VERSION "HNNBNNNYNNNNNNNNNNNNNNNNNNNNNNNNNNNNNNNNNN/4/%%%/4/'%**4NNN///"

NS_ :

BS_:

BU_: BAP_Tester BedienDisp_vo BedienSG_hi CGS DDA Gateway Gateway_PAG GurtMikrofon OTA_FC ZR_High ZR_LIMU ZR_MIB_TOP_ab_Gen3 ZR_Standard

BO_ 2589283609 UGDO_02: 8 Gateway
 SG_ UGDO_LED_Code_01 : 0|5@1+ (1.0,0.0) [0.0|31] ""  Vector__XXX
 SG_ UGDO_Function_01 : 5|3@1+ (1.0,0.0) [0.0|7] ""  Vector__XXX
 SG_ UGDO_Failure_Antenne : 8|1@1+ (1.0,0.0) [0.0|1] ""  Vector__XXX
 SG_ UGDO_Failure_Codierung : 9|1@1+ (1.0,0.0) [0.0|1] ""  Vector__XXX
 SG_ UGDO_Failure_Hardware : 10|1@1+ (1.0,0.0) [0.0|1] ""  Vector__XXX
 SG_ UGDO_ResponseError : 16|1@1+ (1.0,0.0) [0.0|1] ""  Vector__XXX
 SG_ UGDO_Channel_1 : 24|1@1+ (1.0,0.0) [0.0|1] ""  DDA
 SG_ UGDO_Channel_2 : 25|1@1+ (1.0,0.0) [0.0|1] ""  DDA
 SG_ UGDO_Channel_3 : 26|1@1+ (1.0,0.0) [0.0|1] ""  DDA
 SG_ UGDO_Channel_4 : 27|1@1+ (1.0,0.0) [0.0|1] ""  DDA
 SG_ UGDO_Channel_5 : 28|1@1+ (1.0,0.0) [0.0|1] ""  DDA
 SG_ UGDO_Channel_6 : 29|1@1+ (1.0,0.0) [0.0|1] ""  DDA
 SG_ UGDO_Channel_7 : 30|1@1+ (1.0,0.0) [0.0|1] ""  DDA
 SG_ UGDO_Channel_8 : 31|1@1+ (1.0,0.0) [0.0|1] ""  DDA
 SG_ UGDO_Channel_9 : 32|1@1+ (1.0,0.0) [0.0|1] ""  DDA
 SG_ UGDO_Channel_10 : 33|1@1+ (1.0,0.0) [0.0|1] ""  DDA
 SG_ UGDO_Channel_11 : 34|1@1+ (1.0,0.0) [0.0|1] ""  DDA
 SG_ UGDO_Channel_12 : 35|1@1+ (1.0,0.0) [0.0|1] ""  DDA
 SG_ UGDO_Channel_13 : 36|1@1+ (1.0,0.0) [0.0|1] ""  DDA
 SG_ UGDO_Channel_14 : 37|1@1+ (1.0,0.0) [0.0|1] ""  DDA
 SG_ UGDO_Channel_15 : 38|1@1+ (1.0,0.0) [0.0|1] ""  DDA
 SG_ UGDO_DoorState : 40|4@1+ (1.0,0.0) [0.0|15] ""  DDA,ZR_High

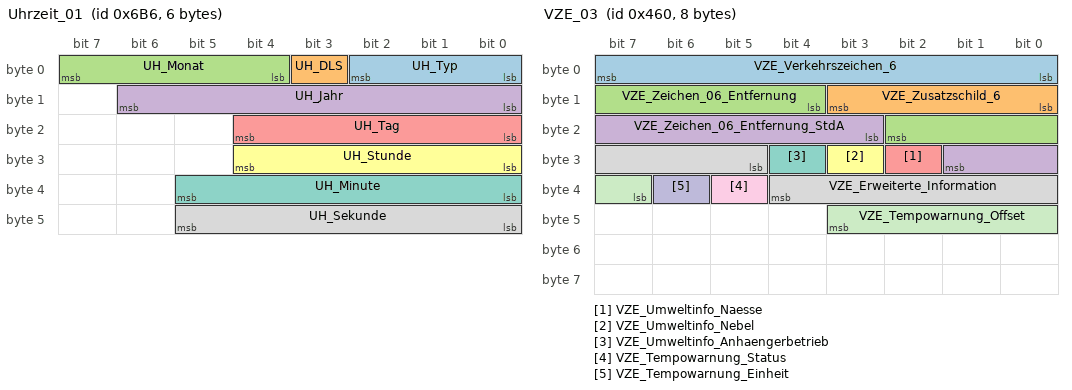
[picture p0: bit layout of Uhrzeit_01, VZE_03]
BO_ 1718 Uhrzeit_01: 6 Gateway
 SG_ UH_Typ : 0|3@1+ (1.0,0.0) [0.0|7] ""  BedienSG_hi,ZR_High
 SG_ UH_DLS : 3|1@1+ (1.0,0.0) [0.0|1] ""  BedienSG_hi,ZR_High
 SG_ UH_Monat : 4|4@1+ (1,0) [1|12] "Unit_Month"  Vector__XXX
 SG_ UH_Jahr : 8|7@1+ (1,2000) [2000|2127] "Unit_Year"  Vector__XXX
 SG_ UH_Tag : 16|5@1+ (1,0) [1|31] "Unit_Day"  Vector__XXX
 SG_ UH_Stunde : 24|5@1+ (1,0) [0|23] "Unit_Hours"  Vector__XXX
 SG_ UH_Minute : 32|6@1+ (1,0) [0|59] "Unit_Minut"  Vector__XXX
 SG_ UH_Sekunde : 40|6@1+ (1,0) [0|59] "Unit_Secon"  Vector__XXX

BO_ 995 Verdeck_01: 8 Gateway
 SG_ Verdeck_01_CRC : 0|8@1+ (1,0) [0|255] ""  Vector__XXX
 SG_ Verdeck_01_BZ : 8|4@1+ (1,0) [0|15] ""  Vector__XXX
 SG_ VS_VD_zu_ver : 16|1@1+ (1.0,0.0) [0.0|1] ""  ZR_High,ZR_LIMU,ZR_MIB_TOP_ab_Gen3,ZR_Standard
 SG_ VS_VD_entriegelt : 17|1@1+ (1.0,0.0) [0.0|1] ""  OTA_FC
 SG_ VS_VD_offen_ver : 18|1@1+ (1.0,0.0) [0.0|1] ""  OTA_FC,ZR_High,ZR_Standard
 SG_ VS_VD_Zwischenposition : 19|1@1+ (1.0,0.0) [0.0|1] ""  Vector__XXX
 SG_ VS_VD_Bew_auf : 20|1@1+ (1.0,0.0) [0.0|1] ""  Vector__XXX
 SG_ VS_VD_Bew_zu : 21|1@1+ (1.0,0.0) [0.0|1] ""  Vector__XXX
 SG_ VS_Verdeck_Anf : 22|1@1+ (1.0,0.0) [0.0|1] ""  Vector__XXX
 SG_ VS_Hardtop : 23|1@1+ (1.0,0.0) [0.0|1] ""  Vector__XXX
 SG_ VS_VD_Fehler : 24|1@1+ (1.0,0.0) [0.0|1] ""  Vector__XXX
 SG_ VS_Lampe_Blk : 25|1@1+ (1.0,0.0) [0.0|1] ""  Vector__XXX
 SG_ VS_Buzzer : 26|1@1+ (1.0,0.0) [0.0|1] ""  Vector__XXX
 SG_ VS_HD_sperren : 27|1@1+ (1.0,0.0) [0.0|1] ""  Vector__XXX
 SG_ VS_HHS_enable : 28|1@1+ (1.0,0.0) [0.0|1] ""  Vector__XXX
 SG_ VD_SpannungsAnf : 29|2@1+ (1.0,0.0) [0.0|3] ""  Vector__XXX
 SG_ VS_VDKD_auf : 31|1@1+ (1.0,0.0) [0.0|1] ""  Vector__XXX
 SG_ VS_FS_AutoHoch : 32|1@1+ (1.0,0.0) [0.0|1] ""  Vector__XXX
 SG_ VS_FS_AutoTief : 33|1@1+ (1.0,0.0) [0.0|1] ""  Vector__XXX
 SG_ VS_FS_ManHoch : 34|1@1+ (1.0,0.0) [0.0|1] ""  Vector__XXX
 SG_ VS_FS_ManTief : 35|1@1+ (1.0,0.0) [0.0|1] ""  Vector__XXX
 SG_ VS_BFS_AutoHoch : 36|1@1+ (1.0,0.0) [0.0|1] ""  Vector__XXX
 SG_ VS_BFS_AutoTief : 37|1@1+ (1.0,0.0) [0.0|1] ""  Vector__XXX
 SG_ VS_BFS_ManHoch : 38|1@1+ (1.0,0.0) [0.0|1] ""  Vector__XXX
 SG_ VS_BFS_ManTief : 39|1@1+ (1.0,0.0) [0.0|1] ""  Vector__XXX
 SG_ VS_HFS_AutoHoch : 40|1@1+ (1.0,0.0) [0.0|1] ""  Vector__XXX
 SG_ VS_HFS_AutoTief : 41|1@1+ (1.0,0.0) [0.0|1] ""  Vector__XXX
 SG_ VS_HFS_ManHoch : 42|1@1+ (1.0,0.0) [0.0|1] ""  Vector__XXX
 SG_ VS_HFS_ManTief : 43|1@1+ (1.0,0.0) [0.0|1] ""  Vector__XXX
 SG_ VS_HBFS_AutoHoch : 44|1@1+ (1.0,0.0) [0.0|1] ""  Vector__XXX
 SG_ VS_HBFS_AutoTief : 45|1@1+ (1.0,0.0) [0.0|1] ""  Vector__XXX
 SG_ VS_HBFS_ManHoch : 46|1@1+ (1.0,0.0) [0.0|1] ""  Vector__XXX
 SG_ VS_HBFS_ManTief : 47|1@1+ (1.0,0.0) [0.0|1] ""  Vector__XXX
 SG_ VS_FH_FT_Langhub : 49|1@1+ (1.0,0.0) [0.0|1] ""  Vector__XXX
 SG_ VS_Windschott_nicht_abgelegt : 50|1@1+ (1.0,0.0) [0.0|1] ""  Vector__XXX
 SG_ VS_FH_BT_Langhub : 51|1@1+ (1.0,0.0) [0.0|1] ""  Vector__XXX
 SG_ VS_FH_HFS_Langhub : 53|1@1+ (1.0,0.0) [0.0|1] ""  Vector__XXX
 SG_ VS_Heckschloss_auf : 54|1@1+ (1.0,0.0) [0.0|1] ""  Vector__XXX
 SG_ VS_FH_HBFS_Langhub : 55|1@1+ (1.0,0.0) [0.0|1] ""  Vector__XXX
 SG_ VSG_Meldungen : 56|6@1+ (1,0) [1|63] "Unit_None"  OTA_FC
 SG_ VS_StartStopp_Info : 62|2@1+ (1.0,0.0) [0.0|3] ""  Vector__XXX

BO_ 1716 VIN_01: 8 Gateway
 SG_ VIN_01_MUX M  : 0|2@1+ (1,0) [0|3] ""  BedienSG_hi,DDA,OTA_FC,ZR_High,ZR_LIMU,ZR_MIB_TOP_ab_Gen3,ZR_Standard
 SG_ KS_Geheimnis_1 m0  : 8|8@1+ (1,0) [0|255] ""  OTA_FC,ZR_High,ZR_LIMU,ZR_MIB_TOP_ab_Gen3,ZR_Standard
 SG_ VIN_4 m1  : 8|8@1+ (1,0) [0|255] ""  BedienSG_hi,DDA,OTA_FC,ZR_High,ZR_LIMU,ZR_MIB_TOP_ab_Gen3,ZR_Standard
 SG_ VIN_11 m2  : 8|8@1+ (1,0) [0|255] ""  BedienSG_hi,DDA,OTA_FC,ZR_High,ZR_LIMU,ZR_MIB_TOP_ab_Gen3,ZR_Standard
 SG_ KS_Geheimnis_2 m0  : 16|8@1+ (1,0) [0|255] ""  OTA_FC,ZR_High,ZR_LIMU,ZR_MIB_TOP_ab_Gen3,ZR_Standard
 SG_ VIN_5 m1  : 16|8@1+ (1,0) [0|255] ""  BedienSG_hi,DDA,OTA_FC,ZR_High,ZR_LIMU,ZR_MIB_TOP_ab_Gen3,ZR_Standard
 SG_ VIN_12 m2  : 16|8@1+ (1,0) [0|255] ""  BedienSG_hi,DDA,OTA_FC,ZR_High,ZR_LIMU,ZR_MIB_TOP_ab_Gen3,ZR_Standard
 SG_ KS_Geheimnis_3 m0  : 24|8@1+ (1,0) [0|255] ""  OTA_FC,ZR_High,ZR_LIMU,ZR_MIB_TOP_ab_Gen3,ZR_Standard
 SG_ VIN_6 m1  : 24|8@1+ (1,0) [0|255] ""  BedienSG_hi,DDA,OTA_FC,ZR_High,ZR_LIMU,ZR_MIB_TOP_ab_Gen3,ZR_Standard
 SG_ VIN_13 m2  : 24|8@1+ (1,0) [0|255] ""  BedienSG_hi,DDA,OTA_FC,ZR_High,ZR_LIMU,ZR_MIB_TOP_ab_Gen3,ZR_Standard
 SG_ KS_Geheimnis_4 m0  : 32|8@1+ (1,0) [0|255] ""  OTA_FC,ZR_High,ZR_LIMU,ZR_MIB_TOP_ab_Gen3,ZR_Standard
 SG_ VIN_7 m1  : 32|8@1+ (1,0) [0|255] ""  BedienSG_hi,DDA,OTA_FC,ZR_High,ZR_LIMU,ZR_MIB_TOP_ab_Gen3,ZR_Standard
 SG_ VIN_14 m2  : 32|8@1+ (1,0) [0|255] ""  BedienSG_hi,DDA,OTA_FC,ZR_High,ZR_LIMU,ZR_MIB_TOP_ab_Gen3,ZR_Standard
 SG_ VIN_1 m0  : 40|8@1+ (1,0) [0|255] ""  BedienSG_hi,DDA,OTA_FC,ZR_High,ZR_LIMU,ZR_MIB_TOP_ab_Gen3,ZR_Standard
 SG_ VIN_8 m1  : 40|8@1+ (1,0) [0|255] ""  BedienSG_hi,DDA,OTA_FC,ZR_High,ZR_LIMU,ZR_MIB_TOP_ab_Gen3,ZR_Standard
 SG_ VIN_15 m2  : 40|8@1+ (1,0) [0|255] ""  BedienSG_hi,DDA,OTA_FC,ZR_High,ZR_LIMU,ZR_MIB_TOP_ab_Gen3,ZR_Standard
 SG_ VIN_2 m0  : 48|8@1+ (1,0) [0|255] ""  BedienSG_hi,DDA,OTA_FC,ZR_High,ZR_LIMU,ZR_MIB_TOP_ab_Gen3,ZR_Standard
 SG_ VIN_9 m1  : 48|8@1+ (1,0) [0|255] ""  BedienSG_hi,DDA,OTA_FC,ZR_High,ZR_LIMU,ZR_MIB_TOP_ab_Gen3,ZR_Standard
 SG_ VIN_16 m2  : 48|8@1+ (1,0) [0|255] ""  BedienSG_hi,DDA,OTA_FC,ZR_High,ZR_LIMU,ZR_MIB_TOP_ab_Gen3,ZR_Standard
 SG_ VIN_3 m0  : 56|8@1+ (1,0) [0|255] ""  BedienSG_hi,DDA,OTA_FC,ZR_High,ZR_LIMU,ZR_MIB_TOP_ab_Gen3,ZR_Standard
 SG_ VIN_10 m1  : 56|8@1+ (1,0) [0|255] ""  BedienSG_hi,DDA,OTA_FC,ZR_High,ZR_LIMU,ZR_MIB_TOP_ab_Gen3,ZR_Standard
 SG_ VIN_17 m2  : 56|8@1+ (1,0) [0|255] ""  BedienSG_hi,DDA,OTA_FC,ZR_High,ZR_LIMU,ZR_MIB_TOP_ab_Gen3,ZR_Standard

BO_ 385 VZE_01: 8 Gateway
 SG_ VZE_Anzeigemodus : 0|2@1+ (1.0,0.0) [0.0|3] ""  ZR_High,ZR_LIMU,ZR_MIB_TOP_ab_Gen3
 SG_ VZE_Hinweistext : 2|3@1+ (1,0) [1|7] ""  ZR_High,ZR_LIMU,ZR_MIB_TOP_ab_Gen3
 SG_ VZE_Verkehrszeichen_Einheit : 8|1@1+ (1.0,0.0) [0.0|1] ""  ZR_High,ZR_LIMU,ZR_MIB_TOP_ab_Gen3
 SG_ VZE_Anzeigeunterdrueck_Zeichen_3 : 9|1@1+ (1.0,0.0) [0.0|1] ""  Vector__XXX
 SG_ VZE_Anzeigeunterdrueck_Zeichen_2 : 10|1@1+ (1.0,0.0) [0.0|1] ""  Vector__XXX
 SG_ VZE_Verkehrszeichen_1 : 11|8@1+ (1,0) [1|255] ""  OTA_FC,ZR_High,ZR_LIMU,ZR_MIB_TOP_ab_Gen3
 SG_ VZE_Verkehrszeichen_2 : 19|8@1+ (1,0) [1|255] ""  OTA_FC,ZR_High,ZR_LIMU,ZR_MIB_TOP_ab_Gen3
 SG_ VZE_Verkehrszeichen_3 : 27|8@1+ (1,0) [1|255] ""  OTA_FC,ZR_High,ZR_LIMU,ZR_MIB_TOP_ab_Gen3
 SG_ VZE_Warnung_Verkehrszeichen_1 : 35|1@1+ (1.0,0.0) [0.0|1] ""  ZR_High,ZR_LIMU,ZR_MIB_TOP_ab_Gen3
 SG_ VZE_Warnung_Verkehrszeichen_2 : 36|1@1+ (1.0,0.0) [0.0|1] ""  ZR_High,ZR_LIMU,ZR_MIB_TOP_ab_Gen3
 SG_ VZE_Warnung_Verkehrszeichen_3 : 37|1@1+ (1.0,0.0) [0.0|1] ""  ZR_High,ZR_LIMU,ZR_MIB_TOP_ab_Gen3
 SG_ VZE_Zusatzschild_1 : 38|4@1+ (1,0) [1|15] ""  ZR_High,ZR_LIMU,ZR_MIB_TOP_ab_Gen3
 SG_ VZE_Zusatzschild_2 : 42|4@1+ (1,0) [1|15] ""  ZR_High,ZR_LIMU,ZR_MIB_TOP_ab_Gen3
 SG_ VZE_Zusatzschild_3 : 46|4@1+ (1,0) [1|15] ""  ZR_High,ZR_LIMU,ZR_MIB_TOP_ab_Gen3
 SG_ VZE_Anzeigeunterdrueck_Zeichen_1 : 50|1@1+ (1.0,0.0) [0.0|1] ""  Vector__XXX
 SG_ VZE_Zeichen_01_KameraWied : 51|1@1+ (1.0,0.0) [0.0|1] ""  ZR_High,ZR_LIMU,ZR_MIB_TOP_ab_Gen3
 SG_ VZE_Zeichen_02_KameraWied : 52|1@1+ (1.0,0.0) [0.0|1] ""  ZR_High,ZR_LIMU,ZR_MIB_TOP_ab_Gen3
 SG_ VZE_Zeichen_03_KameraWied : 53|1@1+ (1.0,0.0) [0.0|1] ""  ZR_High,ZR_LIMU,ZR_MIB_TOP_ab_Gen3
 SG_ VZE_Zeichen_01_Kamera : 54|1@1+ (1.0,0.0) [0.0|1] ""  ZR_High,ZR_LIMU,ZR_MIB_TOP_ab_Gen3
 SG_ VZE_Zeichen_01_Karte : 55|1@1+ (1.0,0.0) [0.0|1] ""  ZR_High,ZR_LIMU,ZR_MIB_TOP_ab_Gen3
 SG_ VZE_Zeichen_01_Gesetz : 56|1@1+ (1.0,0.0) [0.0|1] ""  ZR_High,ZR_LIMU,ZR_MIB_TOP_ab_Gen3
 SG_ VZE_Zeichen_02_Kamera : 57|1@1+ (1.0,0.0) [0.0|1] ""  ZR_High,ZR_LIMU,ZR_MIB_TOP_ab_Gen3
 SG_ VZE_Zeichen_02_Karte : 58|1@1+ (1.0,0.0) [0.0|1] ""  ZR_High,ZR_LIMU,ZR_MIB_TOP_ab_Gen3
 SG_ VZE_Zeichen_02_Gesetz : 59|1@1+ (1.0,0.0) [0.0|1] ""  ZR_High,ZR_LIMU,ZR_MIB_TOP_ab_Gen3
 SG_ VZE_Zeichen_03_Kamera : 60|1@1+ (1.0,0.0) [0.0|1] ""  ZR_High,ZR_LIMU,ZR_MIB_TOP_ab_Gen3
 SG_ VZE_Zeichen_03_Karte : 61|1@1+ (1.0,0.0) [0.0|1] ""  ZR_High,ZR_LIMU,ZR_MIB_TOP_ab_Gen3
 SG_ VZE_Zeichen_03_Gesetz : 62|1@1+ (1.0,0.0) [0.0|1] ""  ZR_High,ZR_LIMU,ZR_MIB_TOP_ab_Gen3
 SG_ VZE_Gong : 63|1@1+ (1.0,0.0) [0.0|1] ""  ZR_High,ZR_LIMU,ZR_MIB_TOP_ab_Gen3

BO_ 668 VZE_02: 8 Gateway
 SG_ VZE_Anzeigeunterdrueck_Zeichen_5 : 8|1@1+ (1.0,0.0) [0.0|1] ""  Vector__XXX
 SG_ VZE_Zeichen_05_KameraWied : 9|1@1+ (1.0,0.0) [0.0|1] ""  ZR_High
 SG_ VZE_Zeichen_05_Kamera : 10|1@1+ (1.0,0.0) [0.0|1] ""  ZR_High
 SG_ VZE_Verkehrszeichen_4 : 11|8@1+ (1,0) [1|255] ""  OTA_FC,ZR_High,ZR_LIMU,ZR_MIB_TOP_ab_Gen3,ZR_Standard
 SG_ VZE_Verkehrszeichen_5 : 19|8@1+ (1,0) [1|255] ""  OTA_FC,ZR_High,ZR_LIMU,ZR_MIB_TOP_ab_Gen3,ZR_Standard
 SG_ VZE_Anhaenger_Vmax : 27|4@1+ (10,10) [10|140] "Unit_KiloMeterPerHour"  ZR_High
 SG_ VZE_Zeichen_04_Gesetz : 31|1@1+ (1.0,0.0) [0.0|1] ""  ZR_High
 SG_ VZE_Zeichen_04_Kamera : 32|1@1+ (1.0,0.0) [0.0|1] ""  ZR_High
 SG_ VZE_Zeichen_04_KameraWied : 33|1@1+ (1.0,0.0) [0.0|1] ""  ZR_High
 SG_ VZE_Zeichen_04_Karte : 34|1@1+ (1.0,0.0) [0.0|1] ""  ZR_High
 SG_ VZE_Warnung_Verkehrszeichen_4 : 35|1@1+ (1.0,0.0) [0.0|1] ""  ZR_High
 SG_ VZE_Warnung_Verkehrszeichen_5 : 36|1@1+ (1.0,0.0) [0.0|1] ""  ZR_High
 SG_ VZE_Zeichen_05_Gesetz : 37|1@1+ (1.0,0.0) [0.0|1] ""  ZR_High
 SG_ VZE_Zusatzschild_4 : 38|4@1+ (1,0) [1|15] ""  ZR_High
 SG_ VZE_Zusatzschild_5 : 42|4@1+ (1,0) [1|15] ""  ZR_High
 SG_ VZE_Baustelle : 46|2@1+ (1.0,0.0) [0.0|3] ""  ZR_High
 SG_ VZE_Zeichen_05_Karte : 48|1@1+ (1.0,0.0) [0.0|1] ""  ZR_High
 SG_ VZE_Zeichen_05_Entfernung : 49|7@1+ (1,0) [1|127] "Unit_Meter"  ZR_High
 SG_ VZE_Zeichen_05_Entfernung_StdA : 56|7@1+ (1,0) [1|127] "Unit_Meter"  ZR_High
 SG_ VZE_Anzeigeunterdrueck_Zeichen_4 : 63|1@1+ (1.0,0.0) [0.0|1] ""  Vector__XXX

BO_ 1120 VZE_03: 8 Gateway
 SG_ VZE_Verkehrszeichen_6 : 0|8@1+ (1,0) [1|255] "Unit_None"  ZR_High,ZR_LIMU,ZR_MIB_TOP_ab_Gen3
 SG_ VZE_Zusatzschild_6 : 8|4@1+ (1,0) [1|15] ""  ZR_High,ZR_LIMU,ZR_MIB_TOP_ab_Gen3
 SG_ VZE_Zeichen_06_Entfernung : 12|7@1+ (1,0) [1|127] "Unit_Meter"  ZR_High
 SG_ VZE_Zeichen_06_Entfernung_StdA : 19|7@1+ (1,0) [1|127] "Unit_Meter"  ZR_High
 SG_ VZE_Umweltinfo_Naesse : 26|1@1+ (1.0,0.0) [0.0|1] ""  ZR_High,ZR_LIMU,ZR_MIB_TOP_ab_Gen3
 SG_ VZE_Umweltinfo_Nebel : 27|1@1+ (1.0,0.0) [0.0|1] ""  ZR_High,ZR_LIMU,ZR_MIB_TOP_ab_Gen3
 SG_ VZE_Umweltinfo_Anhaengerbetrieb : 28|1@1+ (1.0,0.0) [0.0|1] ""  ZR_High,ZR_LIMU,ZR_MIB_TOP_ab_Gen3
 SG_ VZE_Erweiterte_Information : 29|8@1+ (1,0) [1|255] "Unit_None"  ZR_High
 SG_ VZE_Tempowarnung_Status : 37|1@1+ (1.0,0.0) [0.0|1] ""  OTA_FC
 SG_ VZE_Tempowarnung_Einheit : 38|1@1+ (1.0,0.0) [0.0|1] ""  Vector__XXX
 SG_ VZE_Tempowarnung_Offset : 39|5@1+ (1,0) [1|31] ""  Vector__XXX

BO_ 916 WBA_03: 8 Gateway
 SG_ WBA_03_CRC : 0|8@1+ (1,0) [0|255] ""  Vector__XXX
 SG_ WBA_03_BZ : 8|4@1+ (1,0) [0|15] ""  Vector__XXX
 SG_ WBA_Fahrstufe_02 : 12|4@1+ (1.0,0.0) [0.0|15] ""  ZR_High,ZR_LIMU,ZR_MIB_TOP_ab_Gen3,ZR_Standard
 SG_ WBA_ZielFahrstufe : 16|4@1+ (1.0,0.0) [0.0|15] ""  Vector__XXX
 SG_ WBA_GE_Warnung_02 : 20|4@1+ (1.0,0.0) [0.0|15] ""  Vector__XXX
 SG_ WBA_eing_Gang_02 : 24|4@1+ (1.0,0.0) [0.0|15] ""  ZR_High,ZR_LIMU,ZR_MIB_TOP_ab_Gen3,ZR_Standard
 SG_ WBA_GE_Texte : 28|3@1+ (1.0,0.0) [0.0|7] ""  Vector__XXX
 SG_ WBA_Segeln_aktiv : 31|1@1+ (1.0,0.0) [0.0|1] ""  OTA_FC,ZR_High,ZR_LIMU,ZR_MIB_TOP_ab_Gen3,ZR_Standard
 SG_ WBA_Schaltschema : 32|5@1+ (1.0,0.0) [0.0|31] ""  Vector__XXX
 SG_ WBA_GE_Zusatzwarnungen : 37|3@1+ (1.0,0.0) [0.0|7] ""  ZR_High,ZR_LIMU,ZR_MIB_TOP_ab_Gen3
 SG_ GE_Sollgang : 40|4@1+ (1.0,0.0) [0.0|15] ""  ZR_High,ZR_LIMU,ZR_MIB_TOP_ab_Gen3,ZR_Standard
 SG_ GE_Tipschaltempf_verfuegbar : 44|1@1+ (1.0,0.0) [0.0|1] ""  ZR_High,ZR_Standard
 SG_ WBA_GE_Texte_02 : 45|3@1+ (1.0,0.0) [0.0|7] ""  OTA_FC
 SG_ WBA_GE_Texte_03 : 48|4@1+ (1.0,0.0) [0.0|15] ""  Vector__XXX
 SG_ WBA_Blinken : 54|1@1+ (1.0,0.0) [0.0|1] ""  Vector__XXX
 SG_ GE_Wiederstart_Anz_Std : 55|1@1+ (1.0,0.0) [0.0|1] ""  Vector__XXX
 SG_ GE_Stoppverbot_Anz_01 : 56|1@1+ (1.0,0.0) [0.0|1] ""  Vector__XXX
 SG_ GE_Stoppverbot_Anz_02 : 57|1@1+ (1.0,0.0) [0.0|1] ""  Vector__XXX
 SG_ GE_Stoppverbot_Anz_03 : 58|1@1+ (1.0,0.0) [0.0|1] ""  Vector__XXX
 SG_ GE_Stoppverbot_Anz_04 : 59|1@1+ (1.0,0.0) [0.0|1] ""  Vector__XXX
 SG_ GE_Stoppverbot_Anz_05 : 60|1@1+ (1.0,0.0) [0.0|1] ""  Vector__XXX
 SG_ GE_Stoppverbot_Anz_06 : 61|1@1+ (1.0,0.0) [0.0|1] ""  Vector__XXX
 SG_ GE_Stoppverbot_Anz_07 : 62|1@1+ (1.0,0.0) [0.0|1] ""  Vector__XXX
 SG_ GE_Stoppverbot_Anz_Std : 63|1@1+ (1.0,0.0) [0.0|1] ""  Vector__XXX

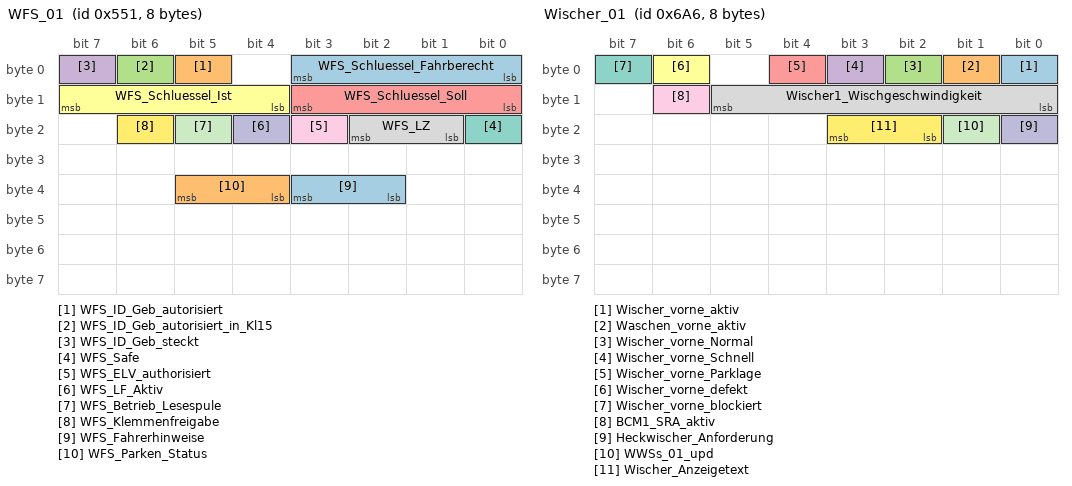
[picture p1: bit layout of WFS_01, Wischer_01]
BO_ 1361 WFS_01: 8 Gateway
 SG_ WFS_Schluessel_Fahrberecht : 0|4@1+ (1.0,0.0) [0.0|15] ""  ZR_High,ZR_LIMU,ZR_MIB_TOP_ab_Gen3,ZR_Standard
 SG_ WFS_ID_Geb_autorisiert : 5|1@1+ (1.0,0.0) [0.0|1] ""  ZR_High
 SG_ WFS_ID_Geb_autorisiert_in_Kl15 : 6|1@1+ (1.0,0.0) [0.0|1] ""  Vector__XXX
 SG_ WFS_ID_Geb_steckt : 7|1@1+ (1.0,0.0) [0.0|1] ""  ZR_High
 SG_ WFS_Schluessel_Soll : 8|4@1+ (1.0,0.0) [0.0|15] ""  ZR_High,ZR_LIMU,ZR_MIB_TOP_ab_Gen3,ZR_Standard
 SG_ WFS_Schluessel_Ist : 12|4@1+ (1.0,0.0) [0.0|15] ""  ZR_High,ZR_LIMU,ZR_MIB_TOP_ab_Gen3,ZR_Standard
 SG_ WFS_Safe : 16|1@1+ (1.0,0.0) [0.0|1] ""  Vector__XXX
 SG_ WFS_LZ : 17|2@1+ (1.0,0.0) [0.0|3] ""  Vector__XXX
 SG_ WFS_ELV_authorisiert : 19|1@1+ (1.0,0.0) [0.0|1] ""  Vector__XXX
 SG_ WFS_LF_Aktiv : 20|1@1+ (1.0,0.0) [0.0|1] ""  Vector__XXX
 SG_ WFS_Betrieb_Lesespule : 21|1@1+ (1.0,0.0) [0.0|1] ""  Vector__XXX
 SG_ WFS_Klemmenfreigabe : 22|1@1+ (1.0,0.0) [0.0|1] ""  Vector__XXX
 SG_ WFS_Fahrerhinweise : 34|2@1+ (1.0,0.0) [0.0|3] ""  Vector__XXX
 SG_ WFS_Parken_Status : 36|2@1+ (1.0,0.0) [0.0|3] ""  Vector__XXX

BO_ 1702 Wischer_01: 8 Gateway
 SG_ Wischer_vorne_aktiv : 0|1@1+ (1.0,0.0) [0.0|1] ""  OTA_FC,ZR_High
 SG_ Waschen_vorne_aktiv : 1|1@1+ (1.0,0.0) [0.0|1] ""  ZR_High
 SG_ Wischer_vorne_Normal : 2|1@1+ (1.0,0.0) [0.0|1] ""  ZR_High
 SG_ Wischer_vorne_Schnell : 3|1@1+ (1.0,0.0) [0.0|1] ""  ZR_High
 SG_ Wischer_vorne_Parklage : 4|1@1+ (1.0,0.0) [0.0|1] ""  Vector__XXX
 SG_ Wischer_vorne_defekt : 6|1@1+ (1.0,0.0) [0.0|1] ""  ZR_High
 SG_ Wischer_vorne_blockiert : 7|1@1+ (1.0,0.0) [0.0|1] ""  Vector__XXX
 SG_ Wischer1_Wischgeschwindigkeit : 8|6@1+ (1,9) [10|70] "Unit_MinutInver"  ZR_High
 SG_ BCM1_SRA_aktiv : 14|1@1+ (1.0,0.0) [0.0|1] ""  OTA_FC,ZR_High
 SG_ Heckwischer_Anforderung : 16|1@1+ (1.0,0.0) [0.0|1] ""  ZR_High
 SG_ WWSs_01_upd : 17|1@1+ (1.0,0.0) [0.0|1] ""  Vector__XXX
 SG_ Wischer_Anzeigetext : 18|2@1+ (1.0,0.0) [0.0|3] ""  Vector__XXX

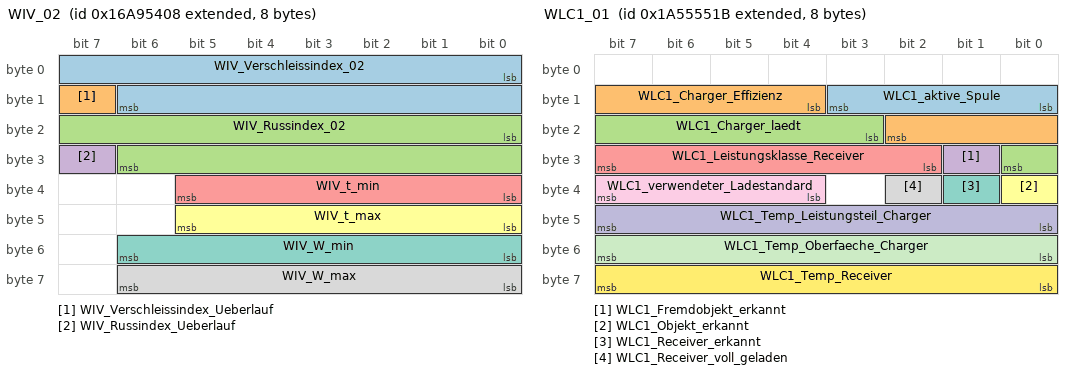
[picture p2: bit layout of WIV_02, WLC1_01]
BO_ 2527679496 WIV_02: 8 Gateway
 SG_ WIV_Verschleissindex_02 : 0|15@1+ (0.001,0) [0.000|32.766] ""  ZR_High
 SG_ WIV_Verschleissindex_Ueberlauf : 15|1@1+ (1.0,0.0) [0.0|1] ""  ZR_High
 SG_ WIV_Russindex_02 : 16|15@1+ (0.001,0) [0.000|32.766] ""  ZR_High
 SG_ WIV_Russindex_Ueberlauf : 31|1@1+ (1.0,0.0) [0.0|1] ""  ZR_High
 SG_ WIV_t_min : 32|6@1+ (1,0) [0|63] "Unit_Month"  ZR_High
 SG_ WIV_t_max : 40|6@1+ (1,0) [0|63] "Unit_Month"  ZR_High
 SG_ WIV_W_min : 48|7@1+ (1000,0) [0|127000] "Unit_KiloMeter"  ZR_High
 SG_ WIV_W_max : 56|7@1+ (1000,0) [0|127000] "Unit_KiloMeter"  ZR_High

BO_ 2589283611 WLC1_01: 8 ZR_High
 SG_ WLC1_aktive_Spule : 8|4@1+ (1,0) [0|10] ""  Gateway,Gateway_PAG
 SG_ WLC1_Charger_Effizienz : 12|7@1+ (1,0) [0|100] "Unit_PerCent"  Gateway,Gateway_PAG
 SG_ WLC1_Charger_laedt : 19|6@1+ (0.1,0) [0.0|5.0] "Unit_Watt"  Gateway,Gateway_PAG
 SG_ WLC1_Fremdobjekt_erkannt : 25|1@1+ (1.0,0.0) [0.0|1] ""  Gateway,Gateway_PAG
 SG_ WLC1_Leistungsklasse_Receiver : 26|6@1+ (0.1,0) [0.0|5.0] "Unit_Watt"  Gateway,Gateway_PAG
 SG_ WLC1_Objekt_erkannt : 32|1@1+ (1.0,0.0) [0.0|1] ""  Gateway,Gateway_PAG
 SG_ WLC1_Receiver_erkannt : 33|1@1+ (1.0,0.0) [0.0|1] ""  Gateway,Gateway_PAG
 SG_ WLC1_Receiver_voll_geladen : 34|1@1+ (1.0,0.0) [0.0|1] ""  Gateway,Gateway_PAG
 SG_ WLC1_verwendeter_Ladestandard : 36|4@1+ (1,0) [0|15] ""  Gateway,Gateway_PAG
 SG_ WLC1_Temp_Leistungsteil_Charger : 40|8@1+ (1,-58) [-58|120] "Unit_DegreCelsi"  Gateway,Gateway_PAG
 SG_ WLC1_Temp_Oberfaeche_Charger : 48|8@1+ (1,-58) [-58|120] "Unit_DegreCelsi"  Gateway,Gateway_PAG
 SG_ WLC1_Temp_Receiver : 56|8@1+ (1,-58) [-58|120] "Unit_DegreCelsi"  Gateway,Gateway_PAG

BO_ 2617014016 XCP_BedienDisp_vo_CRO_01: 8 Vector__XXX
 SG_ XCP_BedienDisp_vo_CRO_01_Data : 0|64@1+ (1,0) [0|1] ""  BedienDisp_vo

BO_ 2617014017 XCP_BedienDisp_vo_DTO_01: 8 BedienDisp_vo
 SG_ XCP_BedienDisp_vo_DTO_01_Data : 0|64@1+ (1,0) [0|1] ""  Vector__XXX

BO_ 2617024256 XCP_BedienSG_hi_CRO_01: 8 Vector__XXX
 SG_ XCP_BedienSG_hi_CRO_01_Data : 0|64@1+ (1,0) [0|1] ""  BedienSG_hi

BO_ 2617024257 XCP_BedienSG_hi_DTO_01: 8 BedienSG_hi
 SG_ XCP_BedienSG_hi_DTO_01_Data : 0|64@1+ (1,0) [0|1] ""  Vector__XXX

BO_ 2617104128 XCP_DDA_CRO_01: 8 Vector__XXX
 SG_ XCP_DDA_CRO_01_Data : 0|64@1+ (1,0) [0|1] ""  DDA

BO_ 2617104129 XCP_DDA_DTO_01: 8 DDA
 SG_ XCP_DDA_DTO_01_Data : 0|64@1+ (1,0) [0|1] ""  Vector__XXX

BO_ 2617220608 XCP_Info_El_CRO_01: 8 Vector__XXX
 SG_ XCP_Info_El_CRO_01_Data : 0|64@1+ (1,0) [0|1] ""  ZR_High,ZR_MIB_TOP_ab_Gen3,ZR_Standard

BO_ 2617220609 XCP_Info_El_DTO_01: 8 ZR_High
 SG_ XCP_Info_El_DTO_01_Data : 0|64@1+ (1,0) [0|1] ""  Vector__XXX

BO_ 1140 Zentralrechner_01: 8 ZR_High
 SG_ ZR_State_DU_1 : 0|3@1+ (1.0,0.0) [0.0|7] ""  Gateway,Gateway_PAG
 SG_ ZR_State_DU_2 : 3|3@1+ (1.0,0.0) [0.0|7] ""  Gateway,Gateway_PAG
 SG_ ZR_State_DU_3 : 6|3@1+ (1.0,0.0) [0.0|7] ""  Gateway,Gateway_PAG
 SG_ ZR_WecktGesp : 9|1@1+ (1.0,0.0) [0.0|1] ""  Gateway,Gateway_PAG
 SG_ MMI_State : 10|6@1+ (1.0,0.0) [0.0|63] ""  Gateway,Gateway_PAG
 SG_ ZR_DimOffs_DU_1 : 16|4@1+ (1,-5) [-5|5] "Unit_None"  Gateway,Gateway_PAG
 SG_ ZR_DimOffs_DU_2 : 20|4@1+ (1,-5) [-5|5] "Unit_None"  Gateway,Gateway_PAG
 SG_ ZR_DimOffs_DU_3 : 24|4@1+ (1,-5) [-5|5] "Unit_None"  Gateway,Gateway_PAG
 SG_ SI_ICAN : 28|1@1+ (1.0,0.0) [0.0|1] ""  Gateway,Gateway_PAG
 SG_ ZR_Lenkerposition : 29|1@1+ (1.0,0.0) [0.0|1] ""  Gateway,Gateway_PAG
 SG_ WLC1_Systemzustand : 30|1@1+ (1.0,0.0) [0.0|1] ""  Gateway,Gateway_PAG
 SG_ WLC2_Systemzustand : 31|1@1+ (1.0,0.0) [0.0|1] ""  Gateway,Gateway_PAG
 SG_ ZR_SpannungSaeule : 35|1@1+ (1.0,0.0) [0.0|1] ""  Gateway,Gateway_PAG,OTA_FC
 SG_ ZR_LeistungSaeule : 36|2@1+ (1.0,0.0) [0.0|3] ""  Gateway,Gateway_PAG,OTA_FC
 SG_ ZR_SOCSaeule : 41|7@1+ (1,0) [0|100] "Unit_PerCent"  Gateway,Gateway_PAG
 SG_ ZR_State_DU_4 : 48|3@1+ (1.0,0.0) [0.0|7] ""  Gateway,Gateway_PAG
 SG_ ZR_DimOffs_DU_4 : 51|4@1+ (1,-5) [-5|5] "Unit_None"  Gateway,Gateway_PAG
 SG_ ZR_t_naechsteLadung : 56|8@1+ (1,0) [0|255] "Unit_Minut"  Gateway,Gateway_PAG,OTA_FC

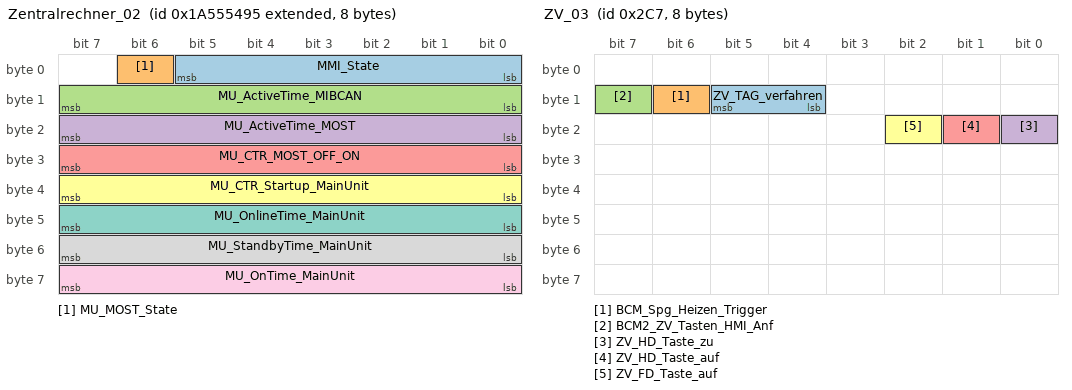
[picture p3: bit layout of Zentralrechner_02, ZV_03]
BO_ 2589283477 Zentralrechner_02: 8 ZR_High
 SG_ MMI_State : 0|6@1+ (1.0,0.0) [0.0|63] ""  Gateway,Gateway_PAG
 SG_ MU_MOST_State : 6|1@1+ (1.0,0.0) [0.0|1] ""  Gateway,Gateway_PAG
 SG_ MU_ActiveTime_MIBCAN : 8|8@1+ (0.1,0) [0.0|25.5] "Unit_Hours"  Gateway,Gateway_PAG
 SG_ MU_ActiveTime_MOST : 16|8@1+ (0.1,0) [0.0|25.5] "Unit_Hours"  Gateway,Gateway_PAG
 SG_ MU_CTR_MOST_OFF_ON : 24|8@1+ (1,0) [0|255] ""  Gateway,Gateway_PAG
 SG_ MU_CTR_Startup_MainUnit : 32|8@1+ (1,0) [0|255] ""  Gateway,Gateway_PAG
 SG_ MU_OnlineTime_MainUnit : 40|8@1+ (0.1,0) [0.0|25.5] "Unit_Hours"  Gateway,Gateway_PAG
 SG_ MU_StandbyTime_MainUnit : 48|8@1+ (0.1,0) [0.0|25.5] "Unit_Hours"  Gateway,Gateway_PAG
 SG_ MU_OnTime_MainUnit : 56|8@1+ (0.1,0) [0.0|25.5] "Unit_Hours"  Gateway,Gateway_PAG

BO_ 2527679655 Zentralrechner_03: 8 ZR_High
 SG_ ZR_SOC_Weiterfahrt : 51|7@1+ (1,0) [0|100] "Unit_PerCent"  Gateway,Gateway_PAG
 SG_ MMI_StartupAnimation : 61|3@1+ (1.0,0.0) [0.0|7] ""  Gateway,Gateway_PAG

BO_ 389 ZFH_01: 8 Gateway
 SG_ ZFH_FS_ManHoch : 0|1@1+ (1.0,0.0) [0.0|1] ""  ZR_High
 SG_ ZFH_FS_AutoHoch : 1|1@1+ (1.0,0.0) [0.0|1] ""  ZR_High
 SG_ ZFH_FS_ManTief : 2|1@1+ (1.0,0.0) [0.0|1] ""  ZR_High
 SG_ ZFH_FS_AutoTief : 3|1@1+ (1.0,0.0) [0.0|1] ""  ZR_High
 SG_ ZFH_BFS_ManHoch : 4|1@1+ (1.0,0.0) [0.0|1] ""  ZR_High
 SG_ ZFH_BFS_AutoHoch : 5|1@1+ (1.0,0.0) [0.0|1] ""  ZR_High
 SG_ ZFH_BFS_ManTief : 6|1@1+ (1.0,0.0) [0.0|1] ""  ZR_High
 SG_ ZFH_BFS_AutoTief : 7|1@1+ (1.0,0.0) [0.0|1] ""  ZR_High
 SG_ ZFH_HFS_ManHoch : 8|1@1+ (1.0,0.0) [0.0|1] ""  ZR_High
 SG_ ZFH_HFS_AutoHoch : 9|1@1+ (1.0,0.0) [0.0|1] ""  ZR_High
 SG_ ZFH_HFS_ManTief : 10|1@1+ (1.0,0.0) [0.0|1] ""  ZR_High
 SG_ ZFH_HFS_AutoTief : 11|1@1+ (1.0,0.0) [0.0|1] ""  ZR_High
 SG_ ZFH_HBFS_ManHoch : 12|1@1+ (1.0,0.0) [0.0|1] ""  ZR_High
 SG_ ZFH_HBFS_AutoHoch : 13|1@1+ (1.0,0.0) [0.0|1] ""  ZR_High
 SG_ ZFH_HBFS_ManTief : 14|1@1+ (1.0,0.0) [0.0|1] ""  ZR_High
 SG_ ZFH_HBFS_AutoTief : 15|1@1+ (1.0,0.0) [0.0|1] ""  ZR_High
 SG_ ZFH_zentral_zu : 28|1@1+ (1.0,0.0) [0.0|1] ""  ZR_High
 SG_ ZFH_zentral_auf : 29|1@1+ (1.0,0.0) [0.0|1] ""  ZR_High
 SG_ Krypt_Signatur : 48|11@1+ (1,0) [0|2047] ""  Vector__XXX
 SG_ Krypt_Schluesselschalter_auf : 59|1@1+ (1.0,0.0) [0.0|1] ""  ZR_High
 SG_ Krypt_Schluesselschalter_zu : 60|1@1+ (1.0,0.0) [0.0|1] ""  ZR_High

BO_ 392 ZFH_BFS_01: 8 Gateway
 SG_ BT_FH_BT_ManHoch : 0|1@1+ (1.0,0.0) [0.0|1] ""  ZR_High
 SG_ BT_FH_BT_AutoHoch : 1|1@1+ (1.0,0.0) [0.0|1] ""  ZR_High
 SG_ BT_FH_BT_ManTief : 2|1@1+ (1.0,0.0) [0.0|1] ""  ZR_High
 SG_ BT_FH_BT_AutoTief : 3|1@1+ (1.0,0.0) [0.0|1] ""  ZR_High
 SG_ BT_FH_FT_ManHoch : 4|1@1+ (1.0,0.0) [0.0|1] ""  ZR_High
 SG_ BT_FH_FT_AutoHoch : 5|1@1+ (1.0,0.0) [0.0|1] ""  ZR_High
 SG_ BT_FH_FT_ManTief : 6|1@1+ (1.0,0.0) [0.0|1] ""  ZR_High
 SG_ BT_FH_FT_AutoTief : 7|1@1+ (1.0,0.0) [0.0|1] ""  ZR_High
 SG_ BT_FH_HFS_ManHoch : 8|1@1+ (1.0,0.0) [0.0|1] ""  ZR_High
 SG_ BT_FH_HFS_AutoHoch : 9|1@1+ (1.0,0.0) [0.0|1] ""  ZR_High
 SG_ BT_FH_HFS_ManTief : 10|1@1+ (1.0,0.0) [0.0|1] ""  ZR_High
 SG_ BT_FH_HFS_AutoTief : 11|1@1+ (1.0,0.0) [0.0|1] ""  ZR_High
 SG_ BT_FH_HBFS_ManHoch : 12|1@1+ (1.0,0.0) [0.0|1] ""  ZR_High
 SG_ BT_FH_HBFS_AutoHoch : 13|1@1+ (1.0,0.0) [0.0|1] ""  ZR_High
 SG_ BT_FH_HBFS_ManTief : 14|1@1+ (1.0,0.0) [0.0|1] ""  ZR_High
 SG_ BT_FH_HBFS_AutoTief : 15|1@1+ (1.0,0.0) [0.0|1] ""  ZR_High
 SG_ BT_SP_hoch : 16|1@1+ (1.0,0.0) [0.0|1] ""  ZR_High
 SG_ BT_SP_tief : 17|1@1+ (1.0,0.0) [0.0|1] ""  ZR_High
 SG_ BT_SP_links : 18|1@1+ (1.0,0.0) [0.0|1] ""  ZR_High
 SG_ BT_SP_rechts : 19|1@1+ (1.0,0.0) [0.0|1] ""  ZR_High
 SG_ BT_SP_Garagenstellung : 20|1@1+ (1.0,0.0) [0.0|1] ""  ZR_High
 SG_ BT_SP_Fahrstellung : 21|1@1+ (1.0,0.0) [0.0|1] ""  ZR_High
 SG_ BT_FH_zentral_zu : 28|1@1+ (1.0,0.0) [0.0|1] ""  ZR_High
 SG_ BT_FH_zentral_auf : 29|1@1+ (1.0,0.0) [0.0|1] ""  ZR_High

BO_ 388 ZV_01: 8 Gateway
 SG_ ZV_01_CRC : 0|8@1+ (1,0) [0|255] ""  Vector__XXX
 SG_ ZV_01_BZ : 8|4@1+ (1,0) [0|15] ""  Vector__XXX
 SG_ ZV_FT_verriegeln : 12|1@1+ (1.0,0.0) [0.0|1] ""  ZR_High
 SG_ ZV_FT_entriegeln : 13|1@1+ (1.0,0.0) [0.0|1] ""  ZR_High
 SG_ ZV_BT_verriegeln : 14|1@1+ (1.0,0.0) [0.0|1] ""  ZR_High
 SG_ ZV_BT_entriegeln : 15|1@1+ (1.0,0.0) [0.0|1] ""  ZR_High
 SG_ ZV_HFS_verriegeln : 16|1@1+ (1.0,0.0) [0.0|1] ""  ZR_High
 SG_ ZV_HFS_entriegeln : 17|1@1+ (1.0,0.0) [0.0|1] ""  ZR_High
 SG_ ZV_HBFS_verriegeln : 18|1@1+ (1.0,0.0) [0.0|1] ""  ZR_High
 SG_ ZV_HBFS_entriegeln : 19|1@1+ (1.0,0.0) [0.0|1] ""  ZR_High
 SG_ ZV_zentral_safen : 20|1@1+ (1.0,0.0) [0.0|1] ""  ZR_High
 SG_ ZV_zentral_entsafen : 21|1@1+ (1.0,0.0) [0.0|1] ""  ZR_High
 SG_ ZV_Spg_Anklappen : 22|1@1+ (1.0,0.0) [0.0|1] ""  ZR_High
 SG_ ZV_Softtouch_betaetigt : 23|1@1+ (1.0,0.0) [0.0|1] ""  ZR_High
 SG_ ZV_LED_Steuerung : 24|1@1+ (1.0,0.0) [0.0|1] ""  ZR_High
 SG_ ZV_LED_Uebernahme : 25|1@1+ (1.0,0.0) [0.0|1] ""  ZR_High
 SG_ ZV_auf_FT : 26|1@1+ (1.0,0.0) [0.0|1] ""  ZR_High
 SG_ ZV_zu_FT : 27|1@1+ (1.0,0.0) [0.0|1] ""  ZR_High
 SG_ ZV_auf_BT : 28|1@1+ (1.0,0.0) [0.0|1] ""  ZR_High
 SG_ ZV_zu_BT : 29|1@1+ (1.0,0.0) [0.0|1] ""  ZR_High
 SG_ ZV_auf_Kessy : 30|1@1+ (1.0,0.0) [0.0|1] ""  ZR_High
 SG_ ZV_zu_Kessy : 31|1@1+ (1.0,0.0) [0.0|1] ""  ZR_High
 SG_ ZV_auf_Funk : 32|1@1+ (1.0,0.0) [0.0|1] ""  ZR_High
 SG_ ZV_zu_Funk : 33|1@1+ (1.0,0.0) [0.0|1] ""  ZR_High
 SG_ VIP_Sensor_betaetigt : 34|1@1+ (1.0,0.0) [0.0|1] ""  ZR_High
 SG_ VIP_Freigabe : 35|1@1+ (1.0,0.0) [0.0|1] ""  Vector__XXX
 SG_ ZV_zu_Zeitl_Nachverr : 36|1@1+ (1.0,0.0) [0.0|1] ""  ZR_High
 SG_ ZV_HSK_entriegeln : 37|1@1+ (1.0,0.0) [0.0|1] ""  ZR_High
 SG_ ZV_HSK_verriegeln : 38|1@1+ (1.0,0.0) [0.0|1] ""  ZR_High
 SG_ ZV_Verdeck_zu : 39|1@1+ (1.0,0.0) [0.0|1] ""  ZR_High
 SG_ ZV_Verdeck_auf : 40|1@1+ (1.0,0.0) [0.0|1] ""  ZR_High
 SG_ FH_FT_hoch : 41|1@1+ (1.0,0.0) [0.0|1] ""  ZR_High
 SG_ FH_FT_tief : 42|1@1+ (1.0,0.0) [0.0|1] ""  ZR_High
 SG_ FH_BT_hoch : 43|1@1+ (1.0,0.0) [0.0|1] ""  ZR_High
 SG_ FH_BT_tief : 44|1@1+ (1.0,0.0) [0.0|1] ""  ZR_High
 SG_ FH_HFS_hoch : 45|1@1+ (1.0,0.0) [0.0|1] ""  ZR_High
 SG_ FH_HFS_tief : 46|1@1+ (1.0,0.0) [0.0|1] ""  ZR_High
 SG_ FH_HBFS_hoch : 47|1@1+ (1.0,0.0) [0.0|1] ""  ZR_High
 SG_ FH_HBFS_tief : 48|1@1+ (1.0,0.0) [0.0|1] ""  ZR_High
 SG_ BCM_Spg_Synchron : 49|1@1+ (1.0,0.0) [0.0|1] ""  Vector__XXX
 SG_ BCM_BF_Spg_Absenkung : 50|1@1+ (1.0,0.0) [0.0|1] ""  Vector__XXX
 SG_ ZV_Signatur : 51|11@1+ (1,0) [0|2047] ""  Vector__XXX
 SG_ ZV_entriegeln_Anf : 62|1@1+ (1.0,0.0) [0.0|1] ""  Vector__XXX
 SG_ ZV_auto_Ansteuerung : 63|1@1+ (1.0,0.0) [0.0|1] ""  ZR_High

BO_ 1411 ZV_02: 8 Gateway
 SG_ BCM_FH_Freigabe : 12|1@1+ (1.0,0.0) [0.0|1] ""  BedienDisp_vo
 SG_ BCM_Komfortfkt_Freigabe : 13|1@1+ (1.0,0.0) [0.0|1] ""  Vector__XXX
 SG_ BCM_HSK_Freigabe : 14|1@1+ (1.0,0.0) [0.0|1] ""  Vector__XXX
 SG_ BCM_Verdeck_Freigabe : 15|1@1+ (1.0,0.0) [0.0|1] ""  ZR_High
 SG_ ZV_verriegelt_intern_ist : 16|1@1+ (1.0,0.0) [0.0|1] ""  DDA,OTA_FC,ZR_High
 SG_ ZV_verriegelt_extern_ist : 17|1@1+ (1.0,0.0) [0.0|1] ""  DDA,OTA_FC,ZR_High
 SG_ ZV_verriegelt_intern_soll : 18|1@1+ (1.0,0.0) [0.0|1] ""  ZR_High
 SG_ ZV_verriegelt_extern_soll : 19|1@1+ (1.0,0.0) [0.0|1] ""  OTA_FC,ZR_High,ZR_LIMU,ZR_MIB_TOP_ab_Gen3,ZR_Standard
 SG_ ZV_gesafet_extern_ist : 20|1@1+ (1.0,0.0) [0.0|1] ""  ZR_High
 SG_ ZV_gesafet_extern_soll : 21|1@1+ (1.0,0.0) [0.0|1] ""  ZR_High,ZR_LIMU,ZR_MIB_TOP_ab_Gen3
 SG_ ZV_Einzeltuerentriegelung : 22|1@1+ (1.0,0.0) [0.0|1] ""  Vector__XXX
 SG_ ZV_Heckeinzelentriegelung : 23|1@1+ (1.0,0.0) [0.0|1] ""  Vector__XXX
 SG_ ZV_FT_offen : 24|1@1+ (1.0,0.0) [0.0|1] ""  DDA,OTA_FC,ZR_High,ZR_LIMU,ZR_MIB_TOP_ab_Gen3,ZR_Standard
 SG_ ZV_BT_offen : 25|1@1+ (1.0,0.0) [0.0|1] ""  DDA,OTA_FC,ZR_High,ZR_LIMU,ZR_MIB_TOP_ab_Gen3,ZR_Standard
 SG_ ZV_HFS_offen : 26|1@1+ (1.0,0.0) [0.0|1] ""  DDA,OTA_FC,ZR_High,ZR_LIMU,ZR_MIB_TOP_ab_Gen3,ZR_Standard
 SG_ ZV_HBFS_offen : 27|1@1+ (1.0,0.0) [0.0|1] ""  DDA,OTA_FC,ZR_High,ZR_LIMU,ZR_MIB_TOP_ab_Gen3,ZR_Standard
 SG_ ZV_HD_offen : 28|1@1+ (1.0,0.0) [0.0|1] ""  DDA,OTA_FC,ZR_High,ZR_LIMU,ZR_MIB_TOP_ab_Gen3,ZR_Standard
 SG_ ZV_HS_offen : 29|1@1+ (1.0,0.0) [0.0|1] ""  OTA_FC,ZR_High
 SG_ IRUE_aktiv : 30|1@1+ (1.0,0.0) [0.0|1] ""  ZR_High
 SG_ DWA_aktiv : 31|1@1+ (1.0,0.0) [0.0|1] ""  ZR_High
 SG_ HD_Hauptraste : 32|1@1+ (1.0,0.0) [0.0|1] ""  OTA_FC,ZR_High
 SG_ HD_Vorraste : 33|1@1+ (1.0,0.0) [0.0|1] ""  OTA_FC,ZR_High
 SG_ FFB_CarFinder : 38|1@1+ (1.0,0.0) [0.0|1] ""  Vector__XXX
 SG_ FFB_Komfortoeffnen : 39|1@1+ (1.0,0.0) [0.0|1] ""  Vector__XXX
 SG_ FFB_Komfortschliessen : 40|1@1+ (1.0,0.0) [0.0|1] ""  Vector__XXX
 SG_ ZV_Schluessel_Zugang : 42|4@1+ (1.0,0.0) [0.0|15] ""  ZR_High
 SG_ ZV_SafeFunktion_aktiv : 46|1@1+ (1.0,0.0) [0.0|1] ""  ZR_High
 SG_ FBS_Warn_Schluessel_Batt : 47|1@1+ (1.0,0.0) [0.0|1] ""  ZR_High
 SG_ ZV_Oeffnungsmodus : 48|2@1+ (1.0,0.0) [0.0|3] ""  Vector__XXX
 SG_ HFS_verriegelt : 50|1@1+ (1.0,0.0) [0.0|1] ""  OTA_FC
 SG_ HFS_gesafet : 51|1@1+ (1.0,0.0) [0.0|1] ""  Vector__XXX
 SG_ HBFS_verriegelt : 52|1@1+ (1.0,0.0) [0.0|1] ""  OTA_FC
 SG_ HBFS_gesafet : 53|1@1+ (1.0,0.0) [0.0|1] ""  Vector__XXX
 SG_ ZV_ist_Zustand_verfuegbar : 54|1@1+ (1.0,0.0) [0.0|1] ""  OTA_FC,ZR_High
 SG_ IRUE_Taster_Fkts_LED : 55|1@1+ (1.0,0.0) [0.0|1] ""  ZR_High
 SG_ ZV_Tankklappe_offen : 56|1@1+ (1.0,0.0) [0.0|1] ""  ZR_High
 SG_ ZV_Rollo_auf : 57|1@1+ (1.0,0.0) [0.0|1] ""  ZR_High
 SG_ ZV_Rollo_zu : 58|1@1+ (1.0,0.0) [0.0|1] ""  ZR_High
 SG_ ZV_SAD_auf : 59|1@1+ (1.0,0.0) [0.0|1] ""  ZR_High
 SG_ ZV_SAD_zu : 60|1@1+ (1.0,0.0) [0.0|1] ""  ZR_High
 SG_ BCM_Tankklappensteller_Fehler : 61|1@1+ (1.0,0.0) [0.0|1] ""  ZR_High
 SG_ ZV_verriegelt_soll : 62|2@1+ (1.0,0.0) [0.0|3] ""  Vector__XXX

BO_ 711 ZV_03: 8 Gateway
 SG_ ZV_TAG_verfahren : 12|2@1+ (1.0,0.0) [0.0|3] ""  Vector__XXX
 SG_ BCM_Spg_Heizen_Trigger : 14|1@1+ (1.0,0.0) [0.0|1] ""  Vector__XXX
 SG_ BCM2_ZV_Tasten_HMI_Anf : 15|1@1+ (1.0,0.0) [0.0|1] ""  BedienSG_hi,ZR_LIMU,ZR_MIB_TOP_ab_Gen3
 SG_ ZV_HD_Taste_zu : 16|1@1+ (1.0,0.0) [0.0|1] ""  Vector__XXX
 SG_ ZV_HD_Taste_auf : 17|1@1+ (1.0,0.0) [0.0|1] ""  Vector__XXX
 SG_ ZV_FD_Taste_auf : 18|1@1+ (1.0,0.0) [0.0|1] ""  Vector__XXX

BO_TX_BU_ 2589283609 :Gateway,Gateway_PAG;
BO_TX_BU_ 1718 :Gateway,Gateway_PAG;
BO_TX_BU_ 995 :Gateway,Gateway_PAG;
BO_TX_BU_ 1716 :Gateway,Gateway_PAG;
BO_TX_BU_ 385 :Gateway,Gateway_PAG;
BO_TX_BU_ 668 :Gateway,Gateway_PAG;
BO_TX_BU_ 1120 :Gateway,Gateway_PAG;
BO_TX_BU_ 916 :Gateway,Gateway_PAG;
BO_TX_BU_ 1361 :Gateway,Gateway_PAG;
BO_TX_BU_ 1702 :Gateway,Gateway_PAG;
BO_TX_BU_ 2527679496 :Gateway,Gateway_PAG;
BO_TX_BU_ 2589283611 :ZR_High,ZR_MIB_TOP_ab_Gen3;
BO_TX_BU_ 2617220609 :ZR_High,ZR_MIB_TOP_ab_Gen3,ZR_Standard;
BO_TX_BU_ 1140 :ZR_High,ZR_LIMU,ZR_MIB_TOP_ab_Gen3,ZR_Standard;
BO_TX_BU_ 2589283477 :ZR_High,ZR_LIMU,ZR_MIB_TOP_ab_Gen3,ZR_Standard;
BO_TX_BU_ 2527679655 :ZR_High,ZR_LIMU,ZR_MIB_TOP_ab_Gen3;
BO_TX_BU_ 389 :Gateway,Gateway_PAG;
BO_TX_BU_ 392 :Gateway,Gateway_PAG;
BO_TX_BU_ 388 :Gateway,Gateway_PAG;
BO_TX_BU_ 1411 :Gateway,Gateway_PAG;
BO_TX_BU_ 711 :Gateway,Gateway_PAG;
CM_ BO_ 995 "ab MQB IS5";
CM_ BO_ 1716 "200ms bei D4 und folgende";
CM_ BO_ 916 "ersetzt WBA_02";
CM_ BO_ 1702 "MLBevo";
CM_ BO_ 389 "Zentraler Fensterhebertaster

ab MQB gueltig";
CM_ BO_ 392 "Zentraler Fensterhebertaster

ab MQB gueltig";

CM_ SG_ 2589283609 UGDO_Channel_1 "Anlernstatus Kanal X für pilotiertes Parken.";
CM_ SG_ 2589283609 UGDO_Channel_10 "Anlernstatus Kanal X für pilotiertes Parken.";
CM_ SG_ 2589283609 UGDO_Channel_11 "Anlernstatus Kanal X für pilotiertes Parken.";
CM_ SG_ 2589283609 UGDO_Channel_12 "Anlernstatus Kanal X für pilotiertes Parken.";
CM_ SG_ 2589283609 UGDO_Channel_13 "Anlernstatus Kanal X für pilotiertes Parken.";
CM_ SG_ 2589283609 UGDO_Channel_14 "Anlernstatus Kanal X für pilotiertes Parken.";
CM_ SG_ 2589283609 UGDO_Channel_15 "Anlernstatus Kanal X für pilotiertes Parken.";
CM_ SG_ 2589283609 UGDO_Channel_2 "Anlernstatus Kanal X für pilotiertes Parken.";
CM_ SG_ 2589283609 UGDO_Channel_3 "Anlernstatus Kanal X für pilotiertes Parken.";
CM_ SG_ 2589283609 UGDO_Channel_4 "Anlernstatus Kanal X für pilotiertes Parken.";
CM_ SG_ 2589283609 UGDO_Channel_5 "Anlernstatus Kanal X für pilotiertes Parken.";
CM_ SG_ 2589283609 UGDO_Channel_6 "Anlernstatus Kanal X für pilotiertes Parken.";
CM_ SG_ 2589283609 UGDO_Channel_7 "Anlernstatus Kanal X für pilotiertes Parken.";
CM_ SG_ 2589283609 UGDO_Channel_8 "Anlernstatus Kanal X für pilotiertes Parken.";
CM_ SG_ 2589283609 UGDO_Channel_9 "Anlernstatus Kanal X für pilotiertes Parken.";
CM_ SG_ 2589283609 UGDO_DoorState "Ausgabe des Garagentorstatus für pilotiertes Parken.";
CM_ SG_ 2589283609 UGDO_Failure_Antenne "UGDO = LIN-Slave am BCM1.
UGDO-Sender meldet Fehlerstatus ans BCM1.";
CM_ SG_ 2589283609 UGDO_Failure_Codierung "UGDO = LIN-Slave am BCM1.
UGDO-Sender meldet Fehlerstatus ans BCM1.";
CM_ SG_ 2589283609 UGDO_Failure_Hardware "UGDO = LIN-Slave am BCM1.
UGDO-Sender meldet Fehlerstatus ans BCM1.";
CM_ SG_ 2589283609 UGDO_Function_01 "UGDO_Sender = LIN-Slave BCM1
bei Kl.15 AUS wird für 4s noch der letzte Wert gesendet, danach wird der Wert 7 (= Fehler gesendet)";
CM_ SG_ 2589283609 UGDO_LED_Code_01 "UGDO_Sender = LIN-Slave BCM1
Signal wird bei Kl.15 AUS mit dem letzten empfangenen Wert gesendet";
CM_ SG_ 2589283609 UGDO_ResponseError "siehe LIN2.0-Specification
(Darf nicht über ein Fehlergueltigkeitsbit abgesichtert werden!)";

CM_ SG_ 1718 UH_Minute "0x3C- 0x3f = Werte ungültig";
CM_ SG_ 1718 UH_Monat "0x0D, 0xF =  Werte ungültig
0x0E = Relatives Datum (nur VW)";
CM_ SG_ 1718 UH_Sekunde "0x3C- 0x3f = Werte ungültig";
CM_ SG_ 1718 UH_Stunde "0x18 - 0x1F = Werte ungültig";
CM_ SG_ 1718 UH_Tag "0x0: reserviert bei VW";
CM_ SG_ 1718 UH_Typ "0x4 - 0x7 = tbd. ";

CM_ SG_ 995 VD_SpannungsAnf "Anforderung Forderung des Verdecks zur Spannungsanhebung des Bordnetzes.";
CM_ SG_ 995 Verdeck_01_BZ "4bit Botschaftszähler, wird mit jeder Sendebotschaft inkrementiert";
CM_ SG_ 995 Verdeck_01_CRC "Für MLB:
Berechnung siehe Lastenheft 'Kommunikationsabsicherung für FlexRay und CAN'
Ab MQB und MLBevo:
Berechnung siehe Lastenheft 'End-to-End Kommunikationsabsicherung'

Endwerte siehe Begleitdokument 'S-PDU Kennungsfolgen'";
CM_ SG_ 995 VS_BFS_AutoHoch "automatischer Hochlauf des BFS Fenster ausgelöst durch die Verdecksteuerung";
CM_ SG_ 995 VS_BFS_AutoTief "automatischer Tieflauf des BFS Fenster ausgelöst durch die Verdecksteuerung";
CM_ SG_ 995 VS_BFS_ManHoch "manueller Hochlauf des BFS Fenster ausgelöst durch die Verdecksteuerung";
CM_ SG_ 995 VS_BFS_ManTief "manueller Tieflauf des BFS Fenster ausgelöst durch die Verdecksteuerung";
CM_ SG_ 995 VS_Buzzer "Buzzeransteuerung: 'Buzzeransteuerung' für Gong 200ms (Kombi)";
CM_ SG_ 995 VS_FH_BT_Langhub "Ansteuerung Fensterheber vom Verdecksteuergeraet";
CM_ SG_ 995 VS_FH_FT_Langhub "Ansteuerung Fensterheber vom Verdecksteuergeraet";
CM_ SG_ 995 VS_FH_HBFS_Langhub "Ansteuerung Fensterheber vom Verdecksteuergeraet";
CM_ SG_ 995 VS_FH_HFS_Langhub "Ansteuerung Fensterheber vom Verdecksteuergeraet";
CM_ SG_ 995 VS_FS_AutoHoch "automatischer Hochlauf des FS Fenster ausgelöst durch die Verdecksteuerung";
CM_ SG_ 995 VS_FS_AutoTief "automatischer Tieflauf des FS Fenster ausgelöst durch die Verdecksteuerung";
CM_ SG_ 995 VS_FS_ManHoch "manueller Hochlauf des FS Fenster ausgelöst durch die Verdecksteuerung";
CM_ SG_ 995 VS_FS_ManTief "manueller Tieflauf des FS Fenster ausgelöst durch die Verdecksteuerung";
CM_ SG_ 995 VS_Hardtop "



";
CM_ SG_ 995 VS_HBFS_AutoHoch "automatischer Hochlauf des HBFS Fenster ausgelöst durch die Verdecksteuerung";
CM_ SG_ 995 VS_HBFS_AutoTief "automatischer Tieflauf des HBFS Fenster ausgelöst durch die Verdecksteuerung";
CM_ SG_ 995 VS_HBFS_ManHoch "manueller Hochlauf des HBFS Fenster ausgelöst durch die Verdecksteuerung";
CM_ SG_ 995 VS_HBFS_ManTief "manueller Tieflauf des HBFS Fenster ausgelöst durch die Verdecksteuerung";
CM_ SG_ 995 VS_HD_sperren "Bei gesetztem Signal wird der Kofferraum/Heckdeckel durch den BCM2 nicht entriegelt werden.";
CM_ SG_ 995 VS_Heckschloss_auf "Signal wird gesetzt, wenn fuer einen Verdeckbetrieb das Öffnen des Heckschlosses erforderlich ist.";
CM_ SG_ 995 VS_HFS_AutoHoch "automatischer Hochlauf des HFS Fenster ausgelöst durch die Verdecksteuerung";
CM_ SG_ 995 VS_HFS_AutoTief "automatischer Tieflauf des HFS Fenster ausgelöst durch die Verdecksteuerung";
CM_ SG_ 995 VS_HFS_ManHoch "manueller Hochlauf des HFS Fenster ausgelöst durch die Verdecksteuerung";
CM_ SG_ 995 VS_HFS_ManTief "manueller Tieflauf des HFS Fenster ausgelöst durch die Verdecksteuerung";
CM_ SG_ 995 VS_HHS_enable "Fehlende Beschreibung (Import)";
CM_ SG_ 995 VS_Lampe_Blk "Ansteuerung Lampe im Kombi

Wird aktiviert bei Aufprüfen, Verdecklauf und Fehlerfall (blinkend).


";
CM_ SG_ 995 VS_StartStopp_Info "Stopp-Freigabe und Start-Anforderung an den Start-Stopp-Koordinator";
CM_ SG_ 995 VS_VD_Bew_auf "



";
CM_ SG_ 995 VS_VD_Bew_zu "


";
CM_ SG_ 995 VS_VD_entriegelt "

";
CM_ SG_ 995 VS_VD_Fehler "

";
CM_ SG_ 995 VS_VD_offen_ver "Zustand des Verdecks verriegelt und offen";
CM_ SG_ 995 VS_VD_zu_ver "
";
CM_ SG_ 995 VS_VD_Zwischenposition "

";
CM_ SG_ 995 VS_VDKD_auf "Signal wird gesetzt, wenn der Verdeckkastendeckel vollstaendig geoeffnet ist



";
CM_ SG_ 995 VS_Verdeck_Anf "



";
CM_ SG_ 995 VS_Windschott_nicht_abgelegt "Windschott ist aufgestellt, in Zwischenposition oder die Position ist unbekannt";
CM_ SG_ 995 VSG_Meldungen "Meldungen fuers Kombi lt. konzernübergreifender Abstimmung

0 -> keine Meldung
1 -> 'Verdeckbetrieb RDW aktiv'
2 -> 'Verdeckbetrieb NAR aktiv'
3 -> 'stehendes Verdeck in Zwischenposition (ZP)'
4 -> 'autom. Verdeck in ZP und KL15 aus'
5 -> 'manuelle";

CM_ SG_ 1716 VIN_01_MUX "Achtung:
Die Botschaft ist nicht linear gemultiplext!!!
Sondern 0,1,0,2,0, usw.";
CM_ SG_ 1716 VIN_1 "Initwert:
0x2D bei Fahrzeugen mit Wegfahrsperrengeneration >= 5 
0x58 bei Fahrzeugen mit Wegfahrsperrengeneration < 5 (z.B. WFS-4)";
CM_ SG_ 1716 VIN_10 "Initwert:
0x2D bei Fahrzeugen mit Wegfahrsperrengeneration >= 5 
0x58 bei Fahrzeugen mit Wegfahrsperrengeneration < 5 (z.B. WFS-4)";
CM_ SG_ 1716 VIN_11 "Initwert:
0x2D bei Fahrzeugen mit Wegfahrsperrengeneration >= 5 
0x58 bei Fahrzeugen mit Wegfahrsperrengeneration < 5 (z.B. WFS-4)";
CM_ SG_ 1716 VIN_12 "Initwert:
0x2D bei Fahrzeugen mit Wegfahrsperrengeneration >= 5 
0x58 bei Fahrzeugen mit Wegfahrsperrengeneration < 5 (z.B. WFS-4)";
CM_ SG_ 1716 VIN_13 "Initwert:
0x2D bei Fahrzeugen mit Wegfahrsperrengeneration >= 5 
0x58 bei Fahrzeugen mit Wegfahrsperrengeneration < 5 (z.B. WFS-4)";
CM_ SG_ 1716 VIN_14 "Initwert:
0x2D bei Fahrzeugen mit Wegfahrsperrengeneration >= 5 
0x58 bei Fahrzeugen mit Wegfahrsperrengeneration < 5 (z.B. WFS-4)";
CM_ SG_ 1716 VIN_15 "Initwert:
0x2D bei Fahrzeugen mit Wegfahrsperrengeneration >= 5 
0x58 bei Fahrzeugen mit Wegfahrsperrengeneration < 5 (z.B. WFS-4)";
CM_ SG_ 1716 VIN_16 "Initwert:
0x2D bei Fahrzeugen mit Wegfahrsperrengeneration >= 5 
0x58 bei Fahrzeugen mit Wegfahrsperrengeneration < 5 (z.B. WFS-4)";
CM_ SG_ 1716 VIN_17 "Initwert:
0x2D bei Fahrzeugen mit Wegfahrsperrengeneration >= 5 
0x58 bei Fahrzeugen mit Wegfahrsperrengeneration < 5 (z.B. WFS-4)";
CM_ SG_ 1716 VIN_2 "Initwert:
0x2D bei Fahrzeugen mit Wegfahrsperrengeneration >= 5 
0x58 bei Fahrzeugen mit Wegfahrsperrengeneration < 5 (z.B. WFS-4)";
CM_ SG_ 1716 VIN_3 "Initwert:
0x2D bei Fahrzeugen mit Wegfahrsperrengeneration >= 5 
0x58 bei Fahrzeugen mit Wegfahrsperrengeneration < 5 (z.B. WFS-4)";
CM_ SG_ 1716 VIN_4 "Initwert:
0x2D bei Fahrzeugen mit Wegfahrsperrengeneration >= 5 
0x58 bei Fahrzeugen mit Wegfahrsperrengeneration < 5 (z.B. WFS-4)";
CM_ SG_ 1716 VIN_5 "Initwert:
0x2D bei Fahrzeugen mit Wegfahrsperrengeneration >= 5 
0x58 bei Fahrzeugen mit Wegfahrsperrengeneration < 5 (z.B. WFS-4)";
CM_ SG_ 1716 VIN_6 "Initwert:
0x2D bei Fahrzeugen mit Wegfahrsperrengeneration >= 5 
0x58 bei Fahrzeugen mit Wegfahrsperrengeneration < 5 (z.B. WFS-4)";
CM_ SG_ 1716 VIN_7 "Initwert:
0x2D bei Fahrzeugen mit Wegfahrsperrengeneration >= 5 
0x58 bei Fahrzeugen mit Wegfahrsperrengeneration < 5 (z.B. WFS-4)";
CM_ SG_ 1716 VIN_8 "Initwert:
0x2D bei Fahrzeugen mit Wegfahrsperrengeneration >= 5 
0x58 bei Fahrzeugen mit Wegfahrsperrengeneration < 5 (z.B. WFS-4)";
CM_ SG_ 1716 VIN_9 "Initwert:
0x2D bei Fahrzeugen mit Wegfahrsperrengeneration >= 5 
0x58 bei Fahrzeugen mit Wegfahrsperrengeneration < 5 (z.B. WFS-4)";

CM_ SG_ 385 VZE_Anzeigemodus "Steuert die verschiedenen Möglichkeiten der Anzeige.";
CM_ SG_ 385 VZE_Anzeigeunterdrueck_Zeichen_1 "Steuerungssignal zur Steuerung der Sichtbarkeit von Verkehrszeichen ";
CM_ SG_ 385 VZE_Anzeigeunterdrueck_Zeichen_2 "Anzeigerelevanz des Zeichens in VZE_Verkehrszeichen_2";
CM_ SG_ 385 VZE_Anzeigeunterdrueck_Zeichen_3 "Anzeigerelevanz des Zeichens in VZE_Verkehrszeichen_3";
CM_ SG_ 385 VZE_Gong "Das Signal signalisiert dem Kombiinstrument ob bei der VZE-Tempowarnung ein Gong getriggert werden soll.";
CM_ SG_ 385 VZE_Hinweistext "Über Index wird ein Hinweistext beschrieben, der durch das Kombi dargestellte werden soll.

Wertebereich lt. Hashtabelle";
CM_ SG_ 385 VZE_Verkehrszeichen_1 "Das Signal spiegelt eines der Verkehrszeichen: Geschwindigkeitsgebot, Überholverbot, Aufhebungszeichen wider.

Wertebereich lt. Hashtabelle";
CM_ SG_ 385 VZE_Verkehrszeichen_2 "Das Signal spiegelt eines der Verkehrszeichen: Geschwindigkeitsgebot, Überholverbot, Aufhebungszeichen wider.

Wertebereich lt. Hashtabelle";
CM_ SG_ 385 VZE_Verkehrszeichen_3 "Das Signal spiegelt eines der Verkehrszeichen: Geschwindigkeitsgebot, Überholverbot, Aufhebungszeichen wider.

Wertebereich lt. Hashtabelle";
CM_ SG_ 385 VZE_Verkehrszeichen_Einheit "Signal gibt an ob das übertragene Verkehrszeichen in mph oder km/h übermittelt wird";
CM_ SG_ 385 VZE_Warnung_Verkehrszeichen_1 "Ist das Signal gesetzt, so ist für das Verkehrszeichen 1 eine Warnung auszugeben.";
CM_ SG_ 385 VZE_Warnung_Verkehrszeichen_2 "Ist das Signal gesetzt, so ist für das Verkehrszeichen 2 eine Warnung auszugeben.";
CM_ SG_ 385 VZE_Warnung_Verkehrszeichen_3 "Ist das Signal gesetzt, so ist für das Verkehrszeichen 3 eine Warnung auszugeben.";
CM_ SG_ 385 VZE_Zeichen_01_Gesetz "Das VZE-Tempolimit in Verkehrszeichen1  ist das gesetzlich geltende Tempolimit (je Land/Straßenklasse).";
CM_ SG_ 385 VZE_Zeichen_01_Kamera "Das VZE-Tempolimit in Verkehrszeichen1 wurde von der Kamera erkannt.";
CM_ SG_ 385 VZE_Zeichen_01_KameraWied "Das VZE-Tempolimit  in Verkehrszeichen1 wurde als Wiederholungsschild von der Kamera erkannt.";
CM_ SG_ 385 VZE_Zeichen_01_Karte "Das VZE-Tempolimit in Verkehrszeichen1 stammt aus den Navigationskartendaten.";
CM_ SG_ 385 VZE_Zeichen_02_Gesetz "Das VZE-Tempolimit in Verkehrszeichen2  ist das gesetzlich geltende Tempolimit (je Land/Straßenklasse).";
CM_ SG_ 385 VZE_Zeichen_02_Kamera "Das VZE-Tempolimit in Verkehrszeichen2 wurde von der Kamera erkannt.";
CM_ SG_ 385 VZE_Zeichen_02_KameraWied "Das VZE-Tempolimit  in Verkehrszeichen2 wurde als Wiederholungsschild von der Kamera erkannt.";
CM_ SG_ 385 VZE_Zeichen_02_Karte "Das VZE-Tempolimit in Verkehrszeichen2 stammt aus den Navigationskartendaten.";
CM_ SG_ 385 VZE_Zeichen_03_Gesetz "Das VZE-Tempolimit in Verkehrszeichen3  ist das gesetzlich geltende Tempolimit (je Land/Straßenklasse).";
CM_ SG_ 385 VZE_Zeichen_03_Kamera "Das VZE-Tempolimit in Verkehrszeichen3 wurde von der Kamera erkannt.";
CM_ SG_ 385 VZE_Zeichen_03_KameraWied "Das VZE-Tempolimit  in Verkehrszeichen3 wurde als Wiederholungsschild von der Kamera erkannt.";
CM_ SG_ 385 VZE_Zeichen_03_Karte "Das VZE-Tempolimit in Verkehrszeichen3 stammt aus den Navigationskartendaten.";
CM_ SG_ 385 VZE_Zusatzschild_1 "Zusatzsschild, das zu Verkehrszeichen 1 angezeigt werden soll.

Wertebereich lt. Hashtabelle";
CM_ SG_ 385 VZE_Zusatzschild_2 "Zusatzsschild, das zu Verkehrszeichen 2 angezeigt werden soll.

Wertebereich lt. Hashtabelle";
CM_ SG_ 385 VZE_Zusatzschild_3 "Zusatzsschild, das zu Verkehrszeichen 3 angezeigt werden soll.

Wertebereich lt. Hashtabelle";

CM_ SG_ 668 VZE_Anhaenger_Vmax "Übertragung der aus Kundeneinstellung und länderspezifischen Regelungen (StVO, Rechtsprechung...) berechneten legalen Höchstgeschwindigkeit für das Gespann.

10+ 0*10 = 10 km/h
10+ 1*10 = 20 km/h
...
10+ 5*10 = 60 km/h
10+ 6*10 = 70 km/h
...
10+ 1";
CM_ SG_ 668 VZE_Anzeigeunterdrueck_Zeichen_4 "Anzeigerelevanz des Zeichens in VZE_Anzeigerelevanz_Zeichen_4";
CM_ SG_ 668 VZE_Anzeigeunterdrueck_Zeichen_5 "Anzeigerelevanz des Zeichens in VZE_Anzeigerelevanz_Zeichen_5";
CM_ SG_ 668 VZE_Baustelle "Das Signal gibt an, ob aktuell ein Baustellenschild von der VZE erkannt wurde.";
CM_ SG_ 668 VZE_Verkehrszeichen_4 "Das Signal spiegelt eines der Verkehrszeichen: Geschwindigkeitsgebot, Überholverbot, Aufhebungszeichen wider.

Wertebereich lt. Hashtabelle";
CM_ SG_ 668 VZE_Verkehrszeichen_5 "Das Signal spiegelt eines der Verkehrszeichen: Geschwindigkeitsgebot, Überholverbot, Aufhebungszeichen wider.

Wertebereich lt. Hashtabelle";
CM_ SG_ 668 VZE_Warnung_Verkehrszeichen_4 "Ist das Signal gesetzt, so ist für das Verkehrszeichen 4 eine Warnung auszugeben.";
CM_ SG_ 668 VZE_Warnung_Verkehrszeichen_5 "Ist das Signal gesetzt, so ist für das Verkehrszeichen 5 eine Warnung auszugeben.";
CM_ SG_ 668 VZE_Zeichen_04_Gesetz "Das VZE-Tempolimit ist das gesetzlich geltende Tempolimit (je Land/Straßenklasse).";
CM_ SG_ 668 VZE_Zeichen_04_Kamera "Das VZE-Tempolimit wurde von der Kamera erkannt.";
CM_ SG_ 668 VZE_Zeichen_04_KameraWied "Das VZE-Tempolimit wurde als Wiederholungsschild von der Kamera erkannt.";
CM_ SG_ 668 VZE_Zeichen_04_Karte "Das VZE-Tempolimit stammt aus den Navigationskartendaten.";
CM_ SG_ 668 VZE_Zeichen_05_Entfernung "In dem Signal wird die Entfernung zum Verkehrszeichen5 übertragen";
CM_ SG_ 668 VZE_Zeichen_05_Entfernung_StdA "In dem Signal wird die Standardabweichung bzgl. der Entfernung zum Verkehrszeichen5 übertragen ";
CM_ SG_ 668 VZE_Zeichen_05_Gesetz "Das VZE-Tempolimit ist das gesetzlich geltende Tempolimit (je Land/Straßenklasse).";
CM_ SG_ 668 VZE_Zeichen_05_Kamera "Das VZE-Tempolimit wurde von der Kamera erkannt.";
CM_ SG_ 668 VZE_Zeichen_05_KameraWied "Das VZE-Tempolimit wurde als Wiederholungsschild von der Kamera erkannt.";
CM_ SG_ 668 VZE_Zeichen_05_Karte "Das VZE-Tempolimit stammt aus den Navigationskartendaten.";
CM_ SG_ 668 VZE_Zusatzschild_4 "Zusatzsschild, das zu Verkehrszeichen 4 angezeigt werden soll.

Wertebereich lt. Hashtabelle";
CM_ SG_ 668 VZE_Zusatzschild_5 "Zusatzsschild, das zu Verkehrszeichen 5 angezeigt werden soll.

Wertebereich lt. Hashtabelle";

CM_ SG_ 1120 VZE_Erweiterte_Information "In dem Signal spiegelt erweiterte Verkehrszeicheninformationen wieder (Ortsschild, Autobahnbeginn, Autobahnende)

Wertebereich lt. Hashtabelle";
CM_ SG_ 1120 VZE_Tempowarnung_Einheit "0 - Einheit Warnoffset km/h
1 -  Einheit Warnoffset mph";
CM_ SG_ 1120 VZE_Tempowarnung_Offset "das Signal überträgt den im CAR:Menü gewählten Offset für die VZE-Tempowarnung an das pACC Steuergerät. Die zugrhörige Einheit wird im Signal VZE_Tempowarnung_Einheit übertragen";
CM_ SG_ 1120 VZE_Tempowarnung_Status "0 - Tempowarnung aktiv
1 -  Tempowarnung desktiv";
CM_ SG_ 1120 VZE_Umweltinfo_Anhaengerbetrieb "In dem Signal werden für die Verkehrszeichenerkennung relevante Umweltinformationen übertragen.

Info: Anhängerbetrieb";
CM_ SG_ 1120 VZE_Umweltinfo_Naesse "In dem Signal werden für die Verkehrszeichenerkennung relevante Umweltinformationen übertragen.

Info: Nässe";
CM_ SG_ 1120 VZE_Umweltinfo_Nebel "In dem Signal werden für die Verkehrszeichenerkennung relevante Umweltinformationen übertragen.

Info: Nebel";
CM_ SG_ 1120 VZE_Verkehrszeichen_6 "Das Signal spiegelt eines der Verkehrszeichen: Geschwindigkeitsgebot, Überholverbot, Aufhebungszeichen wider.

Wertebereich lt. Hashtabelle";
CM_ SG_ 1120 VZE_Zeichen_06_Entfernung "In dem Signal wird die Entfernung zum Verkehrszeichen6 übertragen";
CM_ SG_ 1120 VZE_Zeichen_06_Entfernung_StdA "In dem Signal wird die Standardabweichung bzgl. der Entfernung zum Verkehrszeichen6 übertragen ";
CM_ SG_ 1120 VZE_Zusatzschild_6 "Zusatzsschild, das zu Verkehrszeichen 6 angezeigt werden soll.

Wertebereich lt. Hashtabelle";

CM_ SG_ 916 GE_Sollgang "Signalisiert den Sollgang, in den getippt werden soll. Abhängig vom Signal 'WBA_eing_Gang_02' und dem Sollgang kann dann das Kombi die Hochschaltempfehlung in Tip darstellen.";
CM_ SG_ 916 GE_Stoppverbot_Anz_01 "Dieses Signal gibt die detaillierte Begründung für ein Stoppverbot vom Getriebesteuergerät an.";
CM_ SG_ 916 GE_Stoppverbot_Anz_02 "Dieses Signal gibt die detaillierte Begründung für ein Stoppverbot vom Getriebesteuergerät an.";
CM_ SG_ 916 GE_Stoppverbot_Anz_03 "Dieses Signal gibt die detaillierte Begründung für ein Stoppverbot vom Getriebesteuergerät an.";
CM_ SG_ 916 GE_Stoppverbot_Anz_04 "Dieses Signal gibt die detaillierte Begründung für ein Stoppverbot vom Getriebesteuergerät an.";
CM_ SG_ 916 GE_Stoppverbot_Anz_05 "Dieses Signal gibt die detaillierte Begründung für ein Stoppverbot vom Getriebesteuergerät an.";
CM_ SG_ 916 GE_Stoppverbot_Anz_06 "Dieses Signal gibt die detaillierte Begründung für ein Stoppverbot vom Getriebesteuergerät an.";
CM_ SG_ 916 GE_Stoppverbot_Anz_07 "Dieses Signal gibt die detaillierte Begründung für ein Stoppverbot vom Getriebesteuergerät an.";
CM_ SG_ 916 GE_Stoppverbot_Anz_Std "Dieses Signal gibt die detaillierte Begründung für ein Stoppverbot vom Getriebesteuergerät an.";
CM_ SG_ 916 GE_Tipschaltempf_verfuegbar "Signalisierung, ob eine Hochschaltempfehlung im Tipmodus verfügbar ist oder nicht.";
CM_ SG_ 916 GE_Wiederstart_Anz_Std "Dieses Signal gibt die detaillierte Begründung für einen Wiederstart vom Getriebesteuergerät an. ";
CM_ SG_ 916 WBA_03_CRC "Für MLB:
'Berechnung siehe Lastenheft 'Kommunikationsabsicherung für FlexRay und CAN''

Ab MQB und MLBevo:
'Berechnung siehe Lastenheft 'End-to-End Kommunikationsabsicherung''

Endwerte siehe Begleitdokument 'S-PDU Kennungsfolgen'";
CM_ SG_ 916 WBA_Blinken "Dieses Bit steuert die Fehlerlampe an oder wird zum Blinken der WBA-Anzeige genutzt - nur falls WBA_Senderkennung = 00 (GSG)
";
CM_ SG_ 916 WBA_eing_Gang_02 "Das Automatikgetriebe gibt den aktuell eingelegten Gang aus.
Besonderheiten:
0x0 = marktabhängig wird auf Ganganzeige zur Fahrstufe komplett verzichtet
0xA = kurzzeitige Unterdrückung der Ganganzeige (z. B. Segeln, Zwischenstellung, etc.)";
CM_ SG_ 916 WBA_Fahrstufe_02 "Bei Automatgetrieben wird in diesem Signal die aktuelle anzuzeigende Fahrstufe ausgegeben.

Die Signalkodierungen 0x9, 0xA und 0xB werden im MSS-R8NF und MQB-A1/B/A2 verwendet.

Die Signalkodierungen 0xC und 0xD werden nur im MQB-A1/B/A2 verwendet.
";
CM_ SG_ 916 WBA_GE_Texte "Fahrerhinweise für das Kombi";
CM_ SG_ 916 WBA_GE_Texte_02 "Fahrerhinweise für das Kombi";
CM_ SG_ 916 WBA_GE_Texte_03 "Launch control functionality stauts (performance strategy and smoke stratgey)";
CM_ SG_ 916 WBA_GE_Warnung_02 "Prioritätswarnungen Getriebe";
CM_ SG_ 916 WBA_GE_Zusatzwarnungen "Prioritaetswarnungen Getriebe an Kombi
Audi MLB Wertebereich 0 bis 3
VW MQB Projekte verwenden nur den Wertebereich 0 bis 2
VW MQB Getriebefehler werden über das Signal  GE_Warnungen_02 gesendet.";
CM_ SG_ 916 WBA_Schaltschema "Bei Automatikgetrieben wird in diesem Signal die aktuelle, eingelegte Fahrstufe (=Wählhebelposition) ausgegeben.";
CM_ SG_ 916 WBA_Segeln_aktiv "Getriebe geht in den Segelbetrieb";
CM_ SG_ 916 WBA_ZielFahrstufe "Zielfahrprogramm (Darstellung), für getipptes S/E/M mit neuem Wählhebel im MQB";

CM_ SG_ 1361 WFS_Betrieb_Lesespule "Schlüsselkommunikation über die Lesespule";
CM_ SG_ 1361 WFS_ELV_authorisiert "Authorisierung der elektrischen Lenkungsverriegelung an der WFS";
CM_ SG_ 1361 WFS_Fahrerhinweise "Meldungen, Fahrer- und Warnhinweise der Wegfahrsperre";
CM_ SG_ 1361 WFS_ID_Geb_autorisiert "Authorisierung Schluessel (ID-Geber)
";
CM_ SG_ 1361 WFS_ID_Geb_autorisiert_in_Kl15 "Authorisierung des Schlüssels im aktiven Klemme-15-Zyklus";
CM_ SG_ 1361 WFS_ID_Geb_steckt "Schluessel (ID-Geber) im Zuendschloss
";
CM_ SG_ 1361 WFS_Klemmenfreigabe "Freigabe von der WFS zum Einschalten der Klemme 15 und Klemme S";
CM_ SG_ 1361 WFS_LF_Aktiv "LF Schluesselkommunikation
";
CM_ SG_ 1361 WFS_LZ "Anforderung aus Lastenheft WFS V
";
CM_ SG_ 1361 WFS_Parken_Status "Schnittstelle zwischen WFS und ZFAS für das Pilotierte Parken um in Richtung ZFAS den Status der WFS im BCM2 zu kommunizieren";
CM_ SG_ 1361 WFS_Safe "Status WFS";
CM_ SG_ 1361 WFS_Schluessel_Fahrberecht "Schlüsselnummer Fahrberechtigung
0 = ungueltig, xxxx = Schluessel-Nr.";
CM_ SG_ 1361 WFS_Schluessel_Ist "Istwert der gelernten Schluessel";
CM_ SG_ 1361 WFS_Schluessel_Soll "Sollwert der zu lernenden Schluessel";

CM_ SG_ 1702 BCM1_SRA_aktiv "Status Scheinwerferreinigungsanlage";
CM_ SG_ 1702 Heckwischer_Anforderung "Das Signal beschreibt die Anforderung an den Signalausgang im BCM2 zur Ansteuerung des Heckwischers.";
CM_ SG_ 1702 Waschen_vorne_aktiv "Status: Waschen vorne aktiv 
";
CM_ SG_ 1702 Wischer1_Wischgeschwindigkeit "aktuelle, durch Sensorik gemessene Wischgeschwindigkeit";
CM_ SG_ 1702 Wischer_Anzeigetext "Das Signal fordert einen Kombi-Pop-Up mit entsprechenden Texten an";
CM_ SG_ 1702 Wischer_vorne_aktiv "Status: Wischer vorne";
CM_ SG_ 1702 Wischer_vorne_blockiert "Blockade Wischer vorne (z.B. durch Schnee)";
CM_ SG_ 1702 Wischer_vorne_defekt "Fehlerstatus Wischer vorne (Anzeige im Kombi)";
CM_ SG_ 1702 Wischer_vorne_Normal "Wischer Front normal aktiv";
CM_ SG_ 1702 Wischer_vorne_Parklage "Wischer Front in Parklage";
CM_ SG_ 1702 Wischer_vorne_Schnell "Wischer vorne schnell aktiv";
CM_ SG_ 1702 WWSs_01_upd "Update-Bit für die LIN-Botschaft WWSs_01.

Betroffene Signale:

Wischer_vorne_aktiv
Wischer1_Wischgeschwindigkeit";

CM_ SG_ 2527679496 WIV_Russindex_02 "Nur für Diesel, Rußwert, bei Otto Wert = 0";
CM_ SG_ 2527679496 WIV_Russindex_Ueberlauf "Der motorsteuergeräteinterne Zähler für den Russindex ist mindestens einmal übergelaufen. Dieses Bit wird genutzt, um erkennen zu können, daß das Motorsteuergerät aus dem Reset-Zustand hochläuft.";
CM_ SG_ 2527679496 WIV_t_max "Maximales Wartungsintervall für WIV in Monaten";
CM_ SG_ 2527679496 WIV_t_min "Minimales Wartungsintervall für WIV in Monaten";
CM_ SG_ 2527679496 WIV_Verschleissindex_02 "Bei Otto Verbrauch, bei Diesel Verschleiss";
CM_ SG_ 2527679496 WIV_Verschleissindex_Ueberlauf "Der motorsteuergeräteinterne Zähler für den Verschleissindex (Diesel) bzw. Verbrauchsindex (Otto) ist mindestens einmal übergelaufen. Dieses Bit wird genutzt, um erkennen zu können, daß das Motorsteuergerät aus dem Reset-Zustand hochläuft.";
CM_ SG_ 2527679496 WIV_W_max "Maximales Wartungsintervall für WIV in km";
CM_ SG_ 2527679496 WIV_W_min "Minimales Wartungsintervall für WIV in km";

CM_ SG_ 2589283611 WLC1_aktive_Spule "Active_Coil";
CM_ SG_ 2589283611 WLC1_Charger_Effizienz "Charger charging (Efficiency in % )
0 = no charging 
1 = charging with 1%
10 = charging with 10 %";
CM_ SG_ 2589283611 WLC1_Charger_laedt "Charger charging (übertragene Leistung) (0,1W)

0 = no charging 
1 = charging with 0,1 Watt
10 = charging with 1 Watt";
CM_ SG_ 2589283611 WLC1_Fremdobjekt_erkannt "Messwert/Anzeige Fremdobjekt erkannt";
CM_ SG_ 2589283611 WLC1_Leistungsklasse_Receiver "Performance_Class_Receiver
0 = no Device
1 = class with 0,1 Watt
10 = class with 1 Watt";
CM_ SG_ 2589283611 WLC1_Objekt_erkannt "non wireless Charging Device in the storage box ";
CM_ SG_ 2589283611 WLC1_Receiver_erkannt "wireless Charging Device (Phone) is in the storage box ";
CM_ SG_ 2589283611 WLC1_Receiver_voll_geladen "0 = WLC not fully charged or no Device available
1 = WLC Device fully charged ";
CM_ SG_ 2589283611 WLC1_Temp_Leistungsteil_Charger "Temperature_Power_Electronics
0 = -58 °C
1 = -57 °C
..";
CM_ SG_ 2589283611 WLC1_Temp_Oberfaeche_Charger "Surface_Temperature_WLC
0 = -58 °C
1 = -57 °C
..";
CM_ SG_ 2589283611 WLC1_Temp_Receiver "Temperature_Receiver
0 = -58 °C
1 = -57 °C
..";
CM_ SG_ 2589283611 WLC1_verwendeter_Ladestandard "WLC_technology";

CM_ SG_ 1140 MMI_State "Powerstate des Zentralrechners. MMI_Off wird im Zustand dead mode gesendet.";
CM_ SG_ 1140 SI_ICAN "MQB: Busruhe ICAN.
E3: Busruhe ABCAN.";
CM_ SG_ 1140 WLC1_Systemzustand "0 = Wireless Charger off
1 = Wireless Charger on";
CM_ SG_ 1140 WLC2_Systemzustand "0 = Wireless Charger off
1 = Wireless Charger on";
CM_ SG_ 1140 ZR_DimOffs_DU_1 "Dimmungs-Offset der Display Unit.";
CM_ SG_ 1140 ZR_DimOffs_DU_2 "Dimmungs-Offset der Display Unit.";
CM_ SG_ 1140 ZR_DimOffs_DU_3 "Dimmungs-Offset der Display Unit.";
CM_ SG_ 1140 ZR_DimOffs_DU_4 "Dimmungs-Offset der Display Unit.";
CM_ SG_ 1140 ZR_LeistungSaeule "Ladeleistung der geplanten Ladesäule";
CM_ SG_ 1140 ZR_Lenkerposition "Ueber Diagnose (Codierung) im Zentralrechner eingespeicherte Lenkerposition
  ";
CM_ SG_ 1140 ZR_SOCSaeule "SOC an der Ladesäule am nächsten geplanten Ladestopp";
CM_ SG_ 1140 ZR_SpannungSaeule "Ladespannung an der Ladesäule am nächsten geplanten Ladestopp";
CM_ SG_ 1140 ZR_State_DU_1 "Kontrollbit für Display, Hintergrundbeleuchtung aus, Hintergrundbeleuchtung an, Energiesparmodus.
";
CM_ SG_ 1140 ZR_State_DU_2 "Kontrollbit für Display, Hintergrundbeleuchtung aus, Hintergrundbeleuchtung an, Energiesparmodus.
";
CM_ SG_ 1140 ZR_State_DU_3 "Kontrollbit für Display, Hintergrundbeleuchtung aus, Hintergrundbeleuchtung an, Energiesparmodus.
";
CM_ SG_ 1140 ZR_State_DU_4 "Kontrollbit für Display, Hintergrundbeleuchtung aus, Hintergrundbeleuchtung an, Energiesparmodus.";
CM_ SG_ 1140 ZR_t_naechsteLadung "Dauer bis zur nächsten Schnellladung in Minuten";
CM_ SG_ 1140 ZR_WecktGesp "Befehl zum Sperren der Wecktasten am Bedienteil.";

CM_ SG_ 2589283477 MMI_State "Powerstate des Zentralrechners. MMI_Off wird im Zustand dead mode gesendet.";
CM_ SG_ 2589283477 MU_ActiveTime_MIBCAN "Busaktivität MIB-CAN
MIB-CAN aktiv";
CM_ SG_ 2589283477 MU_ActiveTime_MOST "Aktivzeit des MOST (Licht an)";
CM_ SG_ 2589283477 MU_CTR_MOST_OFF_ON "Anzahl MOST Übergänge OFF-> ON (MOST Licht aus => an zählen)";
CM_ SG_ 2589283477 MU_CTR_Startup_MainUnit "Anzahl der Aufstarts MainUnit aus MMI_OFF, MMI_ONLINE, MMI_PHONE, MMI_RTC";
CM_ SG_ 2589283477 MU_MOST_State "aktueller Zustand MOST";
CM_ SG_ 2589283477 MU_OnlineTime_MainUnit "Aktivzeit der MainUnit für online Funktionen
MMI-States: MMI_ONLINE, MMI_ONLINE_IOC";
CM_ SG_ 2589283477 MU_OnTime_MainUnit "Aktivzeit der MainUnit im ON-Zustand nach Kl. 15=OFF
MMI-States:
- MMI_ON
- MMI_ON_TEL";
CM_ SG_ 2589283477 MU_StandbyTime_MainUnit "Aktivzeit der MainUnit im Standby
MMI-States: MMI_STANDBY, MMI_STANDBY_PWR_SAVE1/2, MMI_STANDBY_CUSTOMER_SWDL";

CM_ SG_ 2527679655 MMI_StartupAnimation "Synchronisierung der Startupanimation zwischen MMI und Kombi";
CM_ SG_ 2527679655 ZR_SOC_Weiterfahrt "SOC auf den an der Ladesäule am nächsten geplanten Ladestopp geladen werden soll.";

CM_ SG_ 389 Krypt_Schluesselschalter_auf "Schluesselschalter 'Auf' betaetigt";
CM_ SG_ 389 Krypt_Schluesselschalter_zu "Schluesselschalter 'ZU' betaetigt";
CM_ SG_ 389 Krypt_Signatur "Kryptologiesignatur";
CM_ SG_ 389 ZFH_BFS_AutoHoch "automatischer Hochlauf des BFS Fenster ausgelöst durch zentralen Fensterhebertaster";
CM_ SG_ 389 ZFH_BFS_AutoTief "automatischer Tieflauf des BFS Fenster ausgelöst durch zentralen Fensterhebertaster";
CM_ SG_ 389 ZFH_BFS_ManHoch "manueller Hochlauf des BFS Fenster ausgelöst durch zentralen Fensterhebertaster";
CM_ SG_ 389 ZFH_BFS_ManTief "manueller Tieflauf des BFS Fenster ausgelöst durch zentralen Fensterhebertaster";
CM_ SG_ 389 ZFH_FS_AutoHoch "automatischer Hochlauf des FS Fenster ausgelöst durch zentralen Fensterhebertaster";
CM_ SG_ 389 ZFH_FS_AutoTief "automatischer Tieflauf des FS Fenster ausgelöst durch zentralen Fensterhebertaster";
CM_ SG_ 389 ZFH_FS_ManHoch "manueller Hochlauf des FS Fenster ausgelöst durch zentralen Fensterhebertaster";
CM_ SG_ 389 ZFH_FS_ManTief "manueller Tieflauf des FS Fenster ausgelöst durch zentralen Fensterhebertaster";
CM_ SG_ 389 ZFH_HBFS_AutoHoch "automatischer Hochlauf des HBFS Fenster ausgelöst durch zentralen Fensterhebertaster";
CM_ SG_ 389 ZFH_HBFS_AutoTief "automatischer Tieflauf des HBFS Fenster ausgelöst durch zentralen Fensterhebertaster";
CM_ SG_ 389 ZFH_HBFS_ManHoch "manueller Hochlauf des HBFS Fenster ausgelöst durch zentralen Fensterhebertaster";
CM_ SG_ 389 ZFH_HBFS_ManTief "manueller Tieflauf des HBFS Fenster ausgelöst durch zentralen Fensterhebertaster";
CM_ SG_ 389 ZFH_HFS_AutoHoch "automatischer Hochlauf des HFS Fenster ausgelöst durch zentralen Fensterhebertaster";
CM_ SG_ 389 ZFH_HFS_AutoTief "automatischer Tieflauf des HFS Fenster ausgelöst durch zentralen Fensterhebertaster";
CM_ SG_ 389 ZFH_HFS_ManHoch "manueller Hochlauf des HFS Fenster ausgelöst durch zentralen Fensterhebertaster";
CM_ SG_ 389 ZFH_HFS_ManTief "manueller Tieflauf des HFS Fenster ausgelöst durch zentralen Fensterhebertaster";
CM_ SG_ 389 ZFH_zentral_auf "Zentraler Tieflauf aller Seitenscheiben";
CM_ SG_ 389 ZFH_zentral_zu "Zentraler Hochlauf aller Seitenscheiben";

CM_ SG_ 392 BT_FH_BT_AutoHoch "automatischer Hochlauf der Beifahrertür Seitenscheiben ausgelöst durch zentralen Fensterhbertaster";
CM_ SG_ 392 BT_FH_BT_AutoTief "automatischer Tieflauf der Beifahrertür Seitenscheiben ausgelöst durch zentralen Fensterhbertasterv";
CM_ SG_ 392 BT_FH_BT_ManHoch "manueller Hochlauf der Beifahrertür Seitenscheiben ausgelöst durch zentralen Fensterhbertaster";
CM_ SG_ 392 BT_FH_BT_ManTief "manueller Tieflauf der Beifahrertür Seitenscheiben ausgelöst durch zentralen Fensterhbertaster";
CM_ SG_ 392 BT_FH_FT_AutoHoch "automatischer Hochlauf der Fahrertür Seitenscheiben ausgelöst durch zentralen Fensterhbertaster";
CM_ SG_ 392 BT_FH_FT_AutoTief "automatischer Tieflauf der Fahrertür Seitenscheiben ausgelöst durch zentralen Fensterhbertaster";
CM_ SG_ 392 BT_FH_FT_ManHoch "manueller Hochlauf der Fahrertür Seitenscheiben ausgelöst durch zentralen Fensterhbertaster";
CM_ SG_ 392 BT_FH_FT_ManTief "manueller Tieflauf der Fahrertür Seitenscheiben ausgelöst durch zentralen Fensterhbertaster";
CM_ SG_ 392 BT_FH_HBFS_AutoHoch "automatischer Hochlauf der hinteren Türseitenscheibe Beifahrerseite - ausgelöst durch zentralen Fensterhbertaster";
CM_ SG_ 392 BT_FH_HBFS_AutoTief "automatischer Tieflauf der hinteren Türseitenscheibe Beifahrerseite - ausgelöst durch zentralen Fensterhbertaster";
CM_ SG_ 392 BT_FH_HBFS_ManHoch "manueller Hochlauf der hinteren Türseitenscheibe Beifahrerseite - ausgelöst durch zentralen Fensterhbertaster";
CM_ SG_ 392 BT_FH_HBFS_ManTief "manueller Tieflauf der hinteren Türseitenscheibe Beifahrerseite - ausgelöst durch zentralen Fensterhbertaster";
CM_ SG_ 392 BT_FH_HFS_AutoHoch "automatischer Hochlauf der hinteren Türseitenscheiben Fahrerseite - ausgelöst durch zentralen Fensterhbertaster";
CM_ SG_ 392 BT_FH_HFS_AutoTief "automatischer Tieflauf der hinteren Türseitenscheiben Fahrerseite - ausgelöst durch zentralen Fensterhbertaster";
CM_ SG_ 392 BT_FH_HFS_ManHoch "manueller Hochlauf der hinteren Türseitenscheiben Fahrerseite - durch zentralen Fensterhbertaster";
CM_ SG_ 392 BT_FH_HFS_ManTief "manueller Tieflauf der hinteren Türseitenscheiben Fahrerseite - durch zentralen Fensterhbertaster";
CM_ SG_ 392 BT_FH_zentral_auf "Fehlende Beschreibung (Import)";
CM_ SG_ 392 BT_FH_zentral_zu "Fehlende Beschreibung (Import)";
CM_ SG_ 392 BT_SP_Fahrstellung "Spiegel ausgeklappt

nicht in B8 und C6";
CM_ SG_ 392 BT_SP_Garagenstellung "Spiegel wird angeklappt

nicht in B8 und C6";
CM_ SG_ 392 BT_SP_hoch "nicht in B8 und C6";
CM_ SG_ 392 BT_SP_links "nicht in B8 und C6";
CM_ SG_ 392 BT_SP_rechts "nicht in B8 und C6";
CM_ SG_ 392 BT_SP_tief "nicht in B8 und C6";

CM_ SG_ 388 BCM_BF_Spg_Absenkung "Spiegelabsenkung Beifahrerseite";
CM_ SG_ 388 BCM_Spg_Synchron "Anforderung zur Aktivierung der synchronen Spiegelverstellung";
CM_ SG_ 388 FH_BT_hoch "Freigabeinformation fuer die FH-Komfortfunktion";
CM_ SG_ 388 FH_BT_tief "Freigabeinformation fuer die FH-Komfortfunktion";
CM_ SG_ 388 FH_FT_hoch "Freigabeinformation fuer die FH-Komfortfunktion";
CM_ SG_ 388 FH_FT_tief "Freigabeinformation fuer die FH-Komfortfunktion";
CM_ SG_ 388 FH_HBFS_hoch "Freigabeinformation fuer die FH-Komfortfunktion";
CM_ SG_ 388 FH_HBFS_tief "Freigabeinformation fuer die FH-Komfortfunktion";
CM_ SG_ 388 FH_HFS_hoch "Freigabeinformation fuer die FH-Komfortfunktion";
CM_ SG_ 388 FH_HFS_tief "Freigabeinformation fuer die FH-Komfortfunktion";
CM_ SG_ 388 VIP_Freigabe "Vituelles Pedal ist über HMI freigeschaltet.";
CM_ SG_ 388 VIP_Sensor_betaetigt "Heckentriegelung durch die Bedienstelle Virtuelles Pedal(VIP) erkannt. Der VIP Sensor hat eine Fusskickbewegung erkannt und es wurde ein Kessy - Schlüssel im Heckaussenbereich erkannt.";
CM_ SG_ 388 ZV_01_CRC "Für MLB:
'Berechnung siehe Lastenheft 'Kommunikationsabsicherung für FlexRay und CAN''

Ab MQB und MLBevo:
'Berechnung siehe Lastenheft 'End-to-End Kommunikationsabsicherung''

Endwerte siehe Begleitdokument 'S-PDU Kennungsfolgen'";
CM_ SG_ 388 ZV_auf_BT "ZV Schliessstelle";
CM_ SG_ 388 ZV_auf_FT "ZV Schliessstelle";
CM_ SG_ 388 ZV_auf_Funk "ZV Schliessstelle";
CM_ SG_ 388 ZV_auf_Kessy "ZV Schliessstelle";
CM_ SG_ 388 ZV_auto_Ansteuerung "Kennung für die automatische Ansteuerung der Zentralverriegelung (Autolock/Autounlock)";
CM_ SG_ 388 ZV_BT_entriegeln "Beifahrertür entriegeln (Anforderung ZV)";
CM_ SG_ 388 ZV_BT_verriegeln "Verriegelungsanforderung ZV für BT";
CM_ SG_ 388 ZV_entriegeln_Anf "Bei ZV Anforderung erfolgt die Entriegelung des Ladesteckers";
CM_ SG_ 388 ZV_FT_entriegeln "Entriegelungsanforderung ZV für FT";
CM_ SG_ 388 ZV_FT_verriegeln "Verriegelungsanforderung ZV für FT";
CM_ SG_ 388 ZV_HBFS_entriegeln "Entriegelungsanforderung ZV für HBFS
";
CM_ SG_ 388 ZV_HBFS_verriegeln "Verriegelungsanforderung ZV für HBFS
";
CM_ SG_ 388 ZV_HFS_entriegeln "Entriegelungsanforderung ZV für HFS
";
CM_ SG_ 388 ZV_HFS_verriegeln "Verriegelungsanforderung ZV für HFS
";
CM_ SG_ 388 ZV_HSK_entriegeln "Anforderungssignal zur Ansteuerung des Handschuhkastenmotors in Richtung Entriegeln. ";
CM_ SG_ 388 ZV_HSK_verriegeln "Anforderungssignal zur Ansteuerung des Handschuhkastenmotors in Richtung Verriegeln. ";
CM_ SG_ 388 ZV_LED_Steuerung "Ansteuerung der LED's in den Tueren; BAF gilt nicht für dieses Bit";
CM_ SG_ 388 ZV_LED_Uebernahme "Uebernahme der LED Steuerung durch das TSG FT";
CM_ SG_ 388 ZV_Signatur "Signatur der ZV";
CM_ SG_ 388 ZV_Softtouch_betaetigt "Betätigung Softtouch";
CM_ SG_ 388 ZV_Spg_Anklappen "Anforderung über ZV: Spiegel sind anzuklappen";
CM_ SG_ 388 ZV_Verdeck_auf "Anforderungssignal für ein Komfortöffnen des Verdecks. 
Signal wird angefordert wenn  SKontakt = 0 und eine Doppelbetätigung Schließzylinder_auf oder Funkfernbedienung_Taste_auf  innerhalb zwei Sekunden empfangen wird. Signal wird auch angefordert wenn S";
CM_ SG_ 388 ZV_Verdeck_zu "Anforderungssignal für ein Komfortschließen des Verdecks. 
Signal wird angefordert wenn  SKontakt = 0 und eine Doppelbetätigung Schließzylinder_Zu oder Funkfernbedienung_Taste_zu  innerhalb zwei Sekunden empfangen wird. Signal wird auch angefordert wenn ";
CM_ SG_ 388 ZV_zentral_entsafen "Zentral entsafen";
CM_ SG_ 388 ZV_zentral_safen "Zentral safen";
CM_ SG_ 388 ZV_zu_BT "ZV Schliessstelle";
CM_ SG_ 388 ZV_zu_FT "ZV Schliessstelle";
CM_ SG_ 388 ZV_zu_Funk "ZV Schliessstelle";
CM_ SG_ 388 ZV_zu_Kessy "ZV Schliessstelle";
CM_ SG_ 388 ZV_zu_Zeitl_Nachverr "ZV Schliessstelle";

CM_ SG_ 1411 BCM_FH_Freigabe "Funktionsfreigabe Fensterheber";
CM_ SG_ 1411 BCM_HSK_Freigabe "Handschuhkastenfreigabe";
CM_ SG_ 1411 BCM_Komfortfkt_Freigabe "globale Freigabe der Komfortfunktion";
CM_ SG_ 1411 BCM_Tankklappensteller_Fehler "Fehler: nicht Funktionalität des Tankklappenstellers";
CM_ SG_ 1411 BCM_Verdeck_Freigabe "Freigabe Verdeckbetrieb
";
CM_ SG_ 1411 DWA_aktiv "Status DWA  aktiv";
CM_ SG_ 1411 FBS_Warn_Schluessel_Batt "Kombi Prio Warnung Schluessel Batterie
'Bitte Schlüsselbatterie wechseln!'";
CM_ SG_ 1411 FFB_CarFinder "Car Finder Funktion (Blinken ohne zu entriegeln)";
CM_ SG_ 1411 FFB_Komfortoeffnen "Komfortoeffnen Funk
";
CM_ SG_ 1411 FFB_Komfortschliessen "Komfortschliessen Funk
";
CM_ SG_ 1411 HBFS_gesafet "HBFS Tuer gesafet.
Im Zustand Safe wird auch das Signal HBFS_verriegelt = 1 gesendet.";
CM_ SG_ 1411 HBFS_verriegelt "Verriegelungsstatus Tür";
CM_ SG_ 1411 HD_Hauptraste "SBL-Schloss (MQB/MLBevo): Drehfalle Heckdeckel
sonst (MQB): Hauptraste Heckdeckel";
CM_ SG_ 1411 HD_Vorraste "SBL_Schloss (MQB/MLBevo): Sperrklinke Heckdeckel
sonst (MQB): Vorraste Heckdeckel";
CM_ SG_ 1411 HFS_gesafet "HFS Tuer gesafet.
Im Zustand Safe wird auch das Signal HFS_verriegelt = 1 gesendet.";
CM_ SG_ 1411 HFS_verriegelt "HFS Tuer verriegelt";
CM_ SG_ 1411 IRUE_aktiv "Status Innenraumüberwachung
";
CM_ SG_ 1411 IRUE_Taster_Fkts_LED "Anforderung Funktions-LED IRUE-Taster (LED wird vom TSG angesteuert)
MQB: Bei Verbau eines einzelnen Taster zur Deaktivierung von IRUE und NGS wird dieses Signal zur Ansteuerung der Funktions-LED gesendet.";
CM_ SG_ 1411 ZV_BT_offen "gespiegeltes Bit BT_Tuer_geoeffnet TSG_BT_1 Botschaft";
CM_ SG_ 1411 ZV_Einzeltuerentriegelung "Einzeltürentriegelung ZV
";
CM_ SG_ 1411 ZV_FT_offen "gespiegeltes Bit FT_Tuer_geoeffnet TSG_FT_1 Botschaft";
CM_ SG_ 1411 ZV_gesafet_extern_ist "Istzustand: Fahrzeug aussen gesafet
";
CM_ SG_ 1411 ZV_gesafet_extern_soll "Sollzustand: Fahrzeug gesafet extern
";
CM_ SG_ 1411 ZV_HBFS_offen "gespiegeltes Bit HBFS_Tuer_geoeffnet TSG_HBFS_1 Botschaft";
CM_ SG_ 1411 ZV_HD_offen "Status Heckdeckel
";
CM_ SG_ 1411 ZV_Heckeinzelentriegelung "Heckdeckeleinzelentriegelung";
CM_ SG_ 1411 ZV_HFS_offen "gespiegeltes Bit HFS_Tuer_geoeffnet TSG_HFS_1 Botschaft";
CM_ SG_ 1411 ZV_HS_offen "Status Heckscheibe
";
CM_ SG_ 1411 ZV_ist_Zustand_verfuegbar "Verfügbarkeit IST-Zustand ZV

";
CM_ SG_ 1411 ZV_Oeffnungsmodus "Konfigurierter Oeffnungsmodus fuer ZV:
0 = globale Oeffnung (alle Tueren)
1 = ZV mit Einzeltuerentriegelung (FFB - nur Fahrertuer, Kessy - nur bediente Tuer)
2 = ZV individuell selektive Oeffnung (FFB - Fahrerseite, Kessy - bediente Tuer + Fahrertuer)";
CM_ SG_ 1411 ZV_Rollo_auf "Komfortöffnen des Dachrollos";
CM_ SG_ 1411 ZV_Rollo_zu "Komfortschließen des Dachrollos";
CM_ SG_ 1411 ZV_SAD_auf "Komfortöffnen des Schiebeausstelldaches";
CM_ SG_ 1411 ZV_SAD_zu "Komfortschließen des Schiebeausstelldaches";
CM_ SG_ 1411 ZV_SafeFunktion_aktiv "Statusübermittlung ob die Safe Funktion im Fzg. aktiv ist. Das Kombi benötigt das Signal, um den Text Safelock aktiv anzuzeigen. ";
CM_ SG_ 1411 ZV_Schluessel_Zugang "aktuelle Funkschlüsselnummer";
CM_ SG_ 1411 ZV_Tankklappe_offen "Öffnungsstatus der Tankklappe";
CM_ SG_ 1411 ZV_verriegelt_extern_ist "Istzustand: Verriegelung Fahrzeug aussen
";
CM_ SG_ 1411 ZV_verriegelt_extern_soll "Sollzustand: Verriegelung Fahrzeug aussen
";
CM_ SG_ 1411 ZV_verriegelt_intern_ist "Istzustand: Verriegelung Fahrzeug innen
";
CM_ SG_ 1411 ZV_verriegelt_intern_soll "Sollzustand: Verriegelung Fahrzeug innen
";
CM_ SG_ 1411 ZV_verriegelt_soll "Fahrzeug Gesamtverriegelungsstatus Sollzustand für Ladestecker- und Ladeklappenverriegelung. ";

CM_ SG_ 711 BCM2_ZV_Tasten_HMI_Anf "Trigger zum Einschalten des Touchbediendisplays und Anzeigen der ZV Tasten";
CM_ SG_ 711 BCM_Spg_Heizen_Trigger "Anforderung Spiegelheizung";
CM_ SG_ 711 ZV_FD_Taste_auf "Taster zum Öffnen der Frontklappe über BAP";
CM_ SG_ 711 ZV_HD_Taste_auf "Taster zum Öffnen der Heckklappe über BAP";
CM_ SG_ 711 ZV_HD_Taste_zu "Taster zum Schliessen der Heckklappe über BAP";
CM_ SG_ 711 ZV_TAG_verfahren "TAG Aus- oder Einfahren";
BA_DEF_REL_ BU_SG_REL_  "GenSigTimeoutTime" INT 0 65535;
BA_DEF_ BO_  "DiagRequest" ENUM "No", "Yes";
BA_DEF_ BO_  "DiagResponse" ENUM "No", "Yes";
BA_DEF_ BO_  "DiagState" ENUM "No", "Yes";
BA_DEF_ BO_  "GenMsgChkConstant" HEX 0 4095;
BA_DEF_ BO_  "GenMsgCycleTime" INT 0 65535;
BA_DEF_ BO_  "GenMsgCycleTimeFast" INT 0 65535;
BA_DEF_ BO_  "GenMsgDelayTime" INT 0 100000;
BA_DEF_ BO_  "GenMsgILSupport" ENUM "No", "Yes";
BA_DEF_ BO_  "GenMsgNrOfRepetition" INT 0 100;
BA_DEF_ BO_  "GenMsgPDUConstants" STRING;
BA_DEF_ BO_  "GenMsgSendType" ENUM "Cyclic", "not_used", "not_used", "not_used", "not_used", "not_used", "not_used", "IfActive", "NoMsgSendType";
BA_DEF_ BO_  "GenMsgStartDelayTime" INT 0 100000;
BA_DEF_ BO_  "NmMessage" ENUM "No", "Yes";
BA_DEF_ BO_  "NmhMessage" ENUM "No", "Yes";
BA_DEF_ BO_  "MsgType" ENUM "Application", "NM ", "NMH", "TP2.0", "ISO-TP ", "BAP", "EID", "KS", "XCP_PRE_CONFIGURED", "XCP_RUNTIME_CONFIGURED";
BA_DEF_ BO_  "VAGTP20_API" HEX 0 255;
BA_DEF_ BO_  "VAGTP20_DynConnection" ENUM "No", "Yes";
BA_DEF_ BO_  "VAGTP20_DynSetup" ENUM "No", "Yes";
BA_DEF_ BO_  "VAGTP20_StatConnection" ENUM "No", "Yes";
BA_DEF_ SG_  "GenSigActiveRepetitions" INT -2147483648 2147483647;
BA_DEF_ SG_  "GenSigInactiveValue" INT -2147483648 2147483647;
BA_DEF_ SG_  "GenSigSendType" ENUM "Cyclic", "OnWrite", "OnWriteWithRepetition", "OnChange", "OnChangeWithRepetition", "IfActive", "IfActiveWithRepetition", "NoSigSendType", "OnChangeAndIfActive", "OnChangeAndIfActiveWithRepetition";
BA_DEF_ SG_  "GenSigStartValue" INT -2147483648 2147483647;
BA_DEF_ SG_  "NWM-WakeupAllowed" ENUM "No", "Yes";
BA_DEF_ SG_  "GenSigFuncType" ENUM "NoFunction", "MsgCounter", "CRC-8", "XOR", "XOR-2", "DatedBit", "SW-Kl15", "CHK", "Constant", "Protocol", "CRC-8-SAE_J1850", "CRC-32", "DataLength", "DataID", "MsgCounter16", "SOK-Signatur", "Cluster";
BA_DEF_ SG_  "GenSigSwitchedByIgnition" ENUM "No", "Yes";
BA_DEF_ SG_  "Fehlerwert" HEX 0 2147483647;
BA_DEF_ SG_  "GenSigMissingSourceValue" HEX 0 2147483647;
BA_DEF_DEF_REL_  "GenSigTimeoutTime" 0;
BA_DEF_DEF_  "DiagRequest" "No";
BA_DEF_DEF_  "DiagResponse" "No";
BA_DEF_DEF_  "DiagState" "No";
BA_DEF_DEF_  "GenMsgChkConstant" 0;
BA_DEF_DEF_  "GenMsgCycleTime" 0;
BA_DEF_DEF_  "GenMsgCycleTimeFast" 0;
BA_DEF_DEF_  "GenMsgDelayTime" 0;
BA_DEF_DEF_  "GenMsgILSupport" "No";
BA_DEF_DEF_  "GenMsgNrOfRepetition" 0;
BA_DEF_DEF_  "GenMsgPDUConstants" "";
BA_DEF_DEF_  "GenMsgSendType" "NoMsgSendType";
BA_DEF_DEF_  "GenMsgStartDelayTime" 0;
BA_DEF_DEF_  "NmMessage" "No";
BA_DEF_DEF_  "NmhMessage" "No";
BA_DEF_DEF_  "MsgType" "Application";
BA_DEF_DEF_  "VAGTP20_API" 0;
BA_DEF_DEF_  "VAGTP20_DynConnection" "No";
BA_DEF_DEF_  "VAGTP20_DynSetup" "No";
BA_DEF_DEF_  "VAGTP20_StatConnection" "No";
BA_DEF_DEF_  "GenSigActiveRepetitions" 0;
BA_DEF_DEF_  "GenSigInactiveValue" 0;
BA_DEF_DEF_  "GenSigSendType" "NoSigSendType";
BA_DEF_DEF_  "GenSigStartValue" 0;
BA_DEF_DEF_  "NWM-WakeupAllowed" "No";
BA_DEF_DEF_  "GenSigFuncType" "NoFunction";
BA_DEF_DEF_  "GenSigSwitchedByIgnition" "Yes";
BA_DEF_DEF_  "Fehlerwert" 0;
BA_DEF_DEF_  "GenSigMissingSourceValue" 0;
BA_ "GenMsgCycleTime" BO_ 2589283609 500;
BA_ "GenMsgDelayTime" BO_ 2589283609 80;
BA_ "GenMsgILSupport" BO_ 2589283609 1;
BA_ "GenMsgSendType" BO_ 2589283609 0;
BA_ "GenMsgCycleTime" BO_ 1718 1000;
BA_ "GenMsgILSupport" BO_ 1718 1;
BA_ "GenMsgSendType" BO_ 1718 0;
BA_ "GenMsgCycleTime" BO_ 995 100;
BA_ "GenMsgCycleTimeFast" BO_ 995 50;
BA_ "GenMsgDelayTime" BO_ 995 50;
BA_ "GenMsgILSupport" BO_ 995 1;
BA_ "GenMsgNrOfRepetition" BO_ 995 5;
BA_ "GenMsgPDUConstants" BO_ 995 "0xad,0x1d,0xac,0x8e,0x6e,0x58,0x71,0x3b,0xce,0xc6,0x27,0x4f,0x06,0xca,0x65,0x84";
BA_ "GenMsgSendType" BO_ 995 0;
BA_ "GenMsgCycleTime" BO_ 1716 200;
BA_ "GenMsgILSupport" BO_ 1716 1;
BA_ "GenMsgSendType" BO_ 1716 0;
BA_ "GenMsgCycleTime" BO_ 385 200;
BA_ "GenMsgDelayTime" BO_ 385 40;
BA_ "GenMsgILSupport" BO_ 385 1;
BA_ "GenMsgSendType" BO_ 385 0;
BA_ "GenMsgCycleTime" BO_ 668 200;
BA_ "GenMsgDelayTime" BO_ 668 40;
BA_ "GenMsgILSupport" BO_ 668 1;
BA_ "GenMsgSendType" BO_ 668 0;
BA_ "GenMsgCycleTime" BO_ 1120 200;
BA_ "GenMsgDelayTime" BO_ 1120 40;
BA_ "GenMsgILSupport" BO_ 1120 1;
BA_ "GenMsgSendType" BO_ 1120 0;
BA_ "GenMsgCycleTime" BO_ 916 160;
BA_ "GenMsgDelayTime" BO_ 916 10;
BA_ "GenMsgILSupport" BO_ 916 1;
BA_ "GenMsgPDUConstants" BO_ 916 "0x47,0x94,0x92,0x6a,0x67,0xb5,0x0d,0x38,0xe3,0x8a,0x5d,0xb4,0x54,0xab,0xae,0x27";
BA_ "GenMsgSendType" BO_ 916 0;
BA_ "GenMsgCycleTime" BO_ 1361 200;
BA_ "GenMsgDelayTime" BO_ 1361 50;
BA_ "GenMsgILSupport" BO_ 1361 1;
BA_ "GenMsgSendType" BO_ 1361 0;
BA_ "GenMsgCycleTime" BO_ 1702 500;
BA_ "GenMsgCycleTimeFast" BO_ 1702 100;
BA_ "GenMsgDelayTime" BO_ 1702 50;
BA_ "GenMsgILSupport" BO_ 1702 1;
BA_ "GenMsgNrOfRepetition" BO_ 1702 3;
BA_ "GenMsgSendType" BO_ 1702 0;
BA_ "GenMsgCycleTime" BO_ 2527679496 320;
BA_ "GenMsgILSupport" BO_ 2527679496 1;
BA_ "GenMsgSendType" BO_ 2527679496 0;
BA_ "GenMsgCycleTime" BO_ 2589283611 1000;
BA_ "GenMsgDelayTime" BO_ 2589283611 40;
BA_ "GenMsgILSupport" BO_ 2589283611 1;
BA_ "GenMsgSendType" BO_ 2589283611 0;
BA_ "MsgType" BO_ 2617014016 6;
BA_ "MsgType" BO_ 2617014017 6;
BA_ "MsgType" BO_ 2617024256 6;
BA_ "MsgType" BO_ 2617024257 6;
BA_ "MsgType" BO_ 2617104128 6;
BA_ "MsgType" BO_ 2617104129 6;
BA_ "MsgType" BO_ 2617220608 6;
BA_ "MsgType" BO_ 2617220609 6;
BA_ "GenMsgCycleTime" BO_ 1140 1000;
BA_ "GenMsgDelayTime" BO_ 1140 40;
BA_ "GenMsgILSupport" BO_ 1140 1;
BA_ "GenMsgSendType" BO_ 1140 0;
BA_ "GenMsgCycleTime" BO_ 2589283477 2000;
BA_ "GenMsgDelayTime" BO_ 2589283477 40;
BA_ "GenMsgILSupport" BO_ 2589283477 1;
BA_ "GenMsgSendType" BO_ 2589283477 0;
BA_ "GenMsgStartDelayTime" BO_ 2589283477 70;
BA_ "GenMsgCycleTime" BO_ 2527679655 1000;
BA_ "GenMsgDelayTime" BO_ 2527679655 50;
BA_ "GenMsgILSupport" BO_ 2527679655 1;
BA_ "GenMsgSendType" BO_ 2527679655 0;
BA_ "GenMsgCycleTimeFast" BO_ 389 40;
BA_ "GenMsgDelayTime" BO_ 389 10;
BA_ "GenMsgILSupport" BO_ 389 1;
BA_ "GenMsgNrOfRepetition" BO_ 389 5;
BA_ "GenMsgSendType" BO_ 389 7;
BA_ "GenMsgCycleTimeFast" BO_ 392 40;
BA_ "GenMsgDelayTime" BO_ 392 10;
BA_ "GenMsgILSupport" BO_ 392 1;
BA_ "GenMsgNrOfRepetition" BO_ 392 5;
BA_ "GenMsgSendType" BO_ 392 7;
BA_ "GenMsgCycleTime" BO_ 388 1000;
BA_ "GenMsgCycleTimeFast" BO_ 388 20;
BA_ "GenMsgILSupport" BO_ 388 1;
BA_ "GenMsgNrOfRepetition" BO_ 388 11;
BA_ "GenMsgPDUConstants" BO_ 388 "0xe3,0xe8,0xc4,0x7f,0xf1,0x95,0xd8,0xb0,0xc7,0xa3,0xf4,0x6c,0xe7,0xc3,0x5a,0xf7";
BA_ "GenMsgSendType" BO_ 388 0;
BA_ "GenMsgCycleTime" BO_ 1411 200;
BA_ "GenMsgCycleTimeFast" BO_ 1411 50;
BA_ "GenMsgDelayTime" BO_ 1411 50;
BA_ "GenMsgILSupport" BO_ 1411 1;
BA_ "GenMsgNrOfRepetition" BO_ 1411 5;
BA_ "GenMsgSendType" BO_ 1411 0;
BA_ "GenMsgCycleTime" BO_ 711 1000;
BA_ "GenMsgCycleTimeFast" BO_ 711 20;
BA_ "GenMsgILSupport" BO_ 711 1;
BA_ "GenMsgNrOfRepetition" BO_ 711 11;
BA_ "GenMsgSendType" BO_ 711 0;
BA_ "GenSigSendType" SG_ 2589283609 UGDO_Channel_1 3;
BA_ "GenSigSwitchedByIgnition" SG_ 2589283609 UGDO_Channel_1 0;
BA_ "GenSigSendType" SG_ 2589283609 UGDO_Channel_10 3;
BA_ "GenSigSwitchedByIgnition" SG_ 2589283609 UGDO_Channel_10 0;
BA_ "GenSigSendType" SG_ 2589283609 UGDO_Channel_11 3;
BA_ "GenSigSwitchedByIgnition" SG_ 2589283609 UGDO_Channel_11 0;
BA_ "GenSigSendType" SG_ 2589283609 UGDO_Channel_12 3;
BA_ "GenSigSwitchedByIgnition" SG_ 2589283609 UGDO_Channel_12 0;
BA_ "GenSigSendType" SG_ 2589283609 UGDO_Channel_13 3;
BA_ "GenSigSwitchedByIgnition" SG_ 2589283609 UGDO_Channel_13 0;
BA_ "GenSigSendType" SG_ 2589283609 UGDO_Channel_14 3;
BA_ "GenSigSwitchedByIgnition" SG_ 2589283609 UGDO_Channel_14 0;
BA_ "GenSigSendType" SG_ 2589283609 UGDO_Channel_15 3;
BA_ "GenSigSwitchedByIgnition" SG_ 2589283609 UGDO_Channel_15 0;
BA_ "GenSigSendType" SG_ 2589283609 UGDO_Channel_2 3;
BA_ "GenSigSwitchedByIgnition" SG_ 2589283609 UGDO_Channel_2 0;
BA_ "GenSigSendType" SG_ 2589283609 UGDO_Channel_3 3;
BA_ "GenSigSwitchedByIgnition" SG_ 2589283609 UGDO_Channel_3 0;
BA_ "GenSigSendType" SG_ 2589283609 UGDO_Channel_4 3;
BA_ "GenSigSwitchedByIgnition" SG_ 2589283609 UGDO_Channel_4 0;
BA_ "GenSigSendType" SG_ 2589283609 UGDO_Channel_5 3;
BA_ "GenSigSwitchedByIgnition" SG_ 2589283609 UGDO_Channel_5 0;
BA_ "GenSigSendType" SG_ 2589283609 UGDO_Channel_6 3;
BA_ "GenSigSwitchedByIgnition" SG_ 2589283609 UGDO_Channel_6 0;
BA_ "GenSigSendType" SG_ 2589283609 UGDO_Channel_7 3;
BA_ "GenSigSwitchedByIgnition" SG_ 2589283609 UGDO_Channel_7 0;
BA_ "GenSigSendType" SG_ 2589283609 UGDO_Channel_8 3;
BA_ "GenSigSwitchedByIgnition" SG_ 2589283609 UGDO_Channel_8 0;
BA_ "GenSigSendType" SG_ 2589283609 UGDO_Channel_9 3;
BA_ "GenSigSwitchedByIgnition" SG_ 2589283609 UGDO_Channel_9 0;
BA_ "GenSigSendType" SG_ 2589283609 UGDO_DoorState 3;
BA_ "GenSigSwitchedByIgnition" SG_ 2589283609 UGDO_DoorState 0;
BA_ "GenSigSendType" SG_ 2589283609 UGDO_Failure_Antenne 0;
BA_ "Fehlerwert" SG_ 2589283609 UGDO_Failure_Antenne 1;
BA_ "GenSigSendType" SG_ 2589283609 UGDO_Failure_Codierung 0;
BA_ "Fehlerwert" SG_ 2589283609 UGDO_Failure_Codierung 1;
BA_ "GenSigSendType" SG_ 2589283609 UGDO_Failure_Hardware 0;
BA_ "Fehlerwert" SG_ 2589283609 UGDO_Failure_Hardware 1;
BA_ "GenSigSendType" SG_ 2589283609 UGDO_Function_01 0;
BA_ "Fehlerwert" SG_ 2589283609 UGDO_Function_01 7;
BA_ "GenSigSendType" SG_ 2589283609 UGDO_LED_Code_01 0;
BA_ "GenSigSendType" SG_ 2589283609 UGDO_ResponseError 0;
BA_ "Fehlerwert" SG_ 2589283609 UGDO_ResponseError 1;
BA_ "GenSigSendType" SG_ 1718 UH_DLS 0;
BA_ "GenSigSwitchedByIgnition" SG_ 1718 UH_DLS 0;
BA_ "GenSigSendType" SG_ 1718 UH_Jahr 0;
BA_ "GenSigSwitchedByIgnition" SG_ 1718 UH_Jahr 0;
BA_ "GenSigSendType" SG_ 1718 UH_Minute 0;
BA_ "GenSigSwitchedByIgnition" SG_ 1718 UH_Minute 0;
BA_ "GenSigSendType" SG_ 1718 UH_Monat 0;
BA_ "GenSigSwitchedByIgnition" SG_ 1718 UH_Monat 0;
BA_ "Fehlerwert" SG_ 1718 UH_Monat 15;
BA_ "GenSigSendType" SG_ 1718 UH_Sekunde 0;
BA_ "GenSigSwitchedByIgnition" SG_ 1718 UH_Sekunde 0;
BA_ "GenSigSendType" SG_ 1718 UH_Stunde 0;
BA_ "GenSigSwitchedByIgnition" SG_ 1718 UH_Stunde 0;
BA_ "GenSigSendType" SG_ 1718 UH_Tag 0;
BA_ "GenSigSwitchedByIgnition" SG_ 1718 UH_Tag 0;
BA_ "GenSigSendType" SG_ 1718 UH_Typ 0;
BA_ "GenSigFuncType" SG_ 1718 UH_Typ 8;
BA_ "GenSigSwitchedByIgnition" SG_ 1718 UH_Typ 0;
BA_ "GenSigSendType" SG_ 995 VD_SpannungsAnf 3;
BA_ "GenSigSwitchedByIgnition" SG_ 995 VD_SpannungsAnf 0;
BA_ "GenSigSendType" SG_ 995 Verdeck_01_BZ 0;
BA_ "GenSigFuncType" SG_ 995 Verdeck_01_BZ 1;
BA_ "GenSigSwitchedByIgnition" SG_ 995 Verdeck_01_BZ 0;
BA_ "GenSigSendType" SG_ 995 Verdeck_01_CRC 0;
BA_ "GenSigFuncType" SG_ 995 Verdeck_01_CRC 2;
BA_ "GenSigActiveRepetitions" SG_ 995 VS_BFS_AutoHoch 5;
BA_ "GenSigSendType" SG_ 995 VS_BFS_AutoHoch 4;
BA_ "GenSigSwitchedByIgnition" SG_ 995 VS_BFS_AutoHoch 0;
BA_ "GenSigActiveRepetitions" SG_ 995 VS_BFS_AutoTief 5;
BA_ "GenSigSendType" SG_ 995 VS_BFS_AutoTief 4;
BA_ "GenSigSwitchedByIgnition" SG_ 995 VS_BFS_AutoTief 0;
BA_ "GenSigActiveRepetitions" SG_ 995 VS_BFS_ManHoch 5;
BA_ "GenSigSendType" SG_ 995 VS_BFS_ManHoch 4;
BA_ "GenSigSwitchedByIgnition" SG_ 995 VS_BFS_ManHoch 0;
BA_ "GenSigActiveRepetitions" SG_ 995 VS_BFS_ManTief 5;
BA_ "GenSigSendType" SG_ 995 VS_BFS_ManTief 4;
BA_ "GenSigSwitchedByIgnition" SG_ 995 VS_BFS_ManTief 0;
BA_ "GenSigSendType" SG_ 995 VS_Buzzer 3;
BA_ "GenSigSwitchedByIgnition" SG_ 995 VS_Buzzer 0;
BA_ "GenSigSendType" SG_ 995 VS_FH_BT_Langhub 3;
BA_ "GenSigSwitchedByIgnition" SG_ 995 VS_FH_BT_Langhub 0;
BA_ "GenSigSendType" SG_ 995 VS_FH_FT_Langhub 3;
BA_ "GenSigSwitchedByIgnition" SG_ 995 VS_FH_FT_Langhub 0;
BA_ "GenSigSendType" SG_ 995 VS_FH_HBFS_Langhub 3;
BA_ "GenSigSwitchedByIgnition" SG_ 995 VS_FH_HBFS_Langhub 0;
BA_ "GenSigSendType" SG_ 995 VS_FH_HFS_Langhub 3;
BA_ "GenSigSwitchedByIgnition" SG_ 995 VS_FH_HFS_Langhub 0;
BA_ "GenSigActiveRepetitions" SG_ 995 VS_FS_AutoHoch 5;
BA_ "GenSigSendType" SG_ 995 VS_FS_AutoHoch 4;
BA_ "GenSigSwitchedByIgnition" SG_ 995 VS_FS_AutoHoch 0;
BA_ "GenSigActiveRepetitions" SG_ 995 VS_FS_AutoTief 5;
BA_ "GenSigSendType" SG_ 995 VS_FS_AutoTief 4;
BA_ "GenSigSwitchedByIgnition" SG_ 995 VS_FS_AutoTief 0;
BA_ "GenSigActiveRepetitions" SG_ 995 VS_FS_ManHoch 5;
BA_ "GenSigSendType" SG_ 995 VS_FS_ManHoch 4;
BA_ "GenSigSwitchedByIgnition" SG_ 995 VS_FS_ManHoch 0;
BA_ "GenSigActiveRepetitions" SG_ 995 VS_FS_ManTief 5;
BA_ "GenSigSendType" SG_ 995 VS_FS_ManTief 4;
BA_ "GenSigSwitchedByIgnition" SG_ 995 VS_FS_ManTief 0;
BA_ "GenSigSendType" SG_ 995 VS_Hardtop 3;
BA_ "GenSigSwitchedByIgnition" SG_ 995 VS_Hardtop 0;
BA_ "GenSigActiveRepetitions" SG_ 995 VS_HBFS_AutoHoch 5;
BA_ "GenSigSendType" SG_ 995 VS_HBFS_AutoHoch 4;
BA_ "GenSigSwitchedByIgnition" SG_ 995 VS_HBFS_AutoHoch 0;
BA_ "GenSigActiveRepetitions" SG_ 995 VS_HBFS_AutoTief 5;
BA_ "GenSigSendType" SG_ 995 VS_HBFS_AutoTief 4;
BA_ "GenSigSwitchedByIgnition" SG_ 995 VS_HBFS_AutoTief 0;
BA_ "GenSigActiveRepetitions" SG_ 995 VS_HBFS_ManHoch 5;
BA_ "GenSigSendType" SG_ 995 VS_HBFS_ManHoch 4;
BA_ "GenSigSwitchedByIgnition" SG_ 995 VS_HBFS_ManHoch 0;
BA_ "GenSigActiveRepetitions" SG_ 995 VS_HBFS_ManTief 5;
BA_ "GenSigSendType" SG_ 995 VS_HBFS_ManTief 4;
BA_ "GenSigSwitchedByIgnition" SG_ 995 VS_HBFS_ManTief 0;
BA_ "GenSigSendType" SG_ 995 VS_HD_sperren 3;
BA_ "GenSigSwitchedByIgnition" SG_ 995 VS_HD_sperren 0;
BA_ "GenSigSendType" SG_ 995 VS_Heckschloss_auf 3;
BA_ "GenSigSwitchedByIgnition" SG_ 995 VS_Heckschloss_auf 0;
BA_ "GenSigActiveRepetitions" SG_ 995 VS_HFS_AutoHoch 5;
BA_ "GenSigSendType" SG_ 995 VS_HFS_AutoHoch 4;
BA_ "GenSigSwitchedByIgnition" SG_ 995 VS_HFS_AutoHoch 0;
BA_ "GenSigActiveRepetitions" SG_ 995 VS_HFS_AutoTief 5;
BA_ "GenSigSendType" SG_ 995 VS_HFS_AutoTief 4;
BA_ "GenSigSwitchedByIgnition" SG_ 995 VS_HFS_AutoTief 0;
BA_ "GenSigActiveRepetitions" SG_ 995 VS_HFS_ManHoch 5;
BA_ "GenSigSendType" SG_ 995 VS_HFS_ManHoch 4;
BA_ "GenSigSwitchedByIgnition" SG_ 995 VS_HFS_ManHoch 0;
BA_ "GenSigActiveRepetitions" SG_ 995 VS_HFS_ManTief 5;
BA_ "GenSigSendType" SG_ 995 VS_HFS_ManTief 4;
BA_ "GenSigSwitchedByIgnition" SG_ 995 VS_HFS_ManTief 0;
BA_ "GenSigSendType" SG_ 995 VS_HHS_enable 3;
BA_ "GenSigSwitchedByIgnition" SG_ 995 VS_HHS_enable 0;
BA_ "GenSigSendType" SG_ 995 VS_Lampe_Blk 3;
BA_ "GenSigSwitchedByIgnition" SG_ 995 VS_Lampe_Blk 0;
BA_ "GenSigSendType" SG_ 995 VS_StartStopp_Info 3;
BA_ "GenSigSwitchedByIgnition" SG_ 995 VS_StartStopp_Info 0;
BA_ "Fehlerwert" SG_ 995 VS_StartStopp_Info 3;
BA_ "GenSigSendType" SG_ 995 VS_VD_Bew_auf 3;
BA_ "GenSigSwitchedByIgnition" SG_ 995 VS_VD_Bew_auf 0;
BA_ "GenSigSendType" SG_ 995 VS_VD_Bew_zu 3;
BA_ "GenSigSwitchedByIgnition" SG_ 995 VS_VD_Bew_zu 0;
BA_ "GenSigSendType" SG_ 995 VS_VD_entriegelt 3;
BA_ "GenSigSwitchedByIgnition" SG_ 995 VS_VD_entriegelt 0;
BA_ "GenSigSendType" SG_ 995 VS_VD_Fehler 3;
BA_ "GenSigSwitchedByIgnition" SG_ 995 VS_VD_Fehler 0;
BA_ "GenSigSendType" SG_ 995 VS_VD_offen_ver 3;
BA_ "GenSigSwitchedByIgnition" SG_ 995 VS_VD_offen_ver 0;
BA_ "GenSigSendType" SG_ 995 VS_VD_zu_ver 3;
BA_ "GenSigSwitchedByIgnition" SG_ 995 VS_VD_zu_ver 0;
BA_ "GenSigSendType" SG_ 995 VS_VD_Zwischenposition 3;
BA_ "GenSigSwitchedByIgnition" SG_ 995 VS_VD_Zwischenposition 0;
BA_ "GenSigSendType" SG_ 995 VS_VDKD_auf 3;
BA_ "GenSigSwitchedByIgnition" SG_ 995 VS_VDKD_auf 0;
BA_ "GenSigSendType" SG_ 995 VS_Verdeck_Anf 3;
BA_ "GenSigSwitchedByIgnition" SG_ 995 VS_Verdeck_Anf 0;
BA_ "GenSigSendType" SG_ 995 VS_Windschott_nicht_abgelegt 3;
BA_ "GenSigSwitchedByIgnition" SG_ 995 VS_Windschott_nicht_abgelegt 0;
BA_ "GenSigSendType" SG_ 995 VSG_Meldungen 3;
BA_ "GenSigSwitchedByIgnition" SG_ 995 VSG_Meldungen 0;
BA_ "GenSigSwitchedByIgnition" SG_ 1716 KS_Geheimnis_1 0;
BA_ "GenSigSwitchedByIgnition" SG_ 1716 KS_Geheimnis_2 0;
BA_ "GenSigSwitchedByIgnition" SG_ 1716 KS_Geheimnis_3 0;
BA_ "GenSigSwitchedByIgnition" SG_ 1716 KS_Geheimnis_4 0;
BA_ "GenSigSendType" SG_ 1716 VIN_01_MUX 0;
BA_ "GenSigSwitchedByIgnition" SG_ 1716 VIN_01_MUX 0;
BA_ "GenSigStartValue" SG_ 1716 VIN_1 45;
BA_ "GenSigSwitchedByIgnition" SG_ 1716 VIN_1 0;
BA_ "GenSigStartValue" SG_ 1716 VIN_10 45;
BA_ "GenSigSwitchedByIgnition" SG_ 1716 VIN_10 0;
BA_ "GenSigStartValue" SG_ 1716 VIN_11 45;
BA_ "GenSigSwitchedByIgnition" SG_ 1716 VIN_11 0;
BA_ "GenSigStartValue" SG_ 1716 VIN_12 45;
BA_ "GenSigSwitchedByIgnition" SG_ 1716 VIN_12 0;
BA_ "GenSigStartValue" SG_ 1716 VIN_13 45;
BA_ "GenSigSwitchedByIgnition" SG_ 1716 VIN_13 0;
BA_ "GenSigStartValue" SG_ 1716 VIN_14 45;
BA_ "GenSigSwitchedByIgnition" SG_ 1716 VIN_14 0;
BA_ "GenSigStartValue" SG_ 1716 VIN_15 45;
BA_ "GenSigSwitchedByIgnition" SG_ 1716 VIN_15 0;
BA_ "GenSigStartValue" SG_ 1716 VIN_16 45;
BA_ "GenSigSwitchedByIgnition" SG_ 1716 VIN_16 0;
BA_ "GenSigStartValue" SG_ 1716 VIN_17 45;
BA_ "GenSigSwitchedByIgnition" SG_ 1716 VIN_17 0;
BA_ "GenSigStartValue" SG_ 1716 VIN_2 45;
BA_ "GenSigSwitchedByIgnition" SG_ 1716 VIN_2 0;
BA_ "GenSigStartValue" SG_ 1716 VIN_3 45;
BA_ "GenSigSwitchedByIgnition" SG_ 1716 VIN_3 0;
BA_ "GenSigStartValue" SG_ 1716 VIN_4 45;
BA_ "GenSigSwitchedByIgnition" SG_ 1716 VIN_4 0;
BA_ "GenSigStartValue" SG_ 1716 VIN_5 45;
BA_ "GenSigSwitchedByIgnition" SG_ 1716 VIN_5 0;
BA_ "GenSigStartValue" SG_ 1716 VIN_6 45;
BA_ "GenSigSwitchedByIgnition" SG_ 1716 VIN_6 0;
BA_ "GenSigStartValue" SG_ 1716 VIN_7 45;
BA_ "GenSigSwitchedByIgnition" SG_ 1716 VIN_7 0;
BA_ "GenSigStartValue" SG_ 1716 VIN_8 45;
BA_ "GenSigSwitchedByIgnition" SG_ 1716 VIN_8 0;
BA_ "GenSigStartValue" SG_ 1716 VIN_9 45;
BA_ "GenSigSwitchedByIgnition" SG_ 1716 VIN_9 0;
BA_ "GenSigSendType" SG_ 385 VZE_Anzeigemodus 3;
BA_ "GenSigSendType" SG_ 385 VZE_Anzeigeunterdrueck_Zeichen_1 3;
BA_ "GenSigSendType" SG_ 385 VZE_Anzeigeunterdrueck_Zeichen_2 3;
BA_ "GenSigSendType" SG_ 385 VZE_Anzeigeunterdrueck_Zeichen_3 3;
BA_ "GenSigSendType" SG_ 385 VZE_Gong 0;
BA_ "GenSigSendType" SG_ 385 VZE_Hinweistext 3;
BA_ "GenSigSendType" SG_ 385 VZE_Verkehrszeichen_1 3;
BA_ "GenSigSendType" SG_ 385 VZE_Verkehrszeichen_2 3;
BA_ "GenSigSendType" SG_ 385 VZE_Verkehrszeichen_3 3;
BA_ "GenSigSendType" SG_ 385 VZE_Verkehrszeichen_Einheit 3;
BA_ "GenSigSwitchedByIgnition" SG_ 385 VZE_Verkehrszeichen_Einheit 0;
BA_ "GenSigSendType" SG_ 385 VZE_Warnung_Verkehrszeichen_1 3;
BA_ "GenSigSendType" SG_ 385 VZE_Warnung_Verkehrszeichen_2 3;
BA_ "GenSigSendType" SG_ 385 VZE_Warnung_Verkehrszeichen_3 3;
BA_ "GenSigSendType" SG_ 385 VZE_Zeichen_01_Gesetz 0;
BA_ "GenSigSendType" SG_ 385 VZE_Zeichen_01_Kamera 0;
BA_ "GenSigSendType" SG_ 385 VZE_Zeichen_01_KameraWied 0;
BA_ "GenSigSendType" SG_ 385 VZE_Zeichen_01_Karte 0;
BA_ "GenSigSendType" SG_ 385 VZE_Zeichen_02_Gesetz 0;
BA_ "GenSigSendType" SG_ 385 VZE_Zeichen_02_Kamera 0;
BA_ "GenSigSendType" SG_ 385 VZE_Zeichen_02_KameraWied 0;
BA_ "GenSigSendType" SG_ 385 VZE_Zeichen_02_Karte 0;
BA_ "GenSigSendType" SG_ 385 VZE_Zeichen_03_Gesetz 0;
BA_ "GenSigSendType" SG_ 385 VZE_Zeichen_03_Kamera 0;
BA_ "GenSigSendType" SG_ 385 VZE_Zeichen_03_KameraWied 0;
BA_ "GenSigSendType" SG_ 385 VZE_Zeichen_03_Karte 0;
BA_ "GenSigSendType" SG_ 385 VZE_Zusatzschild_1 3;
BA_ "GenSigSendType" SG_ 385 VZE_Zusatzschild_2 3;
BA_ "GenSigSendType" SG_ 385 VZE_Zusatzschild_3 3;
BA_ "GenSigSendType" SG_ 668 VZE_Anhaenger_Vmax 3;
BA_ "GenSigStartValue" SG_ 668 VZE_Anhaenger_Vmax 14;
BA_ "Fehlerwert" SG_ 668 VZE_Anhaenger_Vmax 15;
BA_ "GenSigSendType" SG_ 668 VZE_Anzeigeunterdrueck_Zeichen_4 3;
BA_ "GenSigSendType" SG_ 668 VZE_Anzeigeunterdrueck_Zeichen_5 3;
BA_ "GenSigSendType" SG_ 668 VZE_Baustelle 0;
BA_ "GenSigSendType" SG_ 668 VZE_Verkehrszeichen_4 3;
BA_ "GenSigSendType" SG_ 668 VZE_Verkehrszeichen_5 3;
BA_ "GenSigSendType" SG_ 668 VZE_Warnung_Verkehrszeichen_4 3;
BA_ "GenSigSendType" SG_ 668 VZE_Warnung_Verkehrszeichen_5 3;
BA_ "GenSigSendType" SG_ 668 VZE_Zeichen_04_Gesetz 0;
BA_ "GenSigSendType" SG_ 668 VZE_Zeichen_04_Kamera 0;
BA_ "GenSigSendType" SG_ 668 VZE_Zeichen_04_KameraWied 0;
BA_ "GenSigSendType" SG_ 668 VZE_Zeichen_04_Karte 0;
BA_ "GenSigSendType" SG_ 668 VZE_Zeichen_05_Entfernung 0;
BA_ "GenSigSendType" SG_ 668 VZE_Zeichen_05_Entfernung_StdA 0;
BA_ "GenSigSendType" SG_ 668 VZE_Zeichen_05_Gesetz 0;
BA_ "GenSigSendType" SG_ 668 VZE_Zeichen_05_Kamera 0;
BA_ "GenSigSendType" SG_ 668 VZE_Zeichen_05_KameraWied 0;
BA_ "GenSigSendType" SG_ 668 VZE_Zeichen_05_Karte 0;
BA_ "GenSigSendType" SG_ 668 VZE_Zusatzschild_4 3;
BA_ "GenSigSendType" SG_ 668 VZE_Zusatzschild_5 3;
BA_ "GenSigSendType" SG_ 1120 VZE_Erweiterte_Information 3;
BA_ "GenSigSendType" SG_ 1120 VZE_Tempowarnung_Einheit 0;
BA_ "GenSigSendType" SG_ 1120 VZE_Tempowarnung_Offset 0;
BA_ "GenSigSendType" SG_ 1120 VZE_Tempowarnung_Status 0;
BA_ "GenSigSwitchedByIgnition" SG_ 1120 VZE_Tempowarnung_Status 0;
BA_ "GenSigSendType" SG_ 1120 VZE_Umweltinfo_Anhaengerbetrieb 0;
BA_ "GenSigSendType" SG_ 1120 VZE_Umweltinfo_Naesse 0;
BA_ "GenSigSendType" SG_ 1120 VZE_Umweltinfo_Nebel 0;
BA_ "GenSigSendType" SG_ 1120 VZE_Verkehrszeichen_6 3;
BA_ "GenSigSendType" SG_ 1120 VZE_Zeichen_06_Entfernung 3;
BA_ "GenSigSendType" SG_ 1120 VZE_Zeichen_06_Entfernung_StdA 3;
BA_ "GenSigSendType" SG_ 1120 VZE_Zusatzschild_6 3;
BA_ "GenSigSendType" SG_ 916 GE_Sollgang 3;
BA_ "GenSigSwitchedByIgnition" SG_ 916 GE_Sollgang 0;
BA_ "GenSigSendType" SG_ 916 GE_Stoppverbot_Anz_01 3;
BA_ "GenSigSwitchedByIgnition" SG_ 916 GE_Stoppverbot_Anz_01 0;
BA_ "GenSigSendType" SG_ 916 GE_Stoppverbot_Anz_02 3;
BA_ "GenSigSwitchedByIgnition" SG_ 916 GE_Stoppverbot_Anz_02 0;
BA_ "GenSigSendType" SG_ 916 GE_Stoppverbot_Anz_03 3;
BA_ "GenSigSwitchedByIgnition" SG_ 916 GE_Stoppverbot_Anz_03 0;
BA_ "GenSigSendType" SG_ 916 GE_Stoppverbot_Anz_04 3;
BA_ "GenSigSwitchedByIgnition" SG_ 916 GE_Stoppverbot_Anz_04 0;
BA_ "GenSigSendType" SG_ 916 GE_Stoppverbot_Anz_05 3;
BA_ "GenSigSwitchedByIgnition" SG_ 916 GE_Stoppverbot_Anz_05 0;
BA_ "GenSigSendType" SG_ 916 GE_Stoppverbot_Anz_06 3;
BA_ "GenSigSwitchedByIgnition" SG_ 916 GE_Stoppverbot_Anz_06 0;
BA_ "GenSigSendType" SG_ 916 GE_Stoppverbot_Anz_07 3;
BA_ "GenSigSwitchedByIgnition" SG_ 916 GE_Stoppverbot_Anz_07 0;
BA_ "GenSigSendType" SG_ 916 GE_Stoppverbot_Anz_Std 3;
BA_ "GenSigSwitchedByIgnition" SG_ 916 GE_Stoppverbot_Anz_Std 0;
BA_ "GenSigSendType" SG_ 916 GE_Tipschaltempf_verfuegbar 3;
BA_ "GenSigFuncType" SG_ 916 GE_Tipschaltempf_verfuegbar 8;
BA_ "GenSigSwitchedByIgnition" SG_ 916 GE_Tipschaltempf_verfuegbar 0;
BA_ "GenSigSendType" SG_ 916 GE_Wiederstart_Anz_Std 3;
BA_ "GenSigSwitchedByIgnition" SG_ 916 GE_Wiederstart_Anz_Std 0;
BA_ "GenSigSendType" SG_ 916 WBA_03_BZ 0;
BA_ "GenSigFuncType" SG_ 916 WBA_03_BZ 1;
BA_ "GenSigSwitchedByIgnition" SG_ 916 WBA_03_BZ 0;
BA_ "GenSigSendType" SG_ 916 WBA_03_CRC 0;
BA_ "GenSigFuncType" SG_ 916 WBA_03_CRC 2;
BA_ "GenSigSwitchedByIgnition" SG_ 916 WBA_03_CRC 0;
BA_ "GenSigSendType" SG_ 916 WBA_Blinken 3;
BA_ "GenSigSwitchedByIgnition" SG_ 916 WBA_Blinken 0;
BA_ "GenSigSendType" SG_ 916 WBA_eing_Gang_02 3;
BA_ "GenSigSwitchedByIgnition" SG_ 916 WBA_eing_Gang_02 0;
BA_ "GenSigSendType" SG_ 916 WBA_Fahrstufe_02 3;
BA_ "GenSigSwitchedByIgnition" SG_ 916 WBA_Fahrstufe_02 0;
BA_ "GenSigSendType" SG_ 916 WBA_GE_Texte 3;
BA_ "GenSigSwitchedByIgnition" SG_ 916 WBA_GE_Texte 0;
BA_ "GenSigSendType" SG_ 916 WBA_GE_Texte_02 3;
BA_ "GenSigSwitchedByIgnition" SG_ 916 WBA_GE_Texte_02 0;
BA_ "GenSigSendType" SG_ 916 WBA_GE_Texte_03 0;
BA_ "GenSigSwitchedByIgnition" SG_ 916 WBA_GE_Texte_03 0;
BA_ "Fehlerwert" SG_ 916 WBA_GE_Texte_03 15;
BA_ "GenSigSendType" SG_ 916 WBA_GE_Warnung_02 3;
BA_ "GenSigSwitchedByIgnition" SG_ 916 WBA_GE_Warnung_02 0;
BA_ "GenSigSendType" SG_ 916 WBA_GE_Zusatzwarnungen 3;
BA_ "GenSigSwitchedByIgnition" SG_ 916 WBA_GE_Zusatzwarnungen 0;
BA_ "GenSigSendType" SG_ 916 WBA_Schaltschema 3;
BA_ "GenSigSwitchedByIgnition" SG_ 916 WBA_Schaltschema 0;
BA_ "GenSigSendType" SG_ 916 WBA_Segeln_aktiv 3;
BA_ "GenSigSwitchedByIgnition" SG_ 916 WBA_Segeln_aktiv 0;
BA_ "GenSigSendType" SG_ 916 WBA_ZielFahrstufe 3;
BA_ "GenSigSwitchedByIgnition" SG_ 916 WBA_ZielFahrstufe 0;
BA_ "GenSigSendType" SG_ 1361 WFS_Betrieb_Lesespule 3;
BA_ "GenSigSwitchedByIgnition" SG_ 1361 WFS_Betrieb_Lesespule 0;
BA_ "GenSigSendType" SG_ 1361 WFS_ELV_authorisiert 3;
BA_ "GenSigSwitchedByIgnition" SG_ 1361 WFS_ELV_authorisiert 0;
BA_ "GenSigSendType" SG_ 1361 WFS_Fahrerhinweise 3;
BA_ "GenSigSwitchedByIgnition" SG_ 1361 WFS_Fahrerhinweise 0;
BA_ "GenSigSendType" SG_ 1361 WFS_ID_Geb_autorisiert 3;
BA_ "GenSigSwitchedByIgnition" SG_ 1361 WFS_ID_Geb_autorisiert 0;
BA_ "GenSigSendType" SG_ 1361 WFS_ID_Geb_autorisiert_in_Kl15 3;
BA_ "GenSigSwitchedByIgnition" SG_ 1361 WFS_ID_Geb_autorisiert_in_Kl15 0;
BA_ "GenSigSendType" SG_ 1361 WFS_ID_Geb_steckt 3;
BA_ "GenSigSwitchedByIgnition" SG_ 1361 WFS_ID_Geb_steckt 0;
BA_ "GenSigSendType" SG_ 1361 WFS_Klemmenfreigabe 3;
BA_ "GenSigSwitchedByIgnition" SG_ 1361 WFS_Klemmenfreigabe 0;
BA_ "GenSigSendType" SG_ 1361 WFS_LF_Aktiv 3;
BA_ "GenSigSwitchedByIgnition" SG_ 1361 WFS_LF_Aktiv 0;
BA_ "GenSigSendType" SG_ 1361 WFS_LZ 3;
BA_ "GenSigSwitchedByIgnition" SG_ 1361 WFS_LZ 0;
BA_ "GenSigSendType" SG_ 1361 WFS_Parken_Status 3;
BA_ "GenSigSwitchedByIgnition" SG_ 1361 WFS_Parken_Status 0;
BA_ "GenSigSendType" SG_ 1361 WFS_Safe 3;
BA_ "GenSigSwitchedByIgnition" SG_ 1361 WFS_Safe 0;
BA_ "GenSigSendType" SG_ 1361 WFS_Schluessel_Fahrberecht 0;
BA_ "GenSigSwitchedByIgnition" SG_ 1361 WFS_Schluessel_Fahrberecht 0;
BA_ "GenSigSendType" SG_ 1361 WFS_Schluessel_Ist 3;
BA_ "GenSigSwitchedByIgnition" SG_ 1361 WFS_Schluessel_Ist 0;
BA_ "GenSigSendType" SG_ 1361 WFS_Schluessel_Soll 3;
BA_ "GenSigSwitchedByIgnition" SG_ 1361 WFS_Schluessel_Soll 0;
BA_ "GenSigSendType" SG_ 1702 BCM1_SRA_aktiv 3;
BA_ "GenSigSwitchedByIgnition" SG_ 1702 BCM1_SRA_aktiv 0;
BA_ "GenSigActiveRepetitions" SG_ 1702 Heckwischer_Anforderung 3;
BA_ "GenSigSendType" SG_ 1702 Heckwischer_Anforderung 4;
BA_ "GenSigSwitchedByIgnition" SG_ 1702 Heckwischer_Anforderung 0;
BA_ "GenSigSendType" SG_ 1702 Waschen_vorne_aktiv 3;
BA_ "GenSigSwitchedByIgnition" SG_ 1702 Waschen_vorne_aktiv 0;
BA_ "GenSigSendType" SG_ 1702 Wischer1_Wischgeschwindigkeit 0;
BA_ "GenSigStartValue" SG_ 1702 Wischer1_Wischgeschwindigkeit 62;
BA_ "GenSigSwitchedByIgnition" SG_ 1702 Wischer1_Wischgeschwindigkeit 0;
BA_ "GenSigSendType" SG_ 1702 Wischer_Anzeigetext 3;
BA_ "GenSigSwitchedByIgnition" SG_ 1702 Wischer_Anzeigetext 0;
BA_ "GenSigSendType" SG_ 1702 Wischer_vorne_aktiv 3;
BA_ "GenSigSwitchedByIgnition" SG_ 1702 Wischer_vorne_aktiv 0;
BA_ "GenSigSendType" SG_ 1702 Wischer_vorne_blockiert 3;
BA_ "GenSigSwitchedByIgnition" SG_ 1702 Wischer_vorne_blockiert 0;
BA_ "GenSigSendType" SG_ 1702 Wischer_vorne_defekt 3;
BA_ "GenSigSwitchedByIgnition" SG_ 1702 Wischer_vorne_defekt 0;
BA_ "GenSigSendType" SG_ 1702 Wischer_vorne_Normal 3;
BA_ "GenSigSwitchedByIgnition" SG_ 1702 Wischer_vorne_Normal 0;
BA_ "GenSigSendType" SG_ 1702 Wischer_vorne_Parklage 3;
BA_ "GenSigStartValue" SG_ 1702 Wischer_vorne_Parklage 1;
BA_ "GenSigSwitchedByIgnition" SG_ 1702 Wischer_vorne_Parklage 0;
BA_ "GenSigSendType" SG_ 1702 Wischer_vorne_Schnell 3;
BA_ "GenSigSwitchedByIgnition" SG_ 1702 Wischer_vorne_Schnell 0;
BA_ "GenSigSendType" SG_ 1702 WWSs_01_upd 0;
BA_ "GenSigFuncType" SG_ 1702 WWSs_01_upd 5;
BA_ "GenSigSwitchedByIgnition" SG_ 1702 WWSs_01_upd 0;
BA_ "GenSigSendType" SG_ 2527679496 WIV_Russindex_02 0;
BA_ "GenSigSwitchedByIgnition" SG_ 2527679496 WIV_Russindex_02 0;
BA_ "GenSigSendType" SG_ 2527679496 WIV_Russindex_Ueberlauf 0;
BA_ "GenSigSwitchedByIgnition" SG_ 2527679496 WIV_Russindex_Ueberlauf 0;
BA_ "GenSigSendType" SG_ 2527679496 WIV_t_max 0;
BA_ "GenSigStartValue" SG_ 2527679496 WIV_t_max 24;
BA_ "GenSigSwitchedByIgnition" SG_ 2527679496 WIV_t_max 0;
BA_ "GenSigSendType" SG_ 2527679496 WIV_t_min 0;
BA_ "GenSigStartValue" SG_ 2527679496 WIV_t_min 12;
BA_ "GenSigSwitchedByIgnition" SG_ 2527679496 WIV_t_min 0;
BA_ "GenSigSendType" SG_ 2527679496 WIV_Verschleissindex_02 0;
BA_ "GenSigSwitchedByIgnition" SG_ 2527679496 WIV_Verschleissindex_02 0;
BA_ "GenSigSendType" SG_ 2527679496 WIV_Verschleissindex_Ueberlauf 0;
BA_ "GenSigSwitchedByIgnition" SG_ 2527679496 WIV_Verschleissindex_Ueberlauf 0;
BA_ "GenSigSendType" SG_ 2527679496 WIV_W_max 0;
BA_ "GenSigStartValue" SG_ 2527679496 WIV_W_max 31;
BA_ "GenSigSwitchedByIgnition" SG_ 2527679496 WIV_W_max 0;
BA_ "GenSigSendType" SG_ 2527679496 WIV_W_min 0;
BA_ "GenSigStartValue" SG_ 2527679496 WIV_W_min 17;
BA_ "GenSigSwitchedByIgnition" SG_ 2527679496 WIV_W_min 0;
BA_ "GenSigSendType" SG_ 2589283611 WLC1_aktive_Spule 3;
BA_ "GenSigSwitchedByIgnition" SG_ 2589283611 WLC1_aktive_Spule 0;
BA_ "GenSigSendType" SG_ 2589283611 WLC1_Charger_Effizienz 3;
BA_ "GenSigSwitchedByIgnition" SG_ 2589283611 WLC1_Charger_Effizienz 0;
BA_ "GenSigSendType" SG_ 2589283611 WLC1_Charger_laedt 3;
BA_ "GenSigSwitchedByIgnition" SG_ 2589283611 WLC1_Charger_laedt 0;
BA_ "GenSigSendType" SG_ 2589283611 WLC1_Fremdobjekt_erkannt 3;
BA_ "GenSigSwitchedByIgnition" SG_ 2589283611 WLC1_Fremdobjekt_erkannt 0;
BA_ "GenSigSendType" SG_ 2589283611 WLC1_Leistungsklasse_Receiver 0;
BA_ "GenSigSwitchedByIgnition" SG_ 2589283611 WLC1_Leistungsklasse_Receiver 0;
BA_ "GenSigSendType" SG_ 2589283611 WLC1_Objekt_erkannt 3;
BA_ "GenSigSwitchedByIgnition" SG_ 2589283611 WLC1_Objekt_erkannt 0;
BA_ "GenSigSendType" SG_ 2589283611 WLC1_Receiver_erkannt 3;
BA_ "GenSigSwitchedByIgnition" SG_ 2589283611 WLC1_Receiver_erkannt 0;
BA_ "GenSigSendType" SG_ 2589283611 WLC1_Receiver_voll_geladen 3;
BA_ "GenSigSwitchedByIgnition" SG_ 2589283611 WLC1_Receiver_voll_geladen 0;
BA_ "GenSigSendType" SG_ 2589283611 WLC1_Temp_Leistungsteil_Charger 0;
BA_ "GenSigSwitchedByIgnition" SG_ 2589283611 WLC1_Temp_Leistungsteil_Charger 0;
BA_ "GenSigSendType" SG_ 2589283611 WLC1_Temp_Oberfaeche_Charger 0;
BA_ "GenSigSwitchedByIgnition" SG_ 2589283611 WLC1_Temp_Oberfaeche_Charger 0;
BA_ "GenSigSendType" SG_ 2589283611 WLC1_Temp_Receiver 0;
BA_ "GenSigSwitchedByIgnition" SG_ 2589283611 WLC1_Temp_Receiver 0;
BA_ "GenSigSendType" SG_ 2589283611 WLC1_verwendeter_Ladestandard 0;
BA_ "GenSigSwitchedByIgnition" SG_ 2589283611 WLC1_verwendeter_Ladestandard 0;
BA_ "GenSigSwitchedByIgnition" SG_ 2617014016 XCP_BedienDisp_vo_CRO_01_Data 0;
BA_ "GenSigSwitchedByIgnition" SG_ 2617014017 XCP_BedienDisp_vo_DTO_01_Data 0;
BA_ "GenSigSwitchedByIgnition" SG_ 2617024256 XCP_BedienSG_hi_CRO_01_Data 0;
BA_ "GenSigSwitchedByIgnition" SG_ 2617024257 XCP_BedienSG_hi_DTO_01_Data 0;
BA_ "GenSigSwitchedByIgnition" SG_ 2617104128 XCP_DDA_CRO_01_Data 0;
BA_ "GenSigSwitchedByIgnition" SG_ 2617104129 XCP_DDA_DTO_01_Data 0;
BA_ "GenSigSwitchedByIgnition" SG_ 2617220608 XCP_Info_El_CRO_01_Data 0;
BA_ "GenSigSwitchedByIgnition" SG_ 2617220609 XCP_Info_El_DTO_01_Data 0;
BA_ "GenSigSendType" SG_ 1140 MMI_State 3;
BA_ "GenSigSwitchedByIgnition" SG_ 1140 MMI_State 0;
BA_ "GenSigSendType" SG_ 1140 SI_ICAN 3;
BA_ "GenSigStartValue" SG_ 1140 SI_ICAN 1;
BA_ "GenSigSwitchedByIgnition" SG_ 1140 SI_ICAN 0;
BA_ "GenSigSendType" SG_ 1140 WLC1_Systemzustand 3;
BA_ "GenSigSwitchedByIgnition" SG_ 1140 WLC1_Systemzustand 0;
BA_ "GenSigSendType" SG_ 1140 WLC2_Systemzustand 3;
BA_ "GenSigSwitchedByIgnition" SG_ 1140 WLC2_Systemzustand 0;
BA_ "GenSigSendType" SG_ 1140 ZR_DimOffs_DU_1 3;
BA_ "GenSigStartValue" SG_ 1140 ZR_DimOffs_DU_1 14;
BA_ "GenSigSwitchedByIgnition" SG_ 1140 ZR_DimOffs_DU_1 0;
BA_ "GenSigSendType" SG_ 1140 ZR_DimOffs_DU_2 3;
BA_ "GenSigStartValue" SG_ 1140 ZR_DimOffs_DU_2 14;
BA_ "GenSigSwitchedByIgnition" SG_ 1140 ZR_DimOffs_DU_2 0;
BA_ "GenSigSendType" SG_ 1140 ZR_DimOffs_DU_3 3;
BA_ "GenSigStartValue" SG_ 1140 ZR_DimOffs_DU_3 14;
BA_ "GenSigSwitchedByIgnition" SG_ 1140 ZR_DimOffs_DU_3 0;
BA_ "GenSigSendType" SG_ 1140 ZR_DimOffs_DU_4 3;
BA_ "GenSigSwitchedByIgnition" SG_ 1140 ZR_DimOffs_DU_4 0;
BA_ "GenSigSendType" SG_ 1140 ZR_LeistungSaeule 3;
BA_ "GenSigSwitchedByIgnition" SG_ 1140 ZR_LeistungSaeule 0;
BA_ "GenSigSendType" SG_ 1140 ZR_Lenkerposition 0;
BA_ "GenSigSwitchedByIgnition" SG_ 1140 ZR_Lenkerposition 0;
BA_ "GenSigSendType" SG_ 1140 ZR_SOCSaeule 3;
BA_ "GenSigSwitchedByIgnition" SG_ 1140 ZR_SOCSaeule 0;
BA_ "GenSigSendType" SG_ 1140 ZR_SpannungSaeule 3;
BA_ "GenSigSwitchedByIgnition" SG_ 1140 ZR_SpannungSaeule 0;
BA_ "GenSigSendType" SG_ 1140 ZR_State_DU_1 3;
BA_ "GenSigSwitchedByIgnition" SG_ 1140 ZR_State_DU_1 0;
BA_ "GenSigSendType" SG_ 1140 ZR_State_DU_2 3;
BA_ "GenSigSwitchedByIgnition" SG_ 1140 ZR_State_DU_2 0;
BA_ "GenSigSendType" SG_ 1140 ZR_State_DU_3 3;
BA_ "GenSigSwitchedByIgnition" SG_ 1140 ZR_State_DU_3 0;
BA_ "GenSigSendType" SG_ 1140 ZR_State_DU_4 3;
BA_ "GenSigSwitchedByIgnition" SG_ 1140 ZR_State_DU_4 0;
BA_ "GenSigSendType" SG_ 1140 ZR_t_naechsteLadung 3;
BA_ "GenSigSwitchedByIgnition" SG_ 1140 ZR_t_naechsteLadung 0;
BA_ "GenSigSendType" SG_ 1140 ZR_WecktGesp 3;
BA_ "GenSigSwitchedByIgnition" SG_ 1140 ZR_WecktGesp 0;
BA_ "GenSigSendType" SG_ 2589283477 MMI_State 3;
BA_ "GenSigSwitchedByIgnition" SG_ 2589283477 MMI_State 0;
BA_ "GenSigSendType" SG_ 2589283477 MU_ActiveTime_MIBCAN 0;
BA_ "GenSigSwitchedByIgnition" SG_ 2589283477 MU_ActiveTime_MIBCAN 0;
BA_ "GenSigSendType" SG_ 2589283477 MU_ActiveTime_MOST 0;
BA_ "GenSigSwitchedByIgnition" SG_ 2589283477 MU_ActiveTime_MOST 0;
BA_ "GenSigSendType" SG_ 2589283477 MU_CTR_MOST_OFF_ON 0;
BA_ "GenSigSwitchedByIgnition" SG_ 2589283477 MU_CTR_MOST_OFF_ON 0;
BA_ "GenSigSendType" SG_ 2589283477 MU_CTR_Startup_MainUnit 0;
BA_ "GenSigSwitchedByIgnition" SG_ 2589283477 MU_CTR_Startup_MainUnit 0;
BA_ "GenSigSendType" SG_ 2589283477 MU_MOST_State 0;
BA_ "GenSigSwitchedByIgnition" SG_ 2589283477 MU_MOST_State 0;
BA_ "GenSigSendType" SG_ 2589283477 MU_OnlineTime_MainUnit 0;
BA_ "GenSigSwitchedByIgnition" SG_ 2589283477 MU_OnlineTime_MainUnit 0;
BA_ "GenSigSendType" SG_ 2589283477 MU_OnTime_MainUnit 0;
BA_ "GenSigSwitchedByIgnition" SG_ 2589283477 MU_OnTime_MainUnit 0;
BA_ "GenSigSendType" SG_ 2589283477 MU_StandbyTime_MainUnit 0;
BA_ "GenSigSwitchedByIgnition" SG_ 2589283477 MU_StandbyTime_MainUnit 0;
BA_ "GenSigSendType" SG_ 2527679655 MMI_StartupAnimation 3;
BA_ "GenSigSwitchedByIgnition" SG_ 2527679655 MMI_StartupAnimation 0;
BA_ "GenSigSendType" SG_ 2527679655 ZR_SOC_Weiterfahrt 3;
BA_ "GenSigSwitchedByIgnition" SG_ 2527679655 ZR_SOC_Weiterfahrt 0;
BA_ "GenSigActiveRepetitions" SG_ 389 Krypt_Schluesselschalter_auf 5;
BA_ "GenSigSendType" SG_ 389 Krypt_Schluesselschalter_auf 9;
BA_ "GenSigSwitchedByIgnition" SG_ 389 Krypt_Schluesselschalter_auf 0;
BA_ "GenSigActiveRepetitions" SG_ 389 Krypt_Schluesselschalter_zu 5;
BA_ "GenSigSendType" SG_ 389 Krypt_Schluesselschalter_zu 9;
BA_ "GenSigSwitchedByIgnition" SG_ 389 Krypt_Schluesselschalter_zu 0;
BA_ "GenSigActiveRepetitions" SG_ 389 Krypt_Signatur 5;
BA_ "GenSigSendType" SG_ 389 Krypt_Signatur 4;
BA_ "GenSigSwitchedByIgnition" SG_ 389 Krypt_Signatur 0;
BA_ "GenSigActiveRepetitions" SG_ 389 ZFH_BFS_AutoHoch 5;
BA_ "GenSigSendType" SG_ 389 ZFH_BFS_AutoHoch 9;
BA_ "GenSigSwitchedByIgnition" SG_ 389 ZFH_BFS_AutoHoch 0;
BA_ "GenSigActiveRepetitions" SG_ 389 ZFH_BFS_AutoTief 5;
BA_ "GenSigSendType" SG_ 389 ZFH_BFS_AutoTief 9;
BA_ "GenSigSwitchedByIgnition" SG_ 389 ZFH_BFS_AutoTief 0;
BA_ "GenSigActiveRepetitions" SG_ 389 ZFH_BFS_ManHoch 5;
BA_ "GenSigSendType" SG_ 389 ZFH_BFS_ManHoch 9;
BA_ "GenSigSwitchedByIgnition" SG_ 389 ZFH_BFS_ManHoch 0;
BA_ "GenSigActiveRepetitions" SG_ 389 ZFH_BFS_ManTief 5;
BA_ "GenSigSendType" SG_ 389 ZFH_BFS_ManTief 9;
BA_ "GenSigSwitchedByIgnition" SG_ 389 ZFH_BFS_ManTief 0;
BA_ "GenSigActiveRepetitions" SG_ 389 ZFH_FS_AutoHoch 5;
BA_ "GenSigSendType" SG_ 389 ZFH_FS_AutoHoch 9;
BA_ "GenSigSwitchedByIgnition" SG_ 389 ZFH_FS_AutoHoch 0;
BA_ "GenSigActiveRepetitions" SG_ 389 ZFH_FS_AutoTief 5;
BA_ "GenSigSendType" SG_ 389 ZFH_FS_AutoTief 9;
BA_ "GenSigSwitchedByIgnition" SG_ 389 ZFH_FS_AutoTief 0;
BA_ "GenSigActiveRepetitions" SG_ 389 ZFH_FS_ManHoch 5;
BA_ "GenSigSendType" SG_ 389 ZFH_FS_ManHoch 9;
BA_ "GenSigSwitchedByIgnition" SG_ 389 ZFH_FS_ManHoch 0;
BA_ "GenSigActiveRepetitions" SG_ 389 ZFH_FS_ManTief 5;
BA_ "GenSigSendType" SG_ 389 ZFH_FS_ManTief 9;
BA_ "GenSigSwitchedByIgnition" SG_ 389 ZFH_FS_ManTief 0;
BA_ "GenSigActiveRepetitions" SG_ 389 ZFH_HBFS_AutoHoch 5;
BA_ "GenSigSendType" SG_ 389 ZFH_HBFS_AutoHoch 9;
BA_ "GenSigSwitchedByIgnition" SG_ 389 ZFH_HBFS_AutoHoch 0;
BA_ "GenSigActiveRepetitions" SG_ 389 ZFH_HBFS_AutoTief 5;
BA_ "GenSigSendType" SG_ 389 ZFH_HBFS_AutoTief 9;
BA_ "GenSigSwitchedByIgnition" SG_ 389 ZFH_HBFS_AutoTief 0;
BA_ "GenSigActiveRepetitions" SG_ 389 ZFH_HBFS_ManHoch 5;
BA_ "GenSigSendType" SG_ 389 ZFH_HBFS_ManHoch 9;
BA_ "GenSigSwitchedByIgnition" SG_ 389 ZFH_HBFS_ManHoch 0;
BA_ "GenSigActiveRepetitions" SG_ 389 ZFH_HBFS_ManTief 5;
BA_ "GenSigSendType" SG_ 389 ZFH_HBFS_ManTief 9;
BA_ "GenSigSwitchedByIgnition" SG_ 389 ZFH_HBFS_ManTief 0;
BA_ "GenSigActiveRepetitions" SG_ 389 ZFH_HFS_AutoHoch 5;
BA_ "GenSigSendType" SG_ 389 ZFH_HFS_AutoHoch 9;
BA_ "GenSigSwitchedByIgnition" SG_ 389 ZFH_HFS_AutoHoch 0;
BA_ "GenSigActiveRepetitions" SG_ 389 ZFH_HFS_AutoTief 5;
BA_ "GenSigSendType" SG_ 389 ZFH_HFS_AutoTief 9;
BA_ "GenSigSwitchedByIgnition" SG_ 389 ZFH_HFS_AutoTief 0;
BA_ "GenSigActiveRepetitions" SG_ 389 ZFH_HFS_ManHoch 5;
BA_ "GenSigSendType" SG_ 389 ZFH_HFS_ManHoch 9;
BA_ "GenSigSwitchedByIgnition" SG_ 389 ZFH_HFS_ManHoch 0;
BA_ "GenSigActiveRepetitions" SG_ 389 ZFH_HFS_ManTief 5;
BA_ "GenSigSendType" SG_ 389 ZFH_HFS_ManTief 9;
BA_ "GenSigSwitchedByIgnition" SG_ 389 ZFH_HFS_ManTief 0;
BA_ "GenSigActiveRepetitions" SG_ 389 ZFH_zentral_auf 5;
BA_ "GenSigSendType" SG_ 389 ZFH_zentral_auf 9;
BA_ "GenSigSwitchedByIgnition" SG_ 389 ZFH_zentral_auf 0;
BA_ "GenSigActiveRepetitions" SG_ 389 ZFH_zentral_zu 5;
BA_ "GenSigSendType" SG_ 389 ZFH_zentral_zu 9;
BA_ "GenSigSwitchedByIgnition" SG_ 389 ZFH_zentral_zu 0;
BA_ "GenSigActiveRepetitions" SG_ 392 BT_FH_BT_AutoHoch 5;
BA_ "GenSigSendType" SG_ 392 BT_FH_BT_AutoHoch 9;
BA_ "GenSigSwitchedByIgnition" SG_ 392 BT_FH_BT_AutoHoch 0;
BA_ "GenSigActiveRepetitions" SG_ 392 BT_FH_BT_AutoTief 5;
BA_ "GenSigSendType" SG_ 392 BT_FH_BT_AutoTief 9;
BA_ "GenSigSwitchedByIgnition" SG_ 392 BT_FH_BT_AutoTief 0;
BA_ "GenSigActiveRepetitions" SG_ 392 BT_FH_BT_ManHoch 5;
BA_ "GenSigSendType" SG_ 392 BT_FH_BT_ManHoch 9;
BA_ "GenSigSwitchedByIgnition" SG_ 392 BT_FH_BT_ManHoch 0;
BA_ "GenSigActiveRepetitions" SG_ 392 BT_FH_BT_ManTief 5;
BA_ "GenSigSendType" SG_ 392 BT_FH_BT_ManTief 9;
BA_ "GenSigSwitchedByIgnition" SG_ 392 BT_FH_BT_ManTief 0;
BA_ "GenSigActiveRepetitions" SG_ 392 BT_FH_FT_AutoHoch 5;
BA_ "GenSigSendType" SG_ 392 BT_FH_FT_AutoHoch 9;
BA_ "GenSigSwitchedByIgnition" SG_ 392 BT_FH_FT_AutoHoch 0;
BA_ "GenSigActiveRepetitions" SG_ 392 BT_FH_FT_AutoTief 5;
BA_ "GenSigSendType" SG_ 392 BT_FH_FT_AutoTief 9;
BA_ "GenSigSwitchedByIgnition" SG_ 392 BT_FH_FT_AutoTief 0;
BA_ "GenSigActiveRepetitions" SG_ 392 BT_FH_FT_ManHoch 5;
BA_ "GenSigSendType" SG_ 392 BT_FH_FT_ManHoch 9;
BA_ "GenSigSwitchedByIgnition" SG_ 392 BT_FH_FT_ManHoch 0;
BA_ "GenSigActiveRepetitions" SG_ 392 BT_FH_FT_ManTief 5;
BA_ "GenSigSendType" SG_ 392 BT_FH_FT_ManTief 9;
BA_ "GenSigSwitchedByIgnition" SG_ 392 BT_FH_FT_ManTief 0;
BA_ "GenSigActiveRepetitions" SG_ 392 BT_FH_HBFS_AutoHoch 5;
BA_ "GenSigSendType" SG_ 392 BT_FH_HBFS_AutoHoch 9;
BA_ "GenSigSwitchedByIgnition" SG_ 392 BT_FH_HBFS_AutoHoch 0;
BA_ "GenSigActiveRepetitions" SG_ 392 BT_FH_HBFS_AutoTief 5;
BA_ "GenSigSendType" SG_ 392 BT_FH_HBFS_AutoTief 9;
BA_ "GenSigSwitchedByIgnition" SG_ 392 BT_FH_HBFS_AutoTief 0;
BA_ "GenSigActiveRepetitions" SG_ 392 BT_FH_HBFS_ManHoch 5;
BA_ "GenSigSendType" SG_ 392 BT_FH_HBFS_ManHoch 9;
BA_ "GenSigSwitchedByIgnition" SG_ 392 BT_FH_HBFS_ManHoch 0;
BA_ "GenSigActiveRepetitions" SG_ 392 BT_FH_HBFS_ManTief 5;
BA_ "GenSigSendType" SG_ 392 BT_FH_HBFS_ManTief 9;
BA_ "GenSigSwitchedByIgnition" SG_ 392 BT_FH_HBFS_ManTief 0;
BA_ "GenSigActiveRepetitions" SG_ 392 BT_FH_HFS_AutoHoch 5;
BA_ "GenSigSendType" SG_ 392 BT_FH_HFS_AutoHoch 9;
BA_ "GenSigSwitchedByIgnition" SG_ 392 BT_FH_HFS_AutoHoch 0;
BA_ "GenSigActiveRepetitions" SG_ 392 BT_FH_HFS_AutoTief 5;
BA_ "GenSigSendType" SG_ 392 BT_FH_HFS_AutoTief 9;
BA_ "GenSigSwitchedByIgnition" SG_ 392 BT_FH_HFS_AutoTief 0;
BA_ "GenSigActiveRepetitions" SG_ 392 BT_FH_HFS_ManHoch 5;
BA_ "GenSigSendType" SG_ 392 BT_FH_HFS_ManHoch 9;
BA_ "GenSigSwitchedByIgnition" SG_ 392 BT_FH_HFS_ManHoch 0;
BA_ "GenSigActiveRepetitions" SG_ 392 BT_FH_HFS_ManTief 5;
BA_ "GenSigSendType" SG_ 392 BT_FH_HFS_ManTief 9;
BA_ "GenSigSwitchedByIgnition" SG_ 392 BT_FH_HFS_ManTief 0;
BA_ "GenSigActiveRepetitions" SG_ 392 BT_FH_zentral_auf 5;
BA_ "GenSigSendType" SG_ 392 BT_FH_zentral_auf 9;
BA_ "GenSigSwitchedByIgnition" SG_ 392 BT_FH_zentral_auf 0;
BA_ "GenSigActiveRepetitions" SG_ 392 BT_FH_zentral_zu 5;
BA_ "GenSigSendType" SG_ 392 BT_FH_zentral_zu 9;
BA_ "GenSigSwitchedByIgnition" SG_ 392 BT_FH_zentral_zu 0;
BA_ "GenSigActiveRepetitions" SG_ 392 BT_SP_Fahrstellung 5;
BA_ "GenSigSendType" SG_ 392 BT_SP_Fahrstellung 4;
BA_ "GenSigSwitchedByIgnition" SG_ 392 BT_SP_Fahrstellung 0;
BA_ "GenSigActiveRepetitions" SG_ 392 BT_SP_Garagenstellung 5;
BA_ "GenSigSendType" SG_ 392 BT_SP_Garagenstellung 4;
BA_ "GenSigSwitchedByIgnition" SG_ 392 BT_SP_Garagenstellung 0;
BA_ "GenSigActiveRepetitions" SG_ 392 BT_SP_hoch 5;
BA_ "GenSigSendType" SG_ 392 BT_SP_hoch 9;
BA_ "GenSigSwitchedByIgnition" SG_ 392 BT_SP_hoch 0;
BA_ "GenSigActiveRepetitions" SG_ 392 BT_SP_links 5;
BA_ "GenSigSendType" SG_ 392 BT_SP_links 9;
BA_ "GenSigSwitchedByIgnition" SG_ 392 BT_SP_links 0;
BA_ "GenSigActiveRepetitions" SG_ 392 BT_SP_rechts 5;
BA_ "GenSigSendType" SG_ 392 BT_SP_rechts 9;
BA_ "GenSigSwitchedByIgnition" SG_ 392 BT_SP_rechts 0;
BA_ "GenSigActiveRepetitions" SG_ 392 BT_SP_tief 5;
BA_ "GenSigSendType" SG_ 392 BT_SP_tief 9;
BA_ "GenSigSwitchedByIgnition" SG_ 392 BT_SP_tief 0;
BA_ "GenSigSendType" SG_ 388 BCM_BF_Spg_Absenkung 0;
BA_ "GenSigSwitchedByIgnition" SG_ 388 BCM_BF_Spg_Absenkung 0;
BA_ "GenSigSendType" SG_ 388 BCM_Spg_Synchron 0;
BA_ "GenSigSwitchedByIgnition" SG_ 388 BCM_Spg_Synchron 0;
BA_ "GenSigActiveRepetitions" SG_ 388 FH_BT_hoch 11;
BA_ "GenSigSendType" SG_ 388 FH_BT_hoch 6;
BA_ "GenSigSwitchedByIgnition" SG_ 388 FH_BT_hoch 0;
BA_ "GenSigActiveRepetitions" SG_ 388 FH_BT_tief 11;
BA_ "GenSigSendType" SG_ 388 FH_BT_tief 6;
BA_ "GenSigSwitchedByIgnition" SG_ 388 FH_BT_tief 0;
BA_ "GenSigActiveRepetitions" SG_ 388 FH_FT_hoch 11;
BA_ "GenSigSendType" SG_ 388 FH_FT_hoch 6;
BA_ "GenSigSwitchedByIgnition" SG_ 388 FH_FT_hoch 0;
BA_ "GenSigActiveRepetitions" SG_ 388 FH_FT_tief 11;
BA_ "GenSigSendType" SG_ 388 FH_FT_tief 6;
BA_ "GenSigSwitchedByIgnition" SG_ 388 FH_FT_tief 0;
BA_ "GenSigActiveRepetitions" SG_ 388 FH_HBFS_hoch 11;
BA_ "GenSigSendType" SG_ 388 FH_HBFS_hoch 6;
BA_ "GenSigSwitchedByIgnition" SG_ 388 FH_HBFS_hoch 0;
BA_ "GenSigActiveRepetitions" SG_ 388 FH_HBFS_tief 11;
BA_ "GenSigSendType" SG_ 388 FH_HBFS_tief 6;
BA_ "GenSigSwitchedByIgnition" SG_ 388 FH_HBFS_tief 0;
BA_ "GenSigActiveRepetitions" SG_ 388 FH_HFS_hoch 11;
BA_ "GenSigSendType" SG_ 388 FH_HFS_hoch 6;
BA_ "GenSigSwitchedByIgnition" SG_ 388 FH_HFS_hoch 0;
BA_ "GenSigActiveRepetitions" SG_ 388 FH_HFS_tief 11;
BA_ "GenSigSendType" SG_ 388 FH_HFS_tief 6;
BA_ "GenSigSwitchedByIgnition" SG_ 388 FH_HFS_tief 0;
BA_ "GenSigSendType" SG_ 388 VIP_Freigabe 0;
BA_ "GenSigSwitchedByIgnition" SG_ 388 VIP_Freigabe 0;
BA_ "GenSigActiveRepetitions" SG_ 388 VIP_Sensor_betaetigt 11;
BA_ "GenSigSendType" SG_ 388 VIP_Sensor_betaetigt 6;
BA_ "GenSigSwitchedByIgnition" SG_ 388 VIP_Sensor_betaetigt 0;
BA_ "GenSigSendType" SG_ 388 ZV_01_BZ 0;
BA_ "GenSigFuncType" SG_ 388 ZV_01_BZ 1;
BA_ "GenSigSendType" SG_ 388 ZV_01_CRC 0;
BA_ "GenSigFuncType" SG_ 388 ZV_01_CRC 2;
BA_ "GenSigActiveRepetitions" SG_ 388 ZV_auf_BT 11;
BA_ "GenSigSendType" SG_ 388 ZV_auf_BT 6;
BA_ "GenSigSwitchedByIgnition" SG_ 388 ZV_auf_BT 0;
BA_ "GenSigActiveRepetitions" SG_ 388 ZV_auf_FT 11;
BA_ "GenSigSendType" SG_ 388 ZV_auf_FT 6;
BA_ "GenSigSwitchedByIgnition" SG_ 388 ZV_auf_FT 0;
BA_ "GenSigActiveRepetitions" SG_ 388 ZV_auf_Funk 11;
BA_ "GenSigSendType" SG_ 388 ZV_auf_Funk 6;
BA_ "GenSigSwitchedByIgnition" SG_ 388 ZV_auf_Funk 0;
BA_ "GenSigActiveRepetitions" SG_ 388 ZV_auf_Kessy 11;
BA_ "GenSigSendType" SG_ 388 ZV_auf_Kessy 6;
BA_ "GenSigSwitchedByIgnition" SG_ 388 ZV_auf_Kessy 0;
BA_ "GenSigActiveRepetitions" SG_ 388 ZV_auto_Ansteuerung 11;
BA_ "GenSigSendType" SG_ 388 ZV_auto_Ansteuerung 6;
BA_ "GenSigSwitchedByIgnition" SG_ 388 ZV_auto_Ansteuerung 0;
BA_ "GenSigActiveRepetitions" SG_ 388 ZV_BT_entriegeln 11;
BA_ "GenSigSendType" SG_ 388 ZV_BT_entriegeln 6;
BA_ "GenSigSwitchedByIgnition" SG_ 388 ZV_BT_entriegeln 0;
BA_ "GenSigActiveRepetitions" SG_ 388 ZV_BT_verriegeln 11;
BA_ "GenSigSendType" SG_ 388 ZV_BT_verriegeln 6;
BA_ "GenSigSwitchedByIgnition" SG_ 388 ZV_BT_verriegeln 0;
BA_ "GenSigActiveRepetitions" SG_ 388 ZV_entriegeln_Anf 11;
BA_ "GenSigSendType" SG_ 388 ZV_entriegeln_Anf 6;
BA_ "GenSigSwitchedByIgnition" SG_ 388 ZV_entriegeln_Anf 0;
BA_ "GenSigActiveRepetitions" SG_ 388 ZV_FT_entriegeln 11;
BA_ "GenSigSendType" SG_ 388 ZV_FT_entriegeln 6;
BA_ "GenSigSwitchedByIgnition" SG_ 388 ZV_FT_entriegeln 0;
BA_ "GenSigActiveRepetitions" SG_ 388 ZV_FT_verriegeln 11;
BA_ "GenSigSendType" SG_ 388 ZV_FT_verriegeln 6;
BA_ "GenSigSwitchedByIgnition" SG_ 388 ZV_FT_verriegeln 0;
BA_ "GenSigActiveRepetitions" SG_ 388 ZV_HBFS_entriegeln 11;
BA_ "GenSigSendType" SG_ 388 ZV_HBFS_entriegeln 6;
BA_ "GenSigSwitchedByIgnition" SG_ 388 ZV_HBFS_entriegeln 0;
BA_ "GenSigActiveRepetitions" SG_ 388 ZV_HBFS_verriegeln 11;
BA_ "GenSigSendType" SG_ 388 ZV_HBFS_verriegeln 6;
BA_ "GenSigSwitchedByIgnition" SG_ 388 ZV_HBFS_verriegeln 0;
BA_ "GenSigActiveRepetitions" SG_ 388 ZV_HFS_entriegeln 11;
BA_ "GenSigSendType" SG_ 388 ZV_HFS_entriegeln 6;
BA_ "GenSigSwitchedByIgnition" SG_ 388 ZV_HFS_entriegeln 0;
BA_ "GenSigActiveRepetitions" SG_ 388 ZV_HFS_verriegeln 11;
BA_ "GenSigSendType" SG_ 388 ZV_HFS_verriegeln 6;
BA_ "GenSigSwitchedByIgnition" SG_ 388 ZV_HFS_verriegeln 0;
BA_ "GenSigActiveRepetitions" SG_ 388 ZV_HSK_entriegeln 11;
BA_ "GenSigSendType" SG_ 388 ZV_HSK_entriegeln 6;
BA_ "GenSigSwitchedByIgnition" SG_ 388 ZV_HSK_entriegeln 0;
BA_ "GenSigActiveRepetitions" SG_ 388 ZV_HSK_verriegeln 11;
BA_ "GenSigSendType" SG_ 388 ZV_HSK_verriegeln 6;
BA_ "GenSigSwitchedByIgnition" SG_ 388 ZV_HSK_verriegeln 0;
BA_ "GenSigActiveRepetitions" SG_ 388 ZV_LED_Steuerung 11;
BA_ "GenSigSendType" SG_ 388 ZV_LED_Steuerung 6;
BA_ "GenSigSwitchedByIgnition" SG_ 388 ZV_LED_Steuerung 0;
BA_ "GenSigActiveRepetitions" SG_ 388 ZV_LED_Uebernahme 11;
BA_ "GenSigSendType" SG_ 388 ZV_LED_Uebernahme 6;
BA_ "GenSigSwitchedByIgnition" SG_ 388 ZV_LED_Uebernahme 0;
BA_ "GenSigActiveRepetitions" SG_ 388 ZV_Signatur 11;
BA_ "GenSigSendType" SG_ 388 ZV_Signatur 6;
BA_ "GenSigSwitchedByIgnition" SG_ 388 ZV_Signatur 0;
BA_ "GenSigActiveRepetitions" SG_ 388 ZV_Softtouch_betaetigt 11;
BA_ "GenSigSendType" SG_ 388 ZV_Softtouch_betaetigt 6;
BA_ "GenSigSwitchedByIgnition" SG_ 388 ZV_Softtouch_betaetigt 0;
BA_ "GenSigActiveRepetitions" SG_ 388 ZV_Spg_Anklappen 11;
BA_ "GenSigSendType" SG_ 388 ZV_Spg_Anklappen 6;
BA_ "GenSigSwitchedByIgnition" SG_ 388 ZV_Spg_Anklappen 0;
BA_ "GenSigActiveRepetitions" SG_ 388 ZV_Verdeck_auf 11;
BA_ "GenSigSendType" SG_ 388 ZV_Verdeck_auf 6;
BA_ "GenSigSwitchedByIgnition" SG_ 388 ZV_Verdeck_auf 0;
BA_ "GenSigActiveRepetitions" SG_ 388 ZV_Verdeck_zu 11;
BA_ "GenSigSendType" SG_ 388 ZV_Verdeck_zu 6;
BA_ "GenSigSwitchedByIgnition" SG_ 388 ZV_Verdeck_zu 0;
BA_ "GenSigActiveRepetitions" SG_ 388 ZV_zentral_entsafen 11;
BA_ "GenSigSendType" SG_ 388 ZV_zentral_entsafen 6;
BA_ "GenSigSwitchedByIgnition" SG_ 388 ZV_zentral_entsafen 0;
BA_ "GenSigActiveRepetitions" SG_ 388 ZV_zentral_safen 11;
BA_ "GenSigSendType" SG_ 388 ZV_zentral_safen 6;
BA_ "GenSigSwitchedByIgnition" SG_ 388 ZV_zentral_safen 0;
BA_ "GenSigActiveRepetitions" SG_ 388 ZV_zu_BT 11;
BA_ "GenSigSendType" SG_ 388 ZV_zu_BT 6;
BA_ "GenSigSwitchedByIgnition" SG_ 388 ZV_zu_BT 0;
BA_ "GenSigActiveRepetitions" SG_ 388 ZV_zu_FT 11;
BA_ "GenSigSendType" SG_ 388 ZV_zu_FT 6;
BA_ "GenSigSwitchedByIgnition" SG_ 388 ZV_zu_FT 0;
BA_ "GenSigActiveRepetitions" SG_ 388 ZV_zu_Funk 11;
BA_ "GenSigSendType" SG_ 388 ZV_zu_Funk 6;
BA_ "GenSigSwitchedByIgnition" SG_ 388 ZV_zu_Funk 0;
BA_ "GenSigActiveRepetitions" SG_ 388 ZV_zu_Kessy 11;
BA_ "GenSigSendType" SG_ 388 ZV_zu_Kessy 6;
BA_ "GenSigSwitchedByIgnition" SG_ 388 ZV_zu_Kessy 0;
BA_ "GenSigActiveRepetitions" SG_ 388 ZV_zu_Zeitl_Nachverr 11;
BA_ "GenSigSendType" SG_ 388 ZV_zu_Zeitl_Nachverr 6;
BA_ "GenSigSwitchedByIgnition" SG_ 388 ZV_zu_Zeitl_Nachverr 0;
BA_ "GenSigSendType" SG_ 1411 BCM_FH_Freigabe 3;
BA_ "GenSigSwitchedByIgnition" SG_ 1411 BCM_FH_Freigabe 0;
BA_ "GenSigSendType" SG_ 1411 BCM_HSK_Freigabe 3;
BA_ "GenSigSwitchedByIgnition" SG_ 1411 BCM_HSK_Freigabe 0;
BA_ "GenSigSendType" SG_ 1411 BCM_Komfortfkt_Freigabe 3;
BA_ "GenSigSwitchedByIgnition" SG_ 1411 BCM_Komfortfkt_Freigabe 0;
BA_ "GenSigSendType" SG_ 1411 BCM_Tankklappensteller_Fehler 0;
BA_ "GenSigSwitchedByIgnition" SG_ 1411 BCM_Tankklappensteller_Fehler 0;
BA_ "Fehlerwert" SG_ 1411 BCM_Tankklappensteller_Fehler 1;
BA_ "GenSigSendType" SG_ 1411 BCM_Verdeck_Freigabe 3;
BA_ "GenSigSwitchedByIgnition" SG_ 1411 BCM_Verdeck_Freigabe 0;
BA_ "GenSigSendType" SG_ 1411 DWA_aktiv 3;
BA_ "GenSigSwitchedByIgnition" SG_ 1411 DWA_aktiv 0;
BA_ "GenSigSendType" SG_ 1411 FBS_Warn_Schluessel_Batt 3;
BA_ "GenSigSwitchedByIgnition" SG_ 1411 FBS_Warn_Schluessel_Batt 0;
BA_ "GenSigActiveRepetitions" SG_ 1411 FFB_CarFinder 5;
BA_ "GenSigSendType" SG_ 1411 FFB_CarFinder 2;
BA_ "GenSigSwitchedByIgnition" SG_ 1411 FFB_CarFinder 0;
BA_ "GenSigActiveRepetitions" SG_ 1411 FFB_Komfortoeffnen 5;
BA_ "GenSigSendType" SG_ 1411 FFB_Komfortoeffnen 2;
BA_ "GenSigSwitchedByIgnition" SG_ 1411 FFB_Komfortoeffnen 0;
BA_ "GenSigActiveRepetitions" SG_ 1411 FFB_Komfortschliessen 5;
BA_ "GenSigSendType" SG_ 1411 FFB_Komfortschliessen 2;
BA_ "GenSigSwitchedByIgnition" SG_ 1411 FFB_Komfortschliessen 0;
BA_ "GenSigSendType" SG_ 1411 HBFS_gesafet 3;
BA_ "GenSigSwitchedByIgnition" SG_ 1411 HBFS_gesafet 0;
BA_ "GenSigSendType" SG_ 1411 HBFS_verriegelt 3;
BA_ "GenSigSwitchedByIgnition" SG_ 1411 HBFS_verriegelt 0;
BA_ "GenSigSendType" SG_ 1411 HD_Hauptraste 3;
BA_ "GenSigSwitchedByIgnition" SG_ 1411 HD_Hauptraste 0;
BA_ "GenSigSendType" SG_ 1411 HD_Vorraste 3;
BA_ "GenSigSwitchedByIgnition" SG_ 1411 HD_Vorraste 0;
BA_ "GenSigSendType" SG_ 1411 HFS_gesafet 3;
BA_ "GenSigSwitchedByIgnition" SG_ 1411 HFS_gesafet 0;
BA_ "GenSigSendType" SG_ 1411 HFS_verriegelt 3;
BA_ "GenSigSwitchedByIgnition" SG_ 1411 HFS_verriegelt 0;
BA_ "GenSigSendType" SG_ 1411 IRUE_aktiv 3;
BA_ "GenSigSwitchedByIgnition" SG_ 1411 IRUE_aktiv 0;
BA_ "GenSigSendType" SG_ 1411 IRUE_Taster_Fkts_LED 3;
BA_ "GenSigSwitchedByIgnition" SG_ 1411 IRUE_Taster_Fkts_LED 0;
BA_ "GenSigSendType" SG_ 1411 ZV_BT_offen 3;
BA_ "GenSigSwitchedByIgnition" SG_ 1411 ZV_BT_offen 0;
BA_ "GenSigSendType" SG_ 1411 ZV_Einzeltuerentriegelung 3;
BA_ "GenSigSwitchedByIgnition" SG_ 1411 ZV_Einzeltuerentriegelung 0;
BA_ "GenSigSendType" SG_ 1411 ZV_FT_offen 3;
BA_ "GenSigSwitchedByIgnition" SG_ 1411 ZV_FT_offen 0;
BA_ "GenSigSendType" SG_ 1411 ZV_gesafet_extern_ist 3;
BA_ "GenSigSwitchedByIgnition" SG_ 1411 ZV_gesafet_extern_ist 0;
BA_ "GenSigSendType" SG_ 1411 ZV_gesafet_extern_soll 3;
BA_ "GenSigSwitchedByIgnition" SG_ 1411 ZV_gesafet_extern_soll 0;
BA_ "GenSigSendType" SG_ 1411 ZV_HBFS_offen 3;
BA_ "GenSigSwitchedByIgnition" SG_ 1411 ZV_HBFS_offen 0;
BA_ "GenSigSendType" SG_ 1411 ZV_HD_offen 3;
BA_ "GenSigSwitchedByIgnition" SG_ 1411 ZV_HD_offen 0;
BA_ "GenSigSendType" SG_ 1411 ZV_Heckeinzelentriegelung 3;
BA_ "GenSigSwitchedByIgnition" SG_ 1411 ZV_Heckeinzelentriegelung 0;
BA_ "GenSigSendType" SG_ 1411 ZV_HFS_offen 3;
BA_ "GenSigSwitchedByIgnition" SG_ 1411 ZV_HFS_offen 0;
BA_ "GenSigSendType" SG_ 1411 ZV_HS_offen 3;
BA_ "GenSigSwitchedByIgnition" SG_ 1411 ZV_HS_offen 0;
BA_ "GenSigSendType" SG_ 1411 ZV_ist_Zustand_verfuegbar 3;
BA_ "GenSigSwitchedByIgnition" SG_ 1411 ZV_ist_Zustand_verfuegbar 0;
BA_ "GenSigSendType" SG_ 1411 ZV_Oeffnungsmodus 3;
BA_ "GenSigSwitchedByIgnition" SG_ 1411 ZV_Oeffnungsmodus 0;
BA_ "GenSigSendType" SG_ 1411 ZV_Rollo_auf 3;
BA_ "GenSigSwitchedByIgnition" SG_ 1411 ZV_Rollo_auf 0;
BA_ "GenSigSendType" SG_ 1411 ZV_Rollo_zu 3;
BA_ "GenSigSwitchedByIgnition" SG_ 1411 ZV_Rollo_zu 0;
BA_ "GenSigSendType" SG_ 1411 ZV_SAD_auf 3;
BA_ "GenSigSwitchedByIgnition" SG_ 1411 ZV_SAD_auf 0;
BA_ "GenSigSendType" SG_ 1411 ZV_SAD_zu 3;
BA_ "GenSigSwitchedByIgnition" SG_ 1411 ZV_SAD_zu 0;
BA_ "GenSigSendType" SG_ 1411 ZV_SafeFunktion_aktiv 3;
BA_ "GenSigSwitchedByIgnition" SG_ 1411 ZV_SafeFunktion_aktiv 0;
BA_ "GenSigActiveRepetitions" SG_ 1411 ZV_Schluessel_Zugang 5;
BA_ "GenSigSendType" SG_ 1411 ZV_Schluessel_Zugang 4;
BA_ "GenSigSwitchedByIgnition" SG_ 1411 ZV_Schluessel_Zugang 0;
BA_ "GenSigSendType" SG_ 1411 ZV_Tankklappe_offen 0;
BA_ "GenSigSwitchedByIgnition" SG_ 1411 ZV_Tankklappe_offen 0;
BA_ "GenSigSendType" SG_ 1411 ZV_verriegelt_extern_ist 3;
BA_ "GenSigSwitchedByIgnition" SG_ 1411 ZV_verriegelt_extern_ist 0;
BA_ "GenSigSendType" SG_ 1411 ZV_verriegelt_extern_soll 3;
BA_ "GenSigSwitchedByIgnition" SG_ 1411 ZV_verriegelt_extern_soll 0;
BA_ "GenSigSendType" SG_ 1411 ZV_verriegelt_intern_ist 3;
BA_ "GenSigSwitchedByIgnition" SG_ 1411 ZV_verriegelt_intern_ist 0;
BA_ "GenSigSendType" SG_ 1411 ZV_verriegelt_intern_soll 3;
BA_ "GenSigSwitchedByIgnition" SG_ 1411 ZV_verriegelt_intern_soll 0;
BA_ "GenSigSendType" SG_ 1411 ZV_verriegelt_soll 3;
BA_ "GenSigSwitchedByIgnition" SG_ 1411 ZV_verriegelt_soll 0;
BA_ "GenSigActiveRepetitions" SG_ 711 BCM2_ZV_Tasten_HMI_Anf 11;
BA_ "GenSigSendType" SG_ 711 BCM2_ZV_Tasten_HMI_Anf 6;
BA_ "GenSigSwitchedByIgnition" SG_ 711 BCM2_ZV_Tasten_HMI_Anf 0;
BA_ "GenSigActiveRepetitions" SG_ 711 BCM_Spg_Heizen_Trigger 11;
BA_ "GenSigSendType" SG_ 711 BCM_Spg_Heizen_Trigger 6;
BA_ "GenSigSwitchedByIgnition" SG_ 711 BCM_Spg_Heizen_Trigger 0;
BA_ "GenSigActiveRepetitions" SG_ 711 ZV_FD_Taste_auf 11;
BA_ "GenSigSendType" SG_ 711 ZV_FD_Taste_auf 6;
BA_ "GenSigSwitchedByIgnition" SG_ 711 ZV_FD_Taste_auf 0;
BA_ "GenSigActiveRepetitions" SG_ 711 ZV_HD_Taste_auf 11;
BA_ "GenSigSendType" SG_ 711 ZV_HD_Taste_auf 6;
BA_ "GenSigSwitchedByIgnition" SG_ 711 ZV_HD_Taste_auf 0;
BA_ "GenSigActiveRepetitions" SG_ 711 ZV_HD_Taste_zu 11;
BA_ "GenSigSendType" SG_ 711 ZV_HD_Taste_zu 6;
BA_ "GenSigSwitchedByIgnition" SG_ 711 ZV_HD_Taste_zu 0;
BA_ "GenSigActiveRepetitions" SG_ 711 ZV_TAG_verfahren 11;
BA_ "GenSigSendType" SG_ 711 ZV_TAG_verfahren 6;
BA_ "GenSigSwitchedByIgnition" SG_ 711 ZV_TAG_verfahren 0;
BA_REL_ "GenSigTimeoutTime" BU_SG_REL_ BedienDisp_vo SG_ 1411 BCM_FH_Freigabe 2000;
BA_REL_ "GenSigTimeoutTime" BU_SG_REL_ BedienSG_hi SG_ 1718 UH_Typ 5000;
BA_REL_ "GenSigTimeoutTime" BU_SG_REL_ BedienSG_hi SG_ 1718 UH_DLS 5000;
BA_REL_ "GenSigTimeoutTime" BU_SG_REL_ BedienSG_hi SG_ 1716 VIN_01_MUX 2000;
BA_REL_ "GenSigTimeoutTime" BU_SG_REL_ BedienSG_hi SG_ 1716 VIN_4 2000;
BA_REL_ "GenSigTimeoutTime" BU_SG_REL_ BedienSG_hi SG_ 1716 VIN_11 2000;
BA_REL_ "GenSigTimeoutTime" BU_SG_REL_ BedienSG_hi SG_ 1716 VIN_5 2000;
BA_REL_ "GenSigTimeoutTime" BU_SG_REL_ BedienSG_hi SG_ 1716 VIN_12 2000;
BA_REL_ "GenSigTimeoutTime" BU_SG_REL_ BedienSG_hi SG_ 1716 VIN_6 2000;
BA_REL_ "GenSigTimeoutTime" BU_SG_REL_ BedienSG_hi SG_ 1716 VIN_13 2000;
BA_REL_ "GenSigTimeoutTime" BU_SG_REL_ BedienSG_hi SG_ 1716 VIN_7 2000;
BA_REL_ "GenSigTimeoutTime" BU_SG_REL_ BedienSG_hi SG_ 1716 VIN_14 2000;
BA_REL_ "GenSigTimeoutTime" BU_SG_REL_ BedienSG_hi SG_ 1716 VIN_1 2000;
BA_REL_ "GenSigTimeoutTime" BU_SG_REL_ BedienSG_hi SG_ 1716 VIN_8 2000;
BA_REL_ "GenSigTimeoutTime" BU_SG_REL_ BedienSG_hi SG_ 1716 VIN_15 2000;
BA_REL_ "GenSigTimeoutTime" BU_SG_REL_ BedienSG_hi SG_ 1716 VIN_2 2000;
BA_REL_ "GenSigTimeoutTime" BU_SG_REL_ BedienSG_hi SG_ 1716 VIN_9 2000;
BA_REL_ "GenSigTimeoutTime" BU_SG_REL_ BedienSG_hi SG_ 1716 VIN_16 2000;
BA_REL_ "GenSigTimeoutTime" BU_SG_REL_ BedienSG_hi SG_ 1716 VIN_3 2000;
BA_REL_ "GenSigTimeoutTime" BU_SG_REL_ BedienSG_hi SG_ 1716 VIN_10 2000;
BA_REL_ "GenSigTimeoutTime" BU_SG_REL_ BedienSG_hi SG_ 1716 VIN_17 2000;
BA_REL_ "GenSigTimeoutTime" BU_SG_REL_ BedienSG_hi SG_ 711 BCM2_ZV_Tasten_HMI_Anf 5000;
BA_REL_ "GenSigTimeoutTime" BU_SG_REL_ DDA SG_ 2589283609 UGDO_Channel_1 5000;
BA_REL_ "GenSigTimeoutTime" BU_SG_REL_ DDA SG_ 2589283609 UGDO_Channel_2 5000;
BA_REL_ "GenSigTimeoutTime" BU_SG_REL_ DDA SG_ 2589283609 UGDO_Channel_3 5000;
BA_REL_ "GenSigTimeoutTime" BU_SG_REL_ DDA SG_ 2589283609 UGDO_Channel_4 5000;
BA_REL_ "GenSigTimeoutTime" BU_SG_REL_ DDA SG_ 2589283609 UGDO_Channel_5 5000;
BA_REL_ "GenSigTimeoutTime" BU_SG_REL_ DDA SG_ 2589283609 UGDO_Channel_6 5000;
BA_REL_ "GenSigTimeoutTime" BU_SG_REL_ DDA SG_ 2589283609 UGDO_Channel_7 5000;
BA_REL_ "GenSigTimeoutTime" BU_SG_REL_ DDA SG_ 2589283609 UGDO_Channel_8 5000;
BA_REL_ "GenSigTimeoutTime" BU_SG_REL_ DDA SG_ 2589283609 UGDO_Channel_9 5000;
BA_REL_ "GenSigTimeoutTime" BU_SG_REL_ DDA SG_ 2589283609 UGDO_Channel_10 5000;
BA_REL_ "GenSigTimeoutTime" BU_SG_REL_ DDA SG_ 2589283609 UGDO_Channel_11 5000;
BA_REL_ "GenSigTimeoutTime" BU_SG_REL_ DDA SG_ 2589283609 UGDO_Channel_12 5000;
BA_REL_ "GenSigTimeoutTime" BU_SG_REL_ DDA SG_ 2589283609 UGDO_Channel_13 5000;
BA_REL_ "GenSigTimeoutTime" BU_SG_REL_ DDA SG_ 2589283609 UGDO_Channel_14 5000;
BA_REL_ "GenSigTimeoutTime" BU_SG_REL_ DDA SG_ 2589283609 UGDO_Channel_15 5000;
BA_REL_ "GenSigTimeoutTime" BU_SG_REL_ DDA SG_ 2589283609 UGDO_DoorState 5000;
BA_REL_ "GenSigTimeoutTime" BU_SG_REL_ DDA SG_ 1716 VIN_01_MUX 2000;
BA_REL_ "GenSigTimeoutTime" BU_SG_REL_ DDA SG_ 1716 VIN_4 2000;
BA_REL_ "GenSigTimeoutTime" BU_SG_REL_ DDA SG_ 1716 VIN_11 2000;
BA_REL_ "GenSigTimeoutTime" BU_SG_REL_ DDA SG_ 1716 VIN_5 2000;
BA_REL_ "GenSigTimeoutTime" BU_SG_REL_ DDA SG_ 1716 VIN_12 2000;
BA_REL_ "GenSigTimeoutTime" BU_SG_REL_ DDA SG_ 1716 VIN_6 2000;
BA_REL_ "GenSigTimeoutTime" BU_SG_REL_ DDA SG_ 1716 VIN_13 2000;
BA_REL_ "GenSigTimeoutTime" BU_SG_REL_ DDA SG_ 1716 VIN_7 2000;
BA_REL_ "GenSigTimeoutTime" BU_SG_REL_ DDA SG_ 1716 VIN_14 2000;
BA_REL_ "GenSigTimeoutTime" BU_SG_REL_ DDA SG_ 1716 VIN_1 2000;
BA_REL_ "GenSigTimeoutTime" BU_SG_REL_ DDA SG_ 1716 VIN_8 2000;
BA_REL_ "GenSigTimeoutTime" BU_SG_REL_ DDA SG_ 1716 VIN_15 2000;
BA_REL_ "GenSigTimeoutTime" BU_SG_REL_ DDA SG_ 1716 VIN_2 2000;
BA_REL_ "GenSigTimeoutTime" BU_SG_REL_ DDA SG_ 1716 VIN_9 2000;
BA_REL_ "GenSigTimeoutTime" BU_SG_REL_ DDA SG_ 1716 VIN_16 2000;
BA_REL_ "GenSigTimeoutTime" BU_SG_REL_ DDA SG_ 1716 VIN_3 2000;
BA_REL_ "GenSigTimeoutTime" BU_SG_REL_ DDA SG_ 1716 VIN_10 2000;
BA_REL_ "GenSigTimeoutTime" BU_SG_REL_ DDA SG_ 1716 VIN_17 2000;
BA_REL_ "GenSigTimeoutTime" BU_SG_REL_ DDA SG_ 1411 ZV_verriegelt_intern_ist 2000;
BA_REL_ "GenSigTimeoutTime" BU_SG_REL_ DDA SG_ 1411 ZV_verriegelt_extern_ist 2000;
BA_REL_ "GenSigTimeoutTime" BU_SG_REL_ DDA SG_ 1411 ZV_FT_offen 2000;
BA_REL_ "GenSigTimeoutTime" BU_SG_REL_ DDA SG_ 1411 ZV_BT_offen 2000;
BA_REL_ "GenSigTimeoutTime" BU_SG_REL_ DDA SG_ 1411 ZV_HFS_offen 2000;
BA_REL_ "GenSigTimeoutTime" BU_SG_REL_ DDA SG_ 1411 ZV_HBFS_offen 2000;
BA_REL_ "GenSigTimeoutTime" BU_SG_REL_ DDA SG_ 1411 ZV_HD_offen 2000;
BA_REL_ "GenSigTimeoutTime" BU_SG_REL_ Gateway SG_ 2589283477 MMI_State 5000;
BA_REL_ "GenSigTimeoutTime" BU_SG_REL_ Gateway SG_ 2589283477 MU_MOST_State 5000;
BA_REL_ "GenSigTimeoutTime" BU_SG_REL_ Gateway SG_ 2589283477 MU_ActiveTime_MIBCAN 5000;
BA_REL_ "GenSigTimeoutTime" BU_SG_REL_ Gateway SG_ 2589283477 MU_ActiveTime_MOST 5000;
BA_REL_ "GenSigTimeoutTime" BU_SG_REL_ Gateway SG_ 2589283477 MU_CTR_MOST_OFF_ON 5000;
BA_REL_ "GenSigTimeoutTime" BU_SG_REL_ Gateway SG_ 2589283477 MU_CTR_Startup_MainUnit 5000;
BA_REL_ "GenSigTimeoutTime" BU_SG_REL_ Gateway SG_ 2589283477 MU_OnlineTime_MainUnit 5000;
BA_REL_ "GenSigTimeoutTime" BU_SG_REL_ Gateway SG_ 2589283477 MU_StandbyTime_MainUnit 5000;
BA_REL_ "GenSigTimeoutTime" BU_SG_REL_ Gateway SG_ 2589283477 MU_OnTime_MainUnit 5000;
BA_REL_ "GenSigTimeoutTime" BU_SG_REL_ Gateway_PAG SG_ 2589283477 MMI_State 5000;
BA_REL_ "GenSigTimeoutTime" BU_SG_REL_ Gateway_PAG SG_ 2589283477 MU_MOST_State 5000;
BA_REL_ "GenSigTimeoutTime" BU_SG_REL_ Gateway_PAG SG_ 2589283477 MU_ActiveTime_MIBCAN 5000;
BA_REL_ "GenSigTimeoutTime" BU_SG_REL_ Gateway_PAG SG_ 2589283477 MU_ActiveTime_MOST 5000;
BA_REL_ "GenSigTimeoutTime" BU_SG_REL_ Gateway_PAG SG_ 2589283477 MU_CTR_MOST_OFF_ON 5000;
BA_REL_ "GenSigTimeoutTime" BU_SG_REL_ Gateway_PAG SG_ 2589283477 MU_CTR_Startup_MainUnit 5000;
BA_REL_ "GenSigTimeoutTime" BU_SG_REL_ Gateway_PAG SG_ 2589283477 MU_OnlineTime_MainUnit 5000;
BA_REL_ "GenSigTimeoutTime" BU_SG_REL_ Gateway_PAG SG_ 2589283477 MU_StandbyTime_MainUnit 5000;
BA_REL_ "GenSigTimeoutTime" BU_SG_REL_ Gateway_PAG SG_ 2589283477 MU_OnTime_MainUnit 5000;
BA_REL_ "GenSigTimeoutTime" BU_SG_REL_ OTA_FC SG_ 995 VS_VD_entriegelt 1000;
BA_REL_ "GenSigTimeoutTime" BU_SG_REL_ OTA_FC SG_ 995 VS_VD_offen_ver 1000;
BA_REL_ "GenSigTimeoutTime" BU_SG_REL_ OTA_FC SG_ 995 VSG_Meldungen 1000;
BA_REL_ "GenSigTimeoutTime" BU_SG_REL_ OTA_FC SG_ 1716 VIN_01_MUX 2000;
BA_REL_ "GenSigTimeoutTime" BU_SG_REL_ OTA_FC SG_ 1716 KS_Geheimnis_1 2000;
BA_REL_ "GenSigTimeoutTime" BU_SG_REL_ OTA_FC SG_ 1716 VIN_4 2000;
BA_REL_ "GenSigTimeoutTime" BU_SG_REL_ OTA_FC SG_ 1716 VIN_11 2000;
BA_REL_ "GenSigTimeoutTime" BU_SG_REL_ OTA_FC SG_ 1716 KS_Geheimnis_2 2000;
BA_REL_ "GenSigTimeoutTime" BU_SG_REL_ OTA_FC SG_ 1716 VIN_5 2000;
BA_REL_ "GenSigTimeoutTime" BU_SG_REL_ OTA_FC SG_ 1716 VIN_12 2000;
BA_REL_ "GenSigTimeoutTime" BU_SG_REL_ OTA_FC SG_ 1716 KS_Geheimnis_3 2000;
BA_REL_ "GenSigTimeoutTime" BU_SG_REL_ OTA_FC SG_ 1716 VIN_6 2000;
BA_REL_ "GenSigTimeoutTime" BU_SG_REL_ OTA_FC SG_ 1716 VIN_13 2000;
BA_REL_ "GenSigTimeoutTime" BU_SG_REL_ OTA_FC SG_ 1716 KS_Geheimnis_4 2000;
BA_REL_ "GenSigTimeoutTime" BU_SG_REL_ OTA_FC SG_ 1716 VIN_7 2000;
BA_REL_ "GenSigTimeoutTime" BU_SG_REL_ OTA_FC SG_ 1716 VIN_14 2000;
BA_REL_ "GenSigTimeoutTime" BU_SG_REL_ OTA_FC SG_ 1716 VIN_1 2000;
BA_REL_ "GenSigTimeoutTime" BU_SG_REL_ OTA_FC SG_ 1716 VIN_8 2000;
BA_REL_ "GenSigTimeoutTime" BU_SG_REL_ OTA_FC SG_ 1716 VIN_15 2000;
BA_REL_ "GenSigTimeoutTime" BU_SG_REL_ OTA_FC SG_ 1716 VIN_2 2000;
BA_REL_ "GenSigTimeoutTime" BU_SG_REL_ OTA_FC SG_ 1716 VIN_9 2000;
BA_REL_ "GenSigTimeoutTime" BU_SG_REL_ OTA_FC SG_ 1716 VIN_16 2000;
BA_REL_ "GenSigTimeoutTime" BU_SG_REL_ OTA_FC SG_ 1716 VIN_3 2000;
BA_REL_ "GenSigTimeoutTime" BU_SG_REL_ OTA_FC SG_ 1716 VIN_10 2000;
BA_REL_ "GenSigTimeoutTime" BU_SG_REL_ OTA_FC SG_ 1716 VIN_17 2000;
BA_REL_ "GenSigTimeoutTime" BU_SG_REL_ OTA_FC SG_ 385 VZE_Verkehrszeichen_1 2000;
BA_REL_ "GenSigTimeoutTime" BU_SG_REL_ OTA_FC SG_ 385 VZE_Verkehrszeichen_2 2000;
BA_REL_ "GenSigTimeoutTime" BU_SG_REL_ OTA_FC SG_ 385 VZE_Verkehrszeichen_3 2000;
BA_REL_ "GenSigTimeoutTime" BU_SG_REL_ OTA_FC SG_ 668 VZE_Verkehrszeichen_4 2000;
BA_REL_ "GenSigTimeoutTime" BU_SG_REL_ OTA_FC SG_ 668 VZE_Verkehrszeichen_5 2000;
BA_REL_ "GenSigTimeoutTime" BU_SG_REL_ OTA_FC SG_ 1120 VZE_Tempowarnung_Status 2000;
BA_REL_ "GenSigTimeoutTime" BU_SG_REL_ OTA_FC SG_ 916 WBA_Segeln_aktiv 1600;
BA_REL_ "GenSigTimeoutTime" BU_SG_REL_ OTA_FC SG_ 916 WBA_GE_Texte_02 1600;
BA_REL_ "GenSigTimeoutTime" BU_SG_REL_ OTA_FC SG_ 1702 Wischer_vorne_aktiv 5000;
BA_REL_ "GenSigTimeoutTime" BU_SG_REL_ OTA_FC SG_ 1702 BCM1_SRA_aktiv 5000;
BA_REL_ "GenSigTimeoutTime" BU_SG_REL_ OTA_FC SG_ 1140 ZR_SpannungSaeule 5000;
BA_REL_ "GenSigTimeoutTime" BU_SG_REL_ OTA_FC SG_ 1140 ZR_LeistungSaeule 5000;
BA_REL_ "GenSigTimeoutTime" BU_SG_REL_ OTA_FC SG_ 1140 ZR_t_naechsteLadung 5000;
BA_REL_ "GenSigTimeoutTime" BU_SG_REL_ OTA_FC SG_ 1411 ZV_verriegelt_intern_ist 2000;
BA_REL_ "GenSigTimeoutTime" BU_SG_REL_ OTA_FC SG_ 1411 ZV_verriegelt_extern_ist 2000;
BA_REL_ "GenSigTimeoutTime" BU_SG_REL_ OTA_FC SG_ 1411 ZV_verriegelt_extern_soll 2000;
BA_REL_ "GenSigTimeoutTime" BU_SG_REL_ OTA_FC SG_ 1411 ZV_FT_offen 2000;
BA_REL_ "GenSigTimeoutTime" BU_SG_REL_ OTA_FC SG_ 1411 ZV_BT_offen 2000;
BA_REL_ "GenSigTimeoutTime" BU_SG_REL_ OTA_FC SG_ 1411 ZV_HFS_offen 2000;
BA_REL_ "GenSigTimeoutTime" BU_SG_REL_ OTA_FC SG_ 1411 ZV_HBFS_offen 2000;
BA_REL_ "GenSigTimeoutTime" BU_SG_REL_ OTA_FC SG_ 1411 ZV_HD_offen 2000;
BA_REL_ "GenSigTimeoutTime" BU_SG_REL_ OTA_FC SG_ 1411 ZV_HS_offen 2000;
BA_REL_ "GenSigTimeoutTime" BU_SG_REL_ OTA_FC SG_ 1411 HD_Hauptraste 2000;
BA_REL_ "GenSigTimeoutTime" BU_SG_REL_ OTA_FC SG_ 1411 HD_Vorraste 2000;
BA_REL_ "GenSigTimeoutTime" BU_SG_REL_ OTA_FC SG_ 1411 HFS_verriegelt 2000;
BA_REL_ "GenSigTimeoutTime" BU_SG_REL_ OTA_FC SG_ 1411 HBFS_verriegelt 2000;
BA_REL_ "GenSigTimeoutTime" BU_SG_REL_ OTA_FC SG_ 1411 ZV_ist_Zustand_verfuegbar 2000;
BA_REL_ "GenSigTimeoutTime" BU_SG_REL_ ZR_High SG_ 2589283609 UGDO_DoorState 5000;
BA_REL_ "GenSigTimeoutTime" BU_SG_REL_ ZR_High SG_ 1718 UH_Typ 5000;
BA_REL_ "GenSigTimeoutTime" BU_SG_REL_ ZR_High SG_ 1718 UH_DLS 5000;
BA_REL_ "GenSigTimeoutTime" BU_SG_REL_ ZR_High SG_ 995 VS_VD_zu_ver 1000;
BA_REL_ "GenSigTimeoutTime" BU_SG_REL_ ZR_High SG_ 995 VS_VD_offen_ver 1000;
BA_REL_ "GenSigTimeoutTime" BU_SG_REL_ ZR_High SG_ 1716 VIN_01_MUX 2000;
BA_REL_ "GenSigTimeoutTime" BU_SG_REL_ ZR_High SG_ 1716 KS_Geheimnis_1 2000;
BA_REL_ "GenSigTimeoutTime" BU_SG_REL_ ZR_High SG_ 1716 VIN_4 2000;
BA_REL_ "GenSigTimeoutTime" BU_SG_REL_ ZR_High SG_ 1716 VIN_11 2000;
BA_REL_ "GenSigTimeoutTime" BU_SG_REL_ ZR_High SG_ 1716 KS_Geheimnis_2 2000;
BA_REL_ "GenSigTimeoutTime" BU_SG_REL_ ZR_High SG_ 1716 VIN_5 2000;
BA_REL_ "GenSigTimeoutTime" BU_SG_REL_ ZR_High SG_ 1716 VIN_12 2000;
BA_REL_ "GenSigTimeoutTime" BU_SG_REL_ ZR_High SG_ 1716 KS_Geheimnis_3 2000;
BA_REL_ "GenSigTimeoutTime" BU_SG_REL_ ZR_High SG_ 1716 VIN_6 2000;
BA_REL_ "GenSigTimeoutTime" BU_SG_REL_ ZR_High SG_ 1716 VIN_13 2000;
BA_REL_ "GenSigTimeoutTime" BU_SG_REL_ ZR_High SG_ 1716 KS_Geheimnis_4 2000;
BA_REL_ "GenSigTimeoutTime" BU_SG_REL_ ZR_High SG_ 1716 VIN_7 2000;
BA_REL_ "GenSigTimeoutTime" BU_SG_REL_ ZR_High SG_ 1716 VIN_14 2000;
BA_REL_ "GenSigTimeoutTime" BU_SG_REL_ ZR_High SG_ 1716 VIN_1 2000;
BA_REL_ "GenSigTimeoutTime" BU_SG_REL_ ZR_High SG_ 1716 VIN_8 2000;
BA_REL_ "GenSigTimeoutTime" BU_SG_REL_ ZR_High SG_ 1716 VIN_15 2000;
BA_REL_ "GenSigTimeoutTime" BU_SG_REL_ ZR_High SG_ 1716 VIN_2 2000;
BA_REL_ "GenSigTimeoutTime" BU_SG_REL_ ZR_High SG_ 1716 VIN_9 2000;
BA_REL_ "GenSigTimeoutTime" BU_SG_REL_ ZR_High SG_ 1716 VIN_16 2000;
BA_REL_ "GenSigTimeoutTime" BU_SG_REL_ ZR_High SG_ 1716 VIN_3 2000;
BA_REL_ "GenSigTimeoutTime" BU_SG_REL_ ZR_High SG_ 1716 VIN_10 2000;
BA_REL_ "GenSigTimeoutTime" BU_SG_REL_ ZR_High SG_ 1716 VIN_17 2000;
BA_REL_ "GenSigTimeoutTime" BU_SG_REL_ ZR_High SG_ 385 VZE_Anzeigemodus 2000;
BA_REL_ "GenSigTimeoutTime" BU_SG_REL_ ZR_High SG_ 385 VZE_Hinweistext 2000;
BA_REL_ "GenSigTimeoutTime" BU_SG_REL_ ZR_High SG_ 385 VZE_Verkehrszeichen_Einheit 2000;
BA_REL_ "GenSigTimeoutTime" BU_SG_REL_ ZR_High SG_ 385 VZE_Verkehrszeichen_1 2000;
BA_REL_ "GenSigTimeoutTime" BU_SG_REL_ ZR_High SG_ 385 VZE_Verkehrszeichen_2 2000;
BA_REL_ "GenSigTimeoutTime" BU_SG_REL_ ZR_High SG_ 385 VZE_Verkehrszeichen_3 2000;
BA_REL_ "GenSigTimeoutTime" BU_SG_REL_ ZR_High SG_ 385 VZE_Warnung_Verkehrszeichen_1 2000;
BA_REL_ "GenSigTimeoutTime" BU_SG_REL_ ZR_High SG_ 385 VZE_Warnung_Verkehrszeichen_2 2000;
BA_REL_ "GenSigTimeoutTime" BU_SG_REL_ ZR_High SG_ 385 VZE_Warnung_Verkehrszeichen_3 2000;
BA_REL_ "GenSigTimeoutTime" BU_SG_REL_ ZR_High SG_ 385 VZE_Zusatzschild_1 2000;
BA_REL_ "GenSigTimeoutTime" BU_SG_REL_ ZR_High SG_ 385 VZE_Zusatzschild_2 2000;
BA_REL_ "GenSigTimeoutTime" BU_SG_REL_ ZR_High SG_ 385 VZE_Zusatzschild_3 2000;
BA_REL_ "GenSigTimeoutTime" BU_SG_REL_ ZR_High SG_ 385 VZE_Zeichen_01_KameraWied 2000;
BA_REL_ "GenSigTimeoutTime" BU_SG_REL_ ZR_High SG_ 385 VZE_Zeichen_02_KameraWied 2000;
BA_REL_ "GenSigTimeoutTime" BU_SG_REL_ ZR_High SG_ 385 VZE_Zeichen_03_KameraWied 2000;
BA_REL_ "GenSigTimeoutTime" BU_SG_REL_ ZR_High SG_ 385 VZE_Zeichen_01_Kamera 2000;
BA_REL_ "GenSigTimeoutTime" BU_SG_REL_ ZR_High SG_ 385 VZE_Zeichen_01_Karte 2000;
BA_REL_ "GenSigTimeoutTime" BU_SG_REL_ ZR_High SG_ 385 VZE_Zeichen_01_Gesetz 2000;
BA_REL_ "GenSigTimeoutTime" BU_SG_REL_ ZR_High SG_ 385 VZE_Zeichen_02_Kamera 2000;
BA_REL_ "GenSigTimeoutTime" BU_SG_REL_ ZR_High SG_ 385 VZE_Zeichen_02_Karte 2000;
BA_REL_ "GenSigTimeoutTime" BU_SG_REL_ ZR_High SG_ 385 VZE_Zeichen_02_Gesetz 2000;
BA_REL_ "GenSigTimeoutTime" BU_SG_REL_ ZR_High SG_ 385 VZE_Zeichen_03_Kamera 2000;
BA_REL_ "GenSigTimeoutTime" BU_SG_REL_ ZR_High SG_ 385 VZE_Zeichen_03_Karte 2000;
BA_REL_ "GenSigTimeoutTime" BU_SG_REL_ ZR_High SG_ 385 VZE_Zeichen_03_Gesetz 2000;
BA_REL_ "GenSigTimeoutTime" BU_SG_REL_ ZR_High SG_ 385 VZE_Gong 2000;
BA_REL_ "GenSigTimeoutTime" BU_SG_REL_ ZR_High SG_ 668 VZE_Zeichen_05_KameraWied 2000;
BA_REL_ "GenSigTimeoutTime" BU_SG_REL_ ZR_High SG_ 668 VZE_Zeichen_05_Kamera 2000;
BA_REL_ "GenSigTimeoutTime" BU_SG_REL_ ZR_High SG_ 668 VZE_Verkehrszeichen_4 2000;
BA_REL_ "GenSigTimeoutTime" BU_SG_REL_ ZR_High SG_ 668 VZE_Verkehrszeichen_5 2000;
BA_REL_ "GenSigTimeoutTime" BU_SG_REL_ ZR_High SG_ 668 VZE_Anhaenger_Vmax 2000;
BA_REL_ "GenSigTimeoutTime" BU_SG_REL_ ZR_High SG_ 668 VZE_Zeichen_04_Gesetz 2000;
BA_REL_ "GenSigTimeoutTime" BU_SG_REL_ ZR_High SG_ 668 VZE_Zeichen_04_Kamera 2000;
BA_REL_ "GenSigTimeoutTime" BU_SG_REL_ ZR_High SG_ 668 VZE_Zeichen_04_KameraWied 2000;
BA_REL_ "GenSigTimeoutTime" BU_SG_REL_ ZR_High SG_ 668 VZE_Zeichen_04_Karte 2000;
BA_REL_ "GenSigTimeoutTime" BU_SG_REL_ ZR_High SG_ 668 VZE_Warnung_Verkehrszeichen_4 2000;
BA_REL_ "GenSigTimeoutTime" BU_SG_REL_ ZR_High SG_ 668 VZE_Warnung_Verkehrszeichen_5 2000;
BA_REL_ "GenSigTimeoutTime" BU_SG_REL_ ZR_High SG_ 668 VZE_Zeichen_05_Gesetz 2000;
BA_REL_ "GenSigTimeoutTime" BU_SG_REL_ ZR_High SG_ 668 VZE_Zusatzschild_4 2000;
BA_REL_ "GenSigTimeoutTime" BU_SG_REL_ ZR_High SG_ 668 VZE_Zusatzschild_5 2000;
BA_REL_ "GenSigTimeoutTime" BU_SG_REL_ ZR_High SG_ 668 VZE_Baustelle 2000;
BA_REL_ "GenSigTimeoutTime" BU_SG_REL_ ZR_High SG_ 668 VZE_Zeichen_05_Karte 2000;
BA_REL_ "GenSigTimeoutTime" BU_SG_REL_ ZR_High SG_ 668 VZE_Zeichen_05_Entfernung 2000;
BA_REL_ "GenSigTimeoutTime" BU_SG_REL_ ZR_High SG_ 668 VZE_Zeichen_05_Entfernung_StdA 2000;
BA_REL_ "GenSigTimeoutTime" BU_SG_REL_ ZR_High SG_ 1120 VZE_Verkehrszeichen_6 2000;
BA_REL_ "GenSigTimeoutTime" BU_SG_REL_ ZR_High SG_ 1120 VZE_Zusatzschild_6 2000;
BA_REL_ "GenSigTimeoutTime" BU_SG_REL_ ZR_High SG_ 1120 VZE_Zeichen_06_Entfernung 2000;
BA_REL_ "GenSigTimeoutTime" BU_SG_REL_ ZR_High SG_ 1120 VZE_Zeichen_06_Entfernung_StdA 2000;
BA_REL_ "GenSigTimeoutTime" BU_SG_REL_ ZR_High SG_ 1120 VZE_Umweltinfo_Naesse 2000;
BA_REL_ "GenSigTimeoutTime" BU_SG_REL_ ZR_High SG_ 1120 VZE_Umweltinfo_Nebel 2000;
BA_REL_ "GenSigTimeoutTime" BU_SG_REL_ ZR_High SG_ 1120 VZE_Umweltinfo_Anhaengerbetrieb 2000;
BA_REL_ "GenSigTimeoutTime" BU_SG_REL_ ZR_High SG_ 1120 VZE_Erweiterte_Information 2000;
BA_REL_ "GenSigTimeoutTime" BU_SG_REL_ ZR_High SG_ 916 WBA_Fahrstufe_02 1600;
BA_REL_ "GenSigTimeoutTime" BU_SG_REL_ ZR_High SG_ 916 WBA_eing_Gang_02 1600;
BA_REL_ "GenSigTimeoutTime" BU_SG_REL_ ZR_High SG_ 916 WBA_Segeln_aktiv 1600;
BA_REL_ "GenSigTimeoutTime" BU_SG_REL_ ZR_High SG_ 916 WBA_GE_Zusatzwarnungen 1600;
BA_REL_ "GenSigTimeoutTime" BU_SG_REL_ ZR_High SG_ 916 GE_Sollgang 1600;
BA_REL_ "GenSigTimeoutTime" BU_SG_REL_ ZR_High SG_ 916 GE_Tipschaltempf_verfuegbar 1600;
BA_REL_ "GenSigTimeoutTime" BU_SG_REL_ ZR_High SG_ 1361 WFS_Schluessel_Fahrberecht 2000;
BA_REL_ "GenSigTimeoutTime" BU_SG_REL_ ZR_High SG_ 1361 WFS_ID_Geb_autorisiert 2000;
BA_REL_ "GenSigTimeoutTime" BU_SG_REL_ ZR_High SG_ 1361 WFS_ID_Geb_steckt 2000;
BA_REL_ "GenSigTimeoutTime" BU_SG_REL_ ZR_High SG_ 1361 WFS_Schluessel_Soll 2000;
BA_REL_ "GenSigTimeoutTime" BU_SG_REL_ ZR_High SG_ 1361 WFS_Schluessel_Ist 2000;
BA_REL_ "GenSigTimeoutTime" BU_SG_REL_ ZR_High SG_ 1702 Wischer_vorne_aktiv 5000;
BA_REL_ "GenSigTimeoutTime" BU_SG_REL_ ZR_High SG_ 1702 Waschen_vorne_aktiv 5000;
BA_REL_ "GenSigTimeoutTime" BU_SG_REL_ ZR_High SG_ 1702 Wischer_vorne_Normal 5000;
BA_REL_ "GenSigTimeoutTime" BU_SG_REL_ ZR_High SG_ 1702 Wischer_vorne_Schnell 5000;
BA_REL_ "GenSigTimeoutTime" BU_SG_REL_ ZR_High SG_ 1702 Wischer_vorne_defekt 5000;
BA_REL_ "GenSigTimeoutTime" BU_SG_REL_ ZR_High SG_ 1702 Wischer1_Wischgeschwindigkeit 5000;
BA_REL_ "GenSigTimeoutTime" BU_SG_REL_ ZR_High SG_ 1702 BCM1_SRA_aktiv 5000;
BA_REL_ "GenSigTimeoutTime" BU_SG_REL_ ZR_High SG_ 1702 Heckwischer_Anforderung 5000;
BA_REL_ "GenSigTimeoutTime" BU_SG_REL_ ZR_High SG_ 2527679496 WIV_Verschleissindex_02 3200;
BA_REL_ "GenSigTimeoutTime" BU_SG_REL_ ZR_High SG_ 2527679496 WIV_Verschleissindex_Ueberlauf 3200;
BA_REL_ "GenSigTimeoutTime" BU_SG_REL_ ZR_High SG_ 2527679496 WIV_Russindex_02 3200;
BA_REL_ "GenSigTimeoutTime" BU_SG_REL_ ZR_High SG_ 2527679496 WIV_Russindex_Ueberlauf 3200;
BA_REL_ "GenSigTimeoutTime" BU_SG_REL_ ZR_High SG_ 2527679496 WIV_t_min 3200;
BA_REL_ "GenSigTimeoutTime" BU_SG_REL_ ZR_High SG_ 2527679496 WIV_t_max 3200;
BA_REL_ "GenSigTimeoutTime" BU_SG_REL_ ZR_High SG_ 2527679496 WIV_W_min 3200;
BA_REL_ "GenSigTimeoutTime" BU_SG_REL_ ZR_High SG_ 2527679496 WIV_W_max 3200;
BA_REL_ "GenSigTimeoutTime" BU_SG_REL_ ZR_High SG_ 389 ZFH_FS_ManHoch 500;
BA_REL_ "GenSigTimeoutTime" BU_SG_REL_ ZR_High SG_ 389 ZFH_FS_AutoHoch 500;
BA_REL_ "GenSigTimeoutTime" BU_SG_REL_ ZR_High SG_ 389 ZFH_FS_ManTief 500;
BA_REL_ "GenSigTimeoutTime" BU_SG_REL_ ZR_High SG_ 389 ZFH_FS_AutoTief 500;
BA_REL_ "GenSigTimeoutTime" BU_SG_REL_ ZR_High SG_ 389 ZFH_BFS_ManHoch 500;
BA_REL_ "GenSigTimeoutTime" BU_SG_REL_ ZR_High SG_ 389 ZFH_BFS_AutoHoch 500;
BA_REL_ "GenSigTimeoutTime" BU_SG_REL_ ZR_High SG_ 389 ZFH_BFS_ManTief 500;
BA_REL_ "GenSigTimeoutTime" BU_SG_REL_ ZR_High SG_ 389 ZFH_BFS_AutoTief 500;
BA_REL_ "GenSigTimeoutTime" BU_SG_REL_ ZR_High SG_ 389 ZFH_HFS_ManHoch 500;
BA_REL_ "GenSigTimeoutTime" BU_SG_REL_ ZR_High SG_ 389 ZFH_HFS_AutoHoch 500;
BA_REL_ "GenSigTimeoutTime" BU_SG_REL_ ZR_High SG_ 389 ZFH_HFS_ManTief 500;
BA_REL_ "GenSigTimeoutTime" BU_SG_REL_ ZR_High SG_ 389 ZFH_HFS_AutoTief 500;
BA_REL_ "GenSigTimeoutTime" BU_SG_REL_ ZR_High SG_ 389 ZFH_HBFS_ManHoch 500;
BA_REL_ "GenSigTimeoutTime" BU_SG_REL_ ZR_High SG_ 389 ZFH_HBFS_AutoHoch 500;
BA_REL_ "GenSigTimeoutTime" BU_SG_REL_ ZR_High SG_ 389 ZFH_HBFS_ManTief 500;
BA_REL_ "GenSigTimeoutTime" BU_SG_REL_ ZR_High SG_ 389 ZFH_HBFS_AutoTief 500;
BA_REL_ "GenSigTimeoutTime" BU_SG_REL_ ZR_High SG_ 389 ZFH_zentral_zu 500;
BA_REL_ "GenSigTimeoutTime" BU_SG_REL_ ZR_High SG_ 389 ZFH_zentral_auf 500;
BA_REL_ "GenSigTimeoutTime" BU_SG_REL_ ZR_High SG_ 389 Krypt_Schluesselschalter_auf 500;
BA_REL_ "GenSigTimeoutTime" BU_SG_REL_ ZR_High SG_ 389 Krypt_Schluesselschalter_zu 500;
BA_REL_ "GenSigTimeoutTime" BU_SG_REL_ ZR_High SG_ 392 BT_FH_BT_ManHoch 500;
BA_REL_ "GenSigTimeoutTime" BU_SG_REL_ ZR_High SG_ 392 BT_FH_BT_AutoHoch 500;
BA_REL_ "GenSigTimeoutTime" BU_SG_REL_ ZR_High SG_ 392 BT_FH_BT_ManTief 500;
BA_REL_ "GenSigTimeoutTime" BU_SG_REL_ ZR_High SG_ 392 BT_FH_BT_AutoTief 500;
BA_REL_ "GenSigTimeoutTime" BU_SG_REL_ ZR_High SG_ 392 BT_FH_FT_ManHoch 500;
BA_REL_ "GenSigTimeoutTime" BU_SG_REL_ ZR_High SG_ 392 BT_FH_FT_AutoHoch 500;
BA_REL_ "GenSigTimeoutTime" BU_SG_REL_ ZR_High SG_ 392 BT_FH_FT_ManTief 500;
BA_REL_ "GenSigTimeoutTime" BU_SG_REL_ ZR_High SG_ 392 BT_FH_FT_AutoTief 500;
BA_REL_ "GenSigTimeoutTime" BU_SG_REL_ ZR_High SG_ 392 BT_FH_HFS_ManHoch 500;
BA_REL_ "GenSigTimeoutTime" BU_SG_REL_ ZR_High SG_ 392 BT_FH_HFS_AutoHoch 500;
BA_REL_ "GenSigTimeoutTime" BU_SG_REL_ ZR_High SG_ 392 BT_FH_HFS_ManTief 500;
BA_REL_ "GenSigTimeoutTime" BU_SG_REL_ ZR_High SG_ 392 BT_FH_HFS_AutoTief 500;
BA_REL_ "GenSigTimeoutTime" BU_SG_REL_ ZR_High SG_ 392 BT_FH_HBFS_ManHoch 500;
BA_REL_ "GenSigTimeoutTime" BU_SG_REL_ ZR_High SG_ 392 BT_FH_HBFS_AutoHoch 500;
BA_REL_ "GenSigTimeoutTime" BU_SG_REL_ ZR_High SG_ 392 BT_FH_HBFS_ManTief 500;
BA_REL_ "GenSigTimeoutTime" BU_SG_REL_ ZR_High SG_ 392 BT_FH_HBFS_AutoTief 500;
BA_REL_ "GenSigTimeoutTime" BU_SG_REL_ ZR_High SG_ 392 BT_SP_hoch 500;
BA_REL_ "GenSigTimeoutTime" BU_SG_REL_ ZR_High SG_ 392 BT_SP_tief 500;
BA_REL_ "GenSigTimeoutTime" BU_SG_REL_ ZR_High SG_ 392 BT_SP_links 500;
BA_REL_ "GenSigTimeoutTime" BU_SG_REL_ ZR_High SG_ 392 BT_SP_rechts 500;
BA_REL_ "GenSigTimeoutTime" BU_SG_REL_ ZR_High SG_ 392 BT_SP_Garagenstellung 500;
BA_REL_ "GenSigTimeoutTime" BU_SG_REL_ ZR_High SG_ 392 BT_SP_Fahrstellung 500;
BA_REL_ "GenSigTimeoutTime" BU_SG_REL_ ZR_High SG_ 392 BT_FH_zentral_zu 500;
BA_REL_ "GenSigTimeoutTime" BU_SG_REL_ ZR_High SG_ 392 BT_FH_zentral_auf 500;
BA_REL_ "GenSigTimeoutTime" BU_SG_REL_ ZR_High SG_ 388 ZV_FT_verriegeln 5000;
BA_REL_ "GenSigTimeoutTime" BU_SG_REL_ ZR_High SG_ 388 ZV_FT_entriegeln 5000;
BA_REL_ "GenSigTimeoutTime" BU_SG_REL_ ZR_High SG_ 388 ZV_BT_verriegeln 5000;
BA_REL_ "GenSigTimeoutTime" BU_SG_REL_ ZR_High SG_ 388 ZV_BT_entriegeln 5000;
BA_REL_ "GenSigTimeoutTime" BU_SG_REL_ ZR_High SG_ 388 ZV_HFS_verriegeln 5000;
BA_REL_ "GenSigTimeoutTime" BU_SG_REL_ ZR_High SG_ 388 ZV_HFS_entriegeln 5000;
BA_REL_ "GenSigTimeoutTime" BU_SG_REL_ ZR_High SG_ 388 ZV_HBFS_verriegeln 5000;
BA_REL_ "GenSigTimeoutTime" BU_SG_REL_ ZR_High SG_ 388 ZV_HBFS_entriegeln 5000;
BA_REL_ "GenSigTimeoutTime" BU_SG_REL_ ZR_High SG_ 388 ZV_zentral_safen 5000;
BA_REL_ "GenSigTimeoutTime" BU_SG_REL_ ZR_High SG_ 388 ZV_zentral_entsafen 5000;
BA_REL_ "GenSigTimeoutTime" BU_SG_REL_ ZR_High SG_ 388 ZV_Spg_Anklappen 5000;
BA_REL_ "GenSigTimeoutTime" BU_SG_REL_ ZR_High SG_ 388 ZV_Softtouch_betaetigt 5000;
BA_REL_ "GenSigTimeoutTime" BU_SG_REL_ ZR_High SG_ 388 ZV_LED_Steuerung 5000;
BA_REL_ "GenSigTimeoutTime" BU_SG_REL_ ZR_High SG_ 388 ZV_LED_Uebernahme 5000;
BA_REL_ "GenSigTimeoutTime" BU_SG_REL_ ZR_High SG_ 388 ZV_auf_FT 5000;
BA_REL_ "GenSigTimeoutTime" BU_SG_REL_ ZR_High SG_ 388 ZV_zu_FT 5000;
BA_REL_ "GenSigTimeoutTime" BU_SG_REL_ ZR_High SG_ 388 ZV_auf_BT 5000;
BA_REL_ "GenSigTimeoutTime" BU_SG_REL_ ZR_High SG_ 388 ZV_zu_BT 5000;
BA_REL_ "GenSigTimeoutTime" BU_SG_REL_ ZR_High SG_ 388 ZV_auf_Kessy 5000;
BA_REL_ "GenSigTimeoutTime" BU_SG_REL_ ZR_High SG_ 388 ZV_zu_Kessy 5000;
BA_REL_ "GenSigTimeoutTime" BU_SG_REL_ ZR_High SG_ 388 ZV_auf_Funk 5000;
BA_REL_ "GenSigTimeoutTime" BU_SG_REL_ ZR_High SG_ 388 ZV_zu_Funk 5000;
BA_REL_ "GenSigTimeoutTime" BU_SG_REL_ ZR_High SG_ 388 VIP_Sensor_betaetigt 5000;
BA_REL_ "GenSigTimeoutTime" BU_SG_REL_ ZR_High SG_ 388 ZV_zu_Zeitl_Nachverr 5000;
BA_REL_ "GenSigTimeoutTime" BU_SG_REL_ ZR_High SG_ 388 ZV_HSK_entriegeln 5000;
BA_REL_ "GenSigTimeoutTime" BU_SG_REL_ ZR_High SG_ 388 ZV_HSK_verriegeln 5000;
BA_REL_ "GenSigTimeoutTime" BU_SG_REL_ ZR_High SG_ 388 ZV_Verdeck_zu 5000;
BA_REL_ "GenSigTimeoutTime" BU_SG_REL_ ZR_High SG_ 388 ZV_Verdeck_auf 5000;
BA_REL_ "GenSigTimeoutTime" BU_SG_REL_ ZR_High SG_ 388 FH_FT_hoch 5000;
BA_REL_ "GenSigTimeoutTime" BU_SG_REL_ ZR_High SG_ 388 FH_FT_tief 5000;
BA_REL_ "GenSigTimeoutTime" BU_SG_REL_ ZR_High SG_ 388 FH_BT_hoch 5000;
BA_REL_ "GenSigTimeoutTime" BU_SG_REL_ ZR_High SG_ 388 FH_BT_tief 5000;
BA_REL_ "GenSigTimeoutTime" BU_SG_REL_ ZR_High SG_ 388 FH_HFS_hoch 5000;
BA_REL_ "GenSigTimeoutTime" BU_SG_REL_ ZR_High SG_ 388 FH_HFS_tief 5000;
BA_REL_ "GenSigTimeoutTime" BU_SG_REL_ ZR_High SG_ 388 FH_HBFS_hoch 5000;
BA_REL_ "GenSigTimeoutTime" BU_SG_REL_ ZR_High SG_ 388 FH_HBFS_tief 5000;
BA_REL_ "GenSigTimeoutTime" BU_SG_REL_ ZR_High SG_ 388 ZV_auto_Ansteuerung 5000;
BA_REL_ "GenSigTimeoutTime" BU_SG_REL_ ZR_High SG_ 1411 BCM_Verdeck_Freigabe 2000;
BA_REL_ "GenSigTimeoutTime" BU_SG_REL_ ZR_High SG_ 1411 ZV_verriegelt_intern_ist 2000;
BA_REL_ "GenSigTimeoutTime" BU_SG_REL_ ZR_High SG_ 1411 ZV_verriegelt_extern_ist 2000;
BA_REL_ "GenSigTimeoutTime" BU_SG_REL_ ZR_High SG_ 1411 ZV_verriegelt_intern_soll 2000;
BA_REL_ "GenSigTimeoutTime" BU_SG_REL_ ZR_High SG_ 1411 ZV_verriegelt_extern_soll 2000;
BA_REL_ "GenSigTimeoutTime" BU_SG_REL_ ZR_High SG_ 1411 ZV_gesafet_extern_ist 2000;
BA_REL_ "GenSigTimeoutTime" BU_SG_REL_ ZR_High SG_ 1411 ZV_gesafet_extern_soll 2000;
BA_REL_ "GenSigTimeoutTime" BU_SG_REL_ ZR_High SG_ 1411 ZV_FT_offen 2000;
BA_REL_ "GenSigTimeoutTime" BU_SG_REL_ ZR_High SG_ 1411 ZV_BT_offen 2000;
BA_REL_ "GenSigTimeoutTime" BU_SG_REL_ ZR_High SG_ 1411 ZV_HFS_offen 2000;
BA_REL_ "GenSigTimeoutTime" BU_SG_REL_ ZR_High SG_ 1411 ZV_HBFS_offen 2000;
BA_REL_ "GenSigTimeoutTime" BU_SG_REL_ ZR_High SG_ 1411 ZV_HD_offen 2000;
BA_REL_ "GenSigTimeoutTime" BU_SG_REL_ ZR_High SG_ 1411 ZV_HS_offen 2000;
BA_REL_ "GenSigTimeoutTime" BU_SG_REL_ ZR_High SG_ 1411 IRUE_aktiv 2000;
BA_REL_ "GenSigTimeoutTime" BU_SG_REL_ ZR_High SG_ 1411 DWA_aktiv 2000;
BA_REL_ "GenSigTimeoutTime" BU_SG_REL_ ZR_High SG_ 1411 HD_Hauptraste 2000;
BA_REL_ "GenSigTimeoutTime" BU_SG_REL_ ZR_High SG_ 1411 HD_Vorraste 2000;
BA_REL_ "GenSigTimeoutTime" BU_SG_REL_ ZR_High SG_ 1411 ZV_Schluessel_Zugang 2000;
BA_REL_ "GenSigTimeoutTime" BU_SG_REL_ ZR_High SG_ 1411 ZV_SafeFunktion_aktiv 2000;
BA_REL_ "GenSigTimeoutTime" BU_SG_REL_ ZR_High SG_ 1411 FBS_Warn_Schluessel_Batt 2000;
BA_REL_ "GenSigTimeoutTime" BU_SG_REL_ ZR_High SG_ 1411 ZV_ist_Zustand_verfuegbar 2000;
BA_REL_ "GenSigTimeoutTime" BU_SG_REL_ ZR_High SG_ 1411 IRUE_Taster_Fkts_LED 2000;
BA_REL_ "GenSigTimeoutTime" BU_SG_REL_ ZR_High SG_ 1411 ZV_Tankklappe_offen 2000;
BA_REL_ "GenSigTimeoutTime" BU_SG_REL_ ZR_High SG_ 1411 ZV_Rollo_auf 2000;
BA_REL_ "GenSigTimeoutTime" BU_SG_REL_ ZR_High SG_ 1411 ZV_Rollo_zu 2000;
BA_REL_ "GenSigTimeoutTime" BU_SG_REL_ ZR_High SG_ 1411 ZV_SAD_auf 2000;
BA_REL_ "GenSigTimeoutTime" BU_SG_REL_ ZR_High SG_ 1411 ZV_SAD_zu 2000;
BA_REL_ "GenSigTimeoutTime" BU_SG_REL_ ZR_High SG_ 1411 BCM_Tankklappensteller_Fehler 2000;
BA_REL_ "GenSigTimeoutTime" BU_SG_REL_ ZR_LIMU SG_ 995 VS_VD_zu_ver 1000;
BA_REL_ "GenSigTimeoutTime" BU_SG_REL_ ZR_LIMU SG_ 1716 VIN_01_MUX 2000;
BA_REL_ "GenSigTimeoutTime" BU_SG_REL_ ZR_LIMU SG_ 1716 KS_Geheimnis_1 2000;
BA_REL_ "GenSigTimeoutTime" BU_SG_REL_ ZR_LIMU SG_ 1716 VIN_4 2000;
BA_REL_ "GenSigTimeoutTime" BU_SG_REL_ ZR_LIMU SG_ 1716 VIN_11 2000;
BA_REL_ "GenSigTimeoutTime" BU_SG_REL_ ZR_LIMU SG_ 1716 KS_Geheimnis_2 2000;
BA_REL_ "GenSigTimeoutTime" BU_SG_REL_ ZR_LIMU SG_ 1716 VIN_5 2000;
BA_REL_ "GenSigTimeoutTime" BU_SG_REL_ ZR_LIMU SG_ 1716 VIN_12 2000;
BA_REL_ "GenSigTimeoutTime" BU_SG_REL_ ZR_LIMU SG_ 1716 KS_Geheimnis_3 2000;
BA_REL_ "GenSigTimeoutTime" BU_SG_REL_ ZR_LIMU SG_ 1716 VIN_6 2000;
BA_REL_ "GenSigTimeoutTime" BU_SG_REL_ ZR_LIMU SG_ 1716 VIN_13 2000;
BA_REL_ "GenSigTimeoutTime" BU_SG_REL_ ZR_LIMU SG_ 1716 KS_Geheimnis_4 2000;
BA_REL_ "GenSigTimeoutTime" BU_SG_REL_ ZR_LIMU SG_ 1716 VIN_7 2000;
BA_REL_ "GenSigTimeoutTime" BU_SG_REL_ ZR_LIMU SG_ 1716 VIN_14 2000;
BA_REL_ "GenSigTimeoutTime" BU_SG_REL_ ZR_LIMU SG_ 1716 VIN_1 2000;
BA_REL_ "GenSigTimeoutTime" BU_SG_REL_ ZR_LIMU SG_ 1716 VIN_8 2000;
BA_REL_ "GenSigTimeoutTime" BU_SG_REL_ ZR_LIMU SG_ 1716 VIN_15 2000;
BA_REL_ "GenSigTimeoutTime" BU_SG_REL_ ZR_LIMU SG_ 1716 VIN_2 2000;
BA_REL_ "GenSigTimeoutTime" BU_SG_REL_ ZR_LIMU SG_ 1716 VIN_9 2000;
BA_REL_ "GenSigTimeoutTime" BU_SG_REL_ ZR_LIMU SG_ 1716 VIN_16 2000;
BA_REL_ "GenSigTimeoutTime" BU_SG_REL_ ZR_LIMU SG_ 1716 VIN_3 2000;
BA_REL_ "GenSigTimeoutTime" BU_SG_REL_ ZR_LIMU SG_ 1716 VIN_10 2000;
BA_REL_ "GenSigTimeoutTime" BU_SG_REL_ ZR_LIMU SG_ 1716 VIN_17 2000;
BA_REL_ "GenSigTimeoutTime" BU_SG_REL_ ZR_LIMU SG_ 385 VZE_Anzeigemodus 2000;
BA_REL_ "GenSigTimeoutTime" BU_SG_REL_ ZR_LIMU SG_ 385 VZE_Hinweistext 2000;
BA_REL_ "GenSigTimeoutTime" BU_SG_REL_ ZR_LIMU SG_ 385 VZE_Verkehrszeichen_Einheit 2000;
BA_REL_ "GenSigTimeoutTime" BU_SG_REL_ ZR_LIMU SG_ 385 VZE_Verkehrszeichen_1 2000;
BA_REL_ "GenSigTimeoutTime" BU_SG_REL_ ZR_LIMU SG_ 385 VZE_Verkehrszeichen_2 2000;
BA_REL_ "GenSigTimeoutTime" BU_SG_REL_ ZR_LIMU SG_ 385 VZE_Verkehrszeichen_3 2000;
BA_REL_ "GenSigTimeoutTime" BU_SG_REL_ ZR_LIMU SG_ 385 VZE_Warnung_Verkehrszeichen_1 2000;
BA_REL_ "GenSigTimeoutTime" BU_SG_REL_ ZR_LIMU SG_ 385 VZE_Warnung_Verkehrszeichen_2 2000;
BA_REL_ "GenSigTimeoutTime" BU_SG_REL_ ZR_LIMU SG_ 385 VZE_Warnung_Verkehrszeichen_3 2000;
BA_REL_ "GenSigTimeoutTime" BU_SG_REL_ ZR_LIMU SG_ 385 VZE_Zusatzschild_1 2000;
BA_REL_ "GenSigTimeoutTime" BU_SG_REL_ ZR_LIMU SG_ 385 VZE_Zusatzschild_2 2000;
BA_REL_ "GenSigTimeoutTime" BU_SG_REL_ ZR_LIMU SG_ 385 VZE_Zusatzschild_3 2000;
BA_REL_ "GenSigTimeoutTime" BU_SG_REL_ ZR_LIMU SG_ 385 VZE_Zeichen_01_KameraWied 2000;
BA_REL_ "GenSigTimeoutTime" BU_SG_REL_ ZR_LIMU SG_ 385 VZE_Zeichen_02_KameraWied 2000;
BA_REL_ "GenSigTimeoutTime" BU_SG_REL_ ZR_LIMU SG_ 385 VZE_Zeichen_03_KameraWied 2000;
BA_REL_ "GenSigTimeoutTime" BU_SG_REL_ ZR_LIMU SG_ 385 VZE_Zeichen_01_Kamera 2000;
BA_REL_ "GenSigTimeoutTime" BU_SG_REL_ ZR_LIMU SG_ 385 VZE_Zeichen_01_Karte 2000;
BA_REL_ "GenSigTimeoutTime" BU_SG_REL_ ZR_LIMU SG_ 385 VZE_Zeichen_01_Gesetz 2000;
BA_REL_ "GenSigTimeoutTime" BU_SG_REL_ ZR_LIMU SG_ 385 VZE_Zeichen_02_Kamera 2000;
BA_REL_ "GenSigTimeoutTime" BU_SG_REL_ ZR_LIMU SG_ 385 VZE_Zeichen_02_Karte 2000;
BA_REL_ "GenSigTimeoutTime" BU_SG_REL_ ZR_LIMU SG_ 385 VZE_Zeichen_02_Gesetz 2000;
BA_REL_ "GenSigTimeoutTime" BU_SG_REL_ ZR_LIMU SG_ 385 VZE_Zeichen_03_Kamera 2000;
BA_REL_ "GenSigTimeoutTime" BU_SG_REL_ ZR_LIMU SG_ 385 VZE_Zeichen_03_Karte 2000;
BA_REL_ "GenSigTimeoutTime" BU_SG_REL_ ZR_LIMU SG_ 385 VZE_Zeichen_03_Gesetz 2000;
BA_REL_ "GenSigTimeoutTime" BU_SG_REL_ ZR_LIMU SG_ 385 VZE_Gong 2000;
BA_REL_ "GenSigTimeoutTime" BU_SG_REL_ ZR_LIMU SG_ 668 VZE_Verkehrszeichen_4 2000;
BA_REL_ "GenSigTimeoutTime" BU_SG_REL_ ZR_LIMU SG_ 668 VZE_Verkehrszeichen_5 2000;
BA_REL_ "GenSigTimeoutTime" BU_SG_REL_ ZR_LIMU SG_ 1120 VZE_Verkehrszeichen_6 2000;
BA_REL_ "GenSigTimeoutTime" BU_SG_REL_ ZR_LIMU SG_ 1120 VZE_Zusatzschild_6 2000;
BA_REL_ "GenSigTimeoutTime" BU_SG_REL_ ZR_LIMU SG_ 1120 VZE_Umweltinfo_Naesse 2000;
BA_REL_ "GenSigTimeoutTime" BU_SG_REL_ ZR_LIMU SG_ 1120 VZE_Umweltinfo_Nebel 2000;
BA_REL_ "GenSigTimeoutTime" BU_SG_REL_ ZR_LIMU SG_ 1120 VZE_Umweltinfo_Anhaengerbetrieb 2000;
BA_REL_ "GenSigTimeoutTime" BU_SG_REL_ ZR_LIMU SG_ 916 WBA_Fahrstufe_02 1600;
BA_REL_ "GenSigTimeoutTime" BU_SG_REL_ ZR_LIMU SG_ 916 WBA_eing_Gang_02 1600;
BA_REL_ "GenSigTimeoutTime" BU_SG_REL_ ZR_LIMU SG_ 916 WBA_Segeln_aktiv 1600;
BA_REL_ "GenSigTimeoutTime" BU_SG_REL_ ZR_LIMU SG_ 916 WBA_GE_Zusatzwarnungen 1600;
BA_REL_ "GenSigTimeoutTime" BU_SG_REL_ ZR_LIMU SG_ 916 GE_Sollgang 1600;
BA_REL_ "GenSigTimeoutTime" BU_SG_REL_ ZR_LIMU SG_ 1361 WFS_Schluessel_Fahrberecht 2000;
BA_REL_ "GenSigTimeoutTime" BU_SG_REL_ ZR_LIMU SG_ 1361 WFS_Schluessel_Soll 2000;
BA_REL_ "GenSigTimeoutTime" BU_SG_REL_ ZR_LIMU SG_ 1361 WFS_Schluessel_Ist 2000;
BA_REL_ "GenSigTimeoutTime" BU_SG_REL_ ZR_LIMU SG_ 1411 ZV_verriegelt_extern_soll 2000;
BA_REL_ "GenSigTimeoutTime" BU_SG_REL_ ZR_LIMU SG_ 1411 ZV_gesafet_extern_soll 2000;
BA_REL_ "GenSigTimeoutTime" BU_SG_REL_ ZR_LIMU SG_ 1411 ZV_FT_offen 2000;
BA_REL_ "GenSigTimeoutTime" BU_SG_REL_ ZR_LIMU SG_ 1411 ZV_BT_offen 2000;
BA_REL_ "GenSigTimeoutTime" BU_SG_REL_ ZR_LIMU SG_ 1411 ZV_HFS_offen 2000;
BA_REL_ "GenSigTimeoutTime" BU_SG_REL_ ZR_LIMU SG_ 1411 ZV_HBFS_offen 2000;
BA_REL_ "GenSigTimeoutTime" BU_SG_REL_ ZR_LIMU SG_ 1411 ZV_HD_offen 2000;
BA_REL_ "GenSigTimeoutTime" BU_SG_REL_ ZR_LIMU SG_ 711 BCM2_ZV_Tasten_HMI_Anf 5000;
BA_REL_ "GenSigTimeoutTime" BU_SG_REL_ ZR_MIB_TOP_ab_Gen3 SG_ 995 VS_VD_zu_ver 1000;
BA_REL_ "GenSigTimeoutTime" BU_SG_REL_ ZR_MIB_TOP_ab_Gen3 SG_ 1716 VIN_01_MUX 2000;
BA_REL_ "GenSigTimeoutTime" BU_SG_REL_ ZR_MIB_TOP_ab_Gen3 SG_ 1716 KS_Geheimnis_1 2000;
BA_REL_ "GenSigTimeoutTime" BU_SG_REL_ ZR_MIB_TOP_ab_Gen3 SG_ 1716 VIN_4 2000;
BA_REL_ "GenSigTimeoutTime" BU_SG_REL_ ZR_MIB_TOP_ab_Gen3 SG_ 1716 VIN_11 2000;
BA_REL_ "GenSigTimeoutTime" BU_SG_REL_ ZR_MIB_TOP_ab_Gen3 SG_ 1716 KS_Geheimnis_2 2000;
BA_REL_ "GenSigTimeoutTime" BU_SG_REL_ ZR_MIB_TOP_ab_Gen3 SG_ 1716 VIN_5 2000;
BA_REL_ "GenSigTimeoutTime" BU_SG_REL_ ZR_MIB_TOP_ab_Gen3 SG_ 1716 VIN_12 2000;
BA_REL_ "GenSigTimeoutTime" BU_SG_REL_ ZR_MIB_TOP_ab_Gen3 SG_ 1716 KS_Geheimnis_3 2000;
BA_REL_ "GenSigTimeoutTime" BU_SG_REL_ ZR_MIB_TOP_ab_Gen3 SG_ 1716 VIN_6 2000;
BA_REL_ "GenSigTimeoutTime" BU_SG_REL_ ZR_MIB_TOP_ab_Gen3 SG_ 1716 VIN_13 2000;
BA_REL_ "GenSigTimeoutTime" BU_SG_REL_ ZR_MIB_TOP_ab_Gen3 SG_ 1716 KS_Geheimnis_4 2000;
BA_REL_ "GenSigTimeoutTime" BU_SG_REL_ ZR_MIB_TOP_ab_Gen3 SG_ 1716 VIN_7 2000;
BA_REL_ "GenSigTimeoutTime" BU_SG_REL_ ZR_MIB_TOP_ab_Gen3 SG_ 1716 VIN_14 2000;
BA_REL_ "GenSigTimeoutTime" BU_SG_REL_ ZR_MIB_TOP_ab_Gen3 SG_ 1716 VIN_1 2000;
BA_REL_ "GenSigTimeoutTime" BU_SG_REL_ ZR_MIB_TOP_ab_Gen3 SG_ 1716 VIN_8 2000;
BA_REL_ "GenSigTimeoutTime" BU_SG_REL_ ZR_MIB_TOP_ab_Gen3 SG_ 1716 VIN_15 2000;
BA_REL_ "GenSigTimeoutTime" BU_SG_REL_ ZR_MIB_TOP_ab_Gen3 SG_ 1716 VIN_2 2000;
BA_REL_ "GenSigTimeoutTime" BU_SG_REL_ ZR_MIB_TOP_ab_Gen3 SG_ 1716 VIN_9 2000;
BA_REL_ "GenSigTimeoutTime" BU_SG_REL_ ZR_MIB_TOP_ab_Gen3 SG_ 1716 VIN_16 2000;
BA_REL_ "GenSigTimeoutTime" BU_SG_REL_ ZR_MIB_TOP_ab_Gen3 SG_ 1716 VIN_3 2000;
BA_REL_ "GenSigTimeoutTime" BU_SG_REL_ ZR_MIB_TOP_ab_Gen3 SG_ 1716 VIN_10 2000;
BA_REL_ "GenSigTimeoutTime" BU_SG_REL_ ZR_MIB_TOP_ab_Gen3 SG_ 1716 VIN_17 2000;
BA_REL_ "GenSigTimeoutTime" BU_SG_REL_ ZR_MIB_TOP_ab_Gen3 SG_ 385 VZE_Anzeigemodus 2000;
BA_REL_ "GenSigTimeoutTime" BU_SG_REL_ ZR_MIB_TOP_ab_Gen3 SG_ 385 VZE_Hinweistext 2000;
BA_REL_ "GenSigTimeoutTime" BU_SG_REL_ ZR_MIB_TOP_ab_Gen3 SG_ 385 VZE_Verkehrszeichen_Einheit 2000;
BA_REL_ "GenSigTimeoutTime" BU_SG_REL_ ZR_MIB_TOP_ab_Gen3 SG_ 385 VZE_Verkehrszeichen_1 2000;
BA_REL_ "GenSigTimeoutTime" BU_SG_REL_ ZR_MIB_TOP_ab_Gen3 SG_ 385 VZE_Verkehrszeichen_2 2000;
BA_REL_ "GenSigTimeoutTime" BU_SG_REL_ ZR_MIB_TOP_ab_Gen3 SG_ 385 VZE_Verkehrszeichen_3 2000;
BA_REL_ "GenSigTimeoutTime" BU_SG_REL_ ZR_MIB_TOP_ab_Gen3 SG_ 385 VZE_Warnung_Verkehrszeichen_1 2000;
BA_REL_ "GenSigTimeoutTime" BU_SG_REL_ ZR_MIB_TOP_ab_Gen3 SG_ 385 VZE_Warnung_Verkehrszeichen_2 2000;
BA_REL_ "GenSigTimeoutTime" BU_SG_REL_ ZR_MIB_TOP_ab_Gen3 SG_ 385 VZE_Warnung_Verkehrszeichen_3 2000;
BA_REL_ "GenSigTimeoutTime" BU_SG_REL_ ZR_MIB_TOP_ab_Gen3 SG_ 385 VZE_Zusatzschild_1 2000;
BA_REL_ "GenSigTimeoutTime" BU_SG_REL_ ZR_MIB_TOP_ab_Gen3 SG_ 385 VZE_Zusatzschild_2 2000;
BA_REL_ "GenSigTimeoutTime" BU_SG_REL_ ZR_MIB_TOP_ab_Gen3 SG_ 385 VZE_Zusatzschild_3 2000;
BA_REL_ "GenSigTimeoutTime" BU_SG_REL_ ZR_MIB_TOP_ab_Gen3 SG_ 385 VZE_Zeichen_01_KameraWied 2000;
BA_REL_ "GenSigTimeoutTime" BU_SG_REL_ ZR_MIB_TOP_ab_Gen3 SG_ 385 VZE_Zeichen_02_KameraWied 2000;
BA_REL_ "GenSigTimeoutTime" BU_SG_REL_ ZR_MIB_TOP_ab_Gen3 SG_ 385 VZE_Zeichen_03_KameraWied 2000;
BA_REL_ "GenSigTimeoutTime" BU_SG_REL_ ZR_MIB_TOP_ab_Gen3 SG_ 385 VZE_Zeichen_01_Kamera 2000;
BA_REL_ "GenSigTimeoutTime" BU_SG_REL_ ZR_MIB_TOP_ab_Gen3 SG_ 385 VZE_Zeichen_01_Karte 2000;
BA_REL_ "GenSigTimeoutTime" BU_SG_REL_ ZR_MIB_TOP_ab_Gen3 SG_ 385 VZE_Zeichen_01_Gesetz 2000;
BA_REL_ "GenSigTimeoutTime" BU_SG_REL_ ZR_MIB_TOP_ab_Gen3 SG_ 385 VZE_Zeichen_02_Kamera 2000;
BA_REL_ "GenSigTimeoutTime" BU_SG_REL_ ZR_MIB_TOP_ab_Gen3 SG_ 385 VZE_Zeichen_02_Karte 2000;
BA_REL_ "GenSigTimeoutTime" BU_SG_REL_ ZR_MIB_TOP_ab_Gen3 SG_ 385 VZE_Zeichen_02_Gesetz 2000;
BA_REL_ "GenSigTimeoutTime" BU_SG_REL_ ZR_MIB_TOP_ab_Gen3 SG_ 385 VZE_Zeichen_03_Kamera 2000;
BA_REL_ "GenSigTimeoutTime" BU_SG_REL_ ZR_MIB_TOP_ab_Gen3 SG_ 385 VZE_Zeichen_03_Karte 2000;
BA_REL_ "GenSigTimeoutTime" BU_SG_REL_ ZR_MIB_TOP_ab_Gen3 SG_ 385 VZE_Zeichen_03_Gesetz 2000;
BA_REL_ "GenSigTimeoutTime" BU_SG_REL_ ZR_MIB_TOP_ab_Gen3 SG_ 385 VZE_Gong 2000;
BA_REL_ "GenSigTimeoutTime" BU_SG_REL_ ZR_MIB_TOP_ab_Gen3 SG_ 668 VZE_Verkehrszeichen_4 2000;
BA_REL_ "GenSigTimeoutTime" BU_SG_REL_ ZR_MIB_TOP_ab_Gen3 SG_ 668 VZE_Verkehrszeichen_5 2000;
BA_REL_ "GenSigTimeoutTime" BU_SG_REL_ ZR_MIB_TOP_ab_Gen3 SG_ 1120 VZE_Verkehrszeichen_6 2000;
BA_REL_ "GenSigTimeoutTime" BU_SG_REL_ ZR_MIB_TOP_ab_Gen3 SG_ 1120 VZE_Zusatzschild_6 2000;
BA_REL_ "GenSigTimeoutTime" BU_SG_REL_ ZR_MIB_TOP_ab_Gen3 SG_ 1120 VZE_Umweltinfo_Naesse 2000;
BA_REL_ "GenSigTimeoutTime" BU_SG_REL_ ZR_MIB_TOP_ab_Gen3 SG_ 1120 VZE_Umweltinfo_Nebel 2000;
BA_REL_ "GenSigTimeoutTime" BU_SG_REL_ ZR_MIB_TOP_ab_Gen3 SG_ 1120 VZE_Umweltinfo_Anhaengerbetrieb 2000;
BA_REL_ "GenSigTimeoutTime" BU_SG_REL_ ZR_MIB_TOP_ab_Gen3 SG_ 916 WBA_Fahrstufe_02 1600;
BA_REL_ "GenSigTimeoutTime" BU_SG_REL_ ZR_MIB_TOP_ab_Gen3 SG_ 916 WBA_eing_Gang_02 1600;
BA_REL_ "GenSigTimeoutTime" BU_SG_REL_ ZR_MIB_TOP_ab_Gen3 SG_ 916 WBA_Segeln_aktiv 1600;
BA_REL_ "GenSigTimeoutTime" BU_SG_REL_ ZR_MIB_TOP_ab_Gen3 SG_ 916 WBA_GE_Zusatzwarnungen 1600;
BA_REL_ "GenSigTimeoutTime" BU_SG_REL_ ZR_MIB_TOP_ab_Gen3 SG_ 916 GE_Sollgang 1600;
BA_REL_ "GenSigTimeoutTime" BU_SG_REL_ ZR_MIB_TOP_ab_Gen3 SG_ 1361 WFS_Schluessel_Fahrberecht 2000;
BA_REL_ "GenSigTimeoutTime" BU_SG_REL_ ZR_MIB_TOP_ab_Gen3 SG_ 1361 WFS_Schluessel_Soll 2000;
BA_REL_ "GenSigTimeoutTime" BU_SG_REL_ ZR_MIB_TOP_ab_Gen3 SG_ 1361 WFS_Schluessel_Ist 2000;
BA_REL_ "GenSigTimeoutTime" BU_SG_REL_ ZR_MIB_TOP_ab_Gen3 SG_ 1411 ZV_verriegelt_extern_soll 2000;
BA_REL_ "GenSigTimeoutTime" BU_SG_REL_ ZR_MIB_TOP_ab_Gen3 SG_ 1411 ZV_FT_offen 2000;
BA_REL_ "GenSigTimeoutTime" BU_SG_REL_ ZR_MIB_TOP_ab_Gen3 SG_ 1411 ZV_BT_offen 2000;
BA_REL_ "GenSigTimeoutTime" BU_SG_REL_ ZR_MIB_TOP_ab_Gen3 SG_ 1411 ZV_HFS_offen 2000;
BA_REL_ "GenSigTimeoutTime" BU_SG_REL_ ZR_MIB_TOP_ab_Gen3 SG_ 1411 ZV_HBFS_offen 2000;
BA_REL_ "GenSigTimeoutTime" BU_SG_REL_ ZR_MIB_TOP_ab_Gen3 SG_ 1411 ZV_HD_offen 2000;
BA_REL_ "GenSigTimeoutTime" BU_SG_REL_ ZR_MIB_TOP_ab_Gen3 SG_ 711 BCM2_ZV_Tasten_HMI_Anf 5000;
BA_REL_ "GenSigTimeoutTime" BU_SG_REL_ ZR_Standard SG_ 995 VS_VD_zu_ver 1000;
BA_REL_ "GenSigTimeoutTime" BU_SG_REL_ ZR_Standard SG_ 995 VS_VD_offen_ver 1000;
BA_REL_ "GenSigTimeoutTime" BU_SG_REL_ ZR_Standard SG_ 1716 VIN_01_MUX 2000;
BA_REL_ "GenSigTimeoutTime" BU_SG_REL_ ZR_Standard SG_ 1716 KS_Geheimnis_1 2000;
BA_REL_ "GenSigTimeoutTime" BU_SG_REL_ ZR_Standard SG_ 1716 VIN_4 2000;
BA_REL_ "GenSigTimeoutTime" BU_SG_REL_ ZR_Standard SG_ 1716 VIN_11 2000;
BA_REL_ "GenSigTimeoutTime" BU_SG_REL_ ZR_Standard SG_ 1716 KS_Geheimnis_2 2000;
BA_REL_ "GenSigTimeoutTime" BU_SG_REL_ ZR_Standard SG_ 1716 VIN_5 2000;
BA_REL_ "GenSigTimeoutTime" BU_SG_REL_ ZR_Standard SG_ 1716 VIN_12 2000;
BA_REL_ "GenSigTimeoutTime" BU_SG_REL_ ZR_Standard SG_ 1716 KS_Geheimnis_3 2000;
BA_REL_ "GenSigTimeoutTime" BU_SG_REL_ ZR_Standard SG_ 1716 VIN_6 2000;
BA_REL_ "GenSigTimeoutTime" BU_SG_REL_ ZR_Standard SG_ 1716 VIN_13 2000;
BA_REL_ "GenSigTimeoutTime" BU_SG_REL_ ZR_Standard SG_ 1716 KS_Geheimnis_4 2000;
BA_REL_ "GenSigTimeoutTime" BU_SG_REL_ ZR_Standard SG_ 1716 VIN_7 2000;
BA_REL_ "GenSigTimeoutTime" BU_SG_REL_ ZR_Standard SG_ 1716 VIN_14 2000;
BA_REL_ "GenSigTimeoutTime" BU_SG_REL_ ZR_Standard SG_ 1716 VIN_1 2000;
BA_REL_ "GenSigTimeoutTime" BU_SG_REL_ ZR_Standard SG_ 1716 VIN_8 2000;
BA_REL_ "GenSigTimeoutTime" BU_SG_REL_ ZR_Standard SG_ 1716 VIN_15 2000;
BA_REL_ "GenSigTimeoutTime" BU_SG_REL_ ZR_Standard SG_ 1716 VIN_2 2000;
BA_REL_ "GenSigTimeoutTime" BU_SG_REL_ ZR_Standard SG_ 1716 VIN_9 2000;
BA_REL_ "GenSigTimeoutTime" BU_SG_REL_ ZR_Standard SG_ 1716 VIN_16 2000;
BA_REL_ "GenSigTimeoutTime" BU_SG_REL_ ZR_Standard SG_ 1716 VIN_3 2000;
BA_REL_ "GenSigTimeoutTime" BU_SG_REL_ ZR_Standard SG_ 1716 VIN_10 2000;
BA_REL_ "GenSigTimeoutTime" BU_SG_REL_ ZR_Standard SG_ 1716 VIN_17 2000;
BA_REL_ "GenSigTimeoutTime" BU_SG_REL_ ZR_Standard SG_ 668 VZE_Verkehrszeichen_4 2000;
BA_REL_ "GenSigTimeoutTime" BU_SG_REL_ ZR_Standard SG_ 668 VZE_Verkehrszeichen_5 2000;
BA_REL_ "GenSigTimeoutTime" BU_SG_REL_ ZR_Standard SG_ 916 WBA_Fahrstufe_02 1600;
BA_REL_ "GenSigTimeoutTime" BU_SG_REL_ ZR_Standard SG_ 916 WBA_eing_Gang_02 1600;
BA_REL_ "GenSigTimeoutTime" BU_SG_REL_ ZR_Standard SG_ 916 WBA_Segeln_aktiv 1600;
BA_REL_ "GenSigTimeoutTime" BU_SG_REL_ ZR_Standard SG_ 916 GE_Sollgang 1600;
BA_REL_ "GenSigTimeoutTime" BU_SG_REL_ ZR_Standard SG_ 916 GE_Tipschaltempf_verfuegbar 1600;
BA_REL_ "GenSigTimeoutTime" BU_SG_REL_ ZR_Standard SG_ 1361 WFS_Schluessel_Fahrberecht 2000;
BA_REL_ "GenSigTimeoutTime" BU_SG_REL_ ZR_Standard SG_ 1361 WFS_Schluessel_Soll 2000;
BA_REL_ "GenSigTimeoutTime" BU_SG_REL_ ZR_Standard SG_ 1361 WFS_Schluessel_Ist 2000;
BA_REL_ "GenSigTimeoutTime" BU_SG_REL_ ZR_Standard SG_ 1411 ZV_verriegelt_extern_soll 2000;
BA_REL_ "GenSigTimeoutTime" BU_SG_REL_ ZR_Standard SG_ 1411 ZV_FT_offen 2000;
BA_REL_ "GenSigTimeoutTime" BU_SG_REL_ ZR_Standard SG_ 1411 ZV_BT_offen 2000;
BA_REL_ "GenSigTimeoutTime" BU_SG_REL_ ZR_Standard SG_ 1411 ZV_HFS_offen 2000;
BA_REL_ "GenSigTimeoutTime" BU_SG_REL_ ZR_Standard SG_ 1411 ZV_HBFS_offen 2000;
BA_REL_ "GenSigTimeoutTime" BU_SG_REL_ ZR_Standard SG_ 1411 ZV_HD_offen 2000;
VAL_ 2589283609 UGDO_LED_Code_01 0 "Init" 1 "LED_green_on" 2 "LED_yellow_on" 3 "LED_red_on" 4 "LED_green_flashing_with_10_Hz" 5 "LED_yellow_flashing_with_1_Hz" 16 "LED_flashing_off" 17 "LED_green_flashing_1_x_1_Hz" 18 "LED_green_flashing_2_x_1_Hz" 19 "LED_green_flashing_3_x_1_Hz" 20 "LED_green_flashing_4_x_1_Hz" 21 "LED_green_flashing_5_x_1_Hz" 22 "LED_green_flashing_6_x_1_Hz" 23 "LED_green_flashing_7_x_1_Hz" 24 "LED_green_flashing_8_x_1_Hz" 25 "LED_green_flashing_9_x_1_Hz" 26 "LED_green_flashing_10_x_1_Hz" 27 "LED_green_flashing_11_x_1_Hz" 28 "LED_green_flashing_12_x_1_Hz" 29 "LED_green_flashing_13_x_1_Hz" 30 "LED_green_flashing_14_x_1_Hz" ;
VAL_ 2589283609 UGDO_Function_01 0 "LED Function" 1 "Transceiver locked" 2 "reserviert" 3 "reserviert" 4 "Successful learned" 5 "reserviert" 6 "Timeout learning" 7 "Fehler" ;
VAL_ 2589283609 UGDO_Failure_Antenne 0 "normal" 1 "Fehler" ;
VAL_ 2589283609 UGDO_Failure_Codierung 0 "normal" 1 "Fehler" ;
VAL_ 2589283609 UGDO_Failure_Hardware 0 "normal" 1 "Fehler" ;
VAL_ 2589283609 UGDO_ResponseError 0 "normal" 1 "Fehler" ;
VAL_ 2589283609 UGDO_Channel_1 0 "not_trained" 1 "trained" ;
VAL_ 2589283609 UGDO_Channel_2 0 "not_trained" 1 "trained" ;
VAL_ 2589283609 UGDO_Channel_3 0 "not_trained" 1 "trained" ;
VAL_ 2589283609 UGDO_Channel_4 0 "not_trained" 1 "trained" ;
VAL_ 2589283609 UGDO_Channel_5 0 "not_trained" 1 "trained" ;
VAL_ 2589283609 UGDO_Channel_6 0 "not_trained" 1 "trained" ;
VAL_ 2589283609 UGDO_Channel_7 0 "not_trained" 1 "trained" ;
VAL_ 2589283609 UGDO_Channel_8 0 "not_trained" 1 "trained" ;
VAL_ 2589283609 UGDO_Channel_9 0 "not_trained" 1 "trained" ;
VAL_ 2589283609 UGDO_Channel_10 0 "not_trained" 1 "trained" ;
VAL_ 2589283609 UGDO_Channel_11 0 "not_trained" 1 "trained" ;
VAL_ 2589283609 UGDO_Channel_12 0 "not_trained" 1 "trained" ;
VAL_ 2589283609 UGDO_Channel_13 0 "not_trained" 1 "trained" ;
VAL_ 2589283609 UGDO_Channel_14 0 "not_trained" 1 "trained" ;
VAL_ 2589283609 UGDO_Channel_15 0 "not_trained" 1 "trained" ;
VAL_ 2589283609 UGDO_DoorState 0 "idle" 1 "move" 2 "open" 3 "close" 4 "movement_stopped_stop_movement" 5 "no_com_door_out_of_reach" 6 "communication_error" ;
VAL_ 1718 UH_Typ 0 "undefiniert" 1 "Quarzuhr" 2 "DCF" 3 "GPS" ;
VAL_ 1718 UH_DLS 0 "Winterzeit" 1 "Sommerzeit" ;
VAL_ 1718 UH_Monat 0 "Init" 14 "Relatives_Datum" 15 "Fehler" ;
VAL_ 1718 UH_Tag 0 "Init" ;
VAL_ 995 VS_VD_zu_ver 1 "Zustand des Verdecks verriegelt und geschlossen" ;
VAL_ 995 VS_VD_entriegelt 1 "Zustand des Verdeck entriegelt" ;
VAL_ 995 VS_VD_offen_ver 0 "Init" 1 "Verdeck_verriegelt_und_offen" ;
VAL_ 995 VS_VD_Zwischenposition 1 "Verdeck in Zwischenposition" ;
VAL_ 995 VS_VD_Bew_auf 1 "Verdeck in Bewegung auf" ;
VAL_ 995 VS_VD_Bew_zu 1 "Verdeck in Bewegung zu" ;
VAL_ 995 VS_Hardtop 1 "Hardtop montiert" ;
VAL_ 995 VS_VD_Fehler 1 "Fehlerzustand Verdeck " ;
VAL_ 995 VS_Lampe_Blk 0 "Kontrollleuchte_inaktiv" 1 "Kontrollleuchte_aktiv" ;
VAL_ 995 VS_HD_sperren 0 "HD Entriegelung freigegeben" 1 "HD Entriegelung gesperrt" ;
VAL_ 995 VS_HHS_enable 0 "Init" 1 "Freigabe HHS" ;
VAL_ 995 VD_SpannungsAnf 0 "keine_Anforderung" 1 "Anforderung_Stufe1" 2 "Anforderung_Stufe2" 3 "Anforderung_Stufe3" ;
VAL_ 995 VS_VDKD_auf 0 "VDKD_nicht_vollst_auf" 1 "VDKD_vollstaendig_auf" ;
VAL_ 995 VS_FS_AutoHoch 0 "Keine_Verfahranforderung" 1 "Automatischer_Hochlauf" ;
VAL_ 995 VS_FS_AutoTief 0 "Keine_Verfahranforderung" 1 "Automatischer_Tieflauf" ;
VAL_ 995 VS_FS_ManHoch 0 "Keine_Verfahranforderung" 1 "Manueller_Hochlauf" ;
VAL_ 995 VS_FS_ManTief 0 "Keine_Verfahranforderung" 1 "Manueller_Tieflauf" ;
VAL_ 995 VS_BFS_AutoHoch 0 "Keine_Verfahranforderung" 1 "Automatischer_Hochlauf" ;
VAL_ 995 VS_BFS_AutoTief 0 "Keine_Verfahranforderung" 1 "Automatischer_Tieflauf" ;
VAL_ 995 VS_BFS_ManHoch 0 "Keine_Verfahranforderung" 1 "Manueller_Hochlauf" ;
VAL_ 995 VS_BFS_ManTief 0 "Keine_Verfahranforderung" 1 "Manueller_Tieflauf" ;
VAL_ 995 VS_HFS_AutoHoch 0 "Keine_Verfahranforderung" 1 "Automatischer_Hochlauf" ;
VAL_ 995 VS_HFS_AutoTief 0 "Keine_Verfahranforderung" 1 "Automatischer_Tieflauf" ;
VAL_ 995 VS_HFS_ManHoch 0 "Keine_Verfahranforderung" 1 "Manueller_Hochlauf" ;
VAL_ 995 VS_HFS_ManTief 0 "Keine_Verfahranforderung" 1 "Manueller_Tieflauf" ;
VAL_ 995 VS_HBFS_AutoHoch 0 "Keine_Verfahranforderung" 1 "Automatischer_Hochlauf" ;
VAL_ 995 VS_HBFS_AutoTief 0 "Keine_Verfahranforderung" 1 "Automatischer_Tieflauf" ;
VAL_ 995 VS_HBFS_ManHoch 0 "Keine_Verfahranforderung" 1 "Manueller_Hochlauf" ;
VAL_ 995 VS_HBFS_ManTief 0 "Keine_Verfahranforderung" 1 "Manueller_Tieflauf" ;
VAL_ 995 VS_FH_FT_Langhub 0 "Init" ;
VAL_ 995 VS_Windschott_nicht_abgelegt 0 "inaktiv" 1 "aktiv" ;
VAL_ 995 VS_FH_BT_Langhub 0 "Init" ;
VAL_ 995 VS_FH_HFS_Langhub 0 "Init" ;
VAL_ 995 VS_Heckschloss_auf 0 "kein_Oeffnen" 1 "Heckschloss_oeffnen" ;
VAL_ 995 VS_FH_HBFS_Langhub 0 "Init" ;
VAL_ 995 VSG_Meldungen 0 "keine_Meldung" ;
VAL_ 995 VS_StartStopp_Info 0 "Stoppfreigabe" 1 "Stoppverbot" 2 "Startanforderung" 3 "Fehler" ;
VAL_ 385 VZE_Anzeigemodus 0 "EU_RDW" 1 "USA" 2 "Canada" 3 "China" ;
VAL_ 385 VZE_Hinweistext 0 "kein_Hinweistext" ;
VAL_ 385 VZE_Verkehrszeichen_Einheit 0 "kmh" 1 "mph" ;
VAL_ 385 VZE_Anzeigeunterdrueck_Zeichen_3 0 "anzeigerelevant" 1 "nicht_anzeigerelevant" ;
VAL_ 385 VZE_Anzeigeunterdrueck_Zeichen_2 0 "anzeigerelevant" 1 "nicht_anzeigerelevant" ;
VAL_ 385 VZE_Verkehrszeichen_1 0 "kein_Verkehrszeichen" ;
VAL_ 385 VZE_Verkehrszeichen_2 0 "kein_Verkehrszeichen" ;
VAL_ 385 VZE_Verkehrszeichen_3 0 "kein_Verkehrszeichen" ;
VAL_ 385 VZE_Warnung_Verkehrszeichen_1 0 "keine_Warnung_Initialwert_Fehlerwert" 1 "Warnung" ;
VAL_ 385 VZE_Warnung_Verkehrszeichen_2 0 "keine_Warnung_Initialwert_Fehlerwert" 1 "Warnung" ;
VAL_ 385 VZE_Warnung_Verkehrszeichen_3 0 "keine_Warnung_Initialwert_Fehlerwert" 1 "Warnung" ;
VAL_ 385 VZE_Zusatzschild_1 0 "keine_Zusatzschild_Initialwert_Fehlerwert" ;
VAL_ 385 VZE_Zusatzschild_2 0 "keine_Zusatzschild_Initialwert_Fehlerwert" ;
VAL_ 385 VZE_Zusatzschild_3 0 "keine_Zusatzschild_Initialwert_Fehlerwert" ;
VAL_ 385 VZE_Anzeigeunterdrueck_Zeichen_1 0 "anzeigerelevant" 1 "nicht_anzeigerelevant" ;
VAL_ 385 VZE_Zeichen_01_KameraWied 0 "inaktiv" 1 "aktiv" ;
VAL_ 385 VZE_Zeichen_02_KameraWied 0 "inaktiv" 1 "aktiv" ;
VAL_ 385 VZE_Zeichen_03_KameraWied 0 "inaktiv" 1 "aktiv" ;
VAL_ 385 VZE_Zeichen_01_Kamera 0 "nicht_erkannt" 1 "erkannt" ;
VAL_ 385 VZE_Zeichen_01_Karte 0 "inaktiv" 1 "aktiv" ;
VAL_ 385 VZE_Zeichen_01_Gesetz 0 "nicht_erkannt" 1 "erkannt" ;
VAL_ 385 VZE_Zeichen_02_Kamera 0 "nicht_erkannt" 1 "erkannt" ;
VAL_ 385 VZE_Zeichen_02_Karte 0 "inaktiv" 1 "aktiv" ;
VAL_ 385 VZE_Zeichen_02_Gesetz 0 "nicht_erkannt" 1 "erkannt" ;
VAL_ 385 VZE_Zeichen_03_Kamera 0 "nicht_erkannt" 1 "erkannt" ;
VAL_ 385 VZE_Zeichen_03_Karte 0 "inaktiv" 1 "aktiv" ;
VAL_ 385 VZE_Zeichen_03_Gesetz 0 "nicht_erkannt" 1 "erkannt" ;
VAL_ 385 VZE_Gong 0 "Gong_deaktiv" 1 "Gong_aktiv" ;
VAL_ 668 VZE_Anzeigeunterdrueck_Zeichen_5 0 "anzeigerelevant" 1 "nicht_anzeigerelevant" ;
VAL_ 668 VZE_Zeichen_05_KameraWied 0 "inaktiv" 1 "aktiv" ;
VAL_ 668 VZE_Zeichen_05_Kamera 0 "nicht_erkannt" 1 "erkannt" ;
VAL_ 668 VZE_Verkehrszeichen_4 0 "kein_Verkehrszeichen" ;
VAL_ 668 VZE_Verkehrszeichen_5 0 "kein_Verkehrszeichen" ;
VAL_ 668 VZE_Anhaenger_Vmax 14 "Init" 15 "Fehler" ;
VAL_ 668 VZE_Zeichen_04_Gesetz 0 "nicht_erkannt" 1 "erkannt" ;
VAL_ 668 VZE_Zeichen_04_Kamera 0 "nicht_erkannt" 1 "erkannt" ;
VAL_ 668 VZE_Zeichen_04_KameraWied 0 "inaktiv" 1 "aktiv" ;
VAL_ 668 VZE_Zeichen_04_Karte 0 "inaktiv" 1 "aktiv" ;
VAL_ 668 VZE_Warnung_Verkehrszeichen_4 0 "keine_Warnung_Initialwert_Fehlerwert" 1 "Warnung" ;
VAL_ 668 VZE_Warnung_Verkehrszeichen_5 0 "keine_Warnung_Initialwert_Fehlerwert" 1 "Warnung" ;
VAL_ 668 VZE_Zeichen_05_Gesetz 0 "nicht_erkannt" 1 "erkannt" ;
VAL_ 668 VZE_Zusatzschild_4 0 "keine_Zusatzschild_Initialwert_Fehlerwert" ;
VAL_ 668 VZE_Zusatzschild_5 0 "keine_Zusatzschild_Initialwert_Fehlerwert" ;
VAL_ 668 VZE_Baustelle 0 "Keine_Baustelle" 1 "Baustelle_erkannt" ;
VAL_ 668 VZE_Zeichen_05_Karte 0 "inaktiv" 1 "aktiv" ;
VAL_ 668 VZE_Zeichen_05_Entfernung 0 "Init" ;
VAL_ 668 VZE_Zeichen_05_Entfernung_StdA 0 "Init" ;
VAL_ 668 VZE_Anzeigeunterdrueck_Zeichen_4 0 "anzeigerelevant" 1 "nicht_anzeigerelevant" ;
VAL_ 1120 VZE_Verkehrszeichen_6 0 "kein_Verkehrszeichen" ;
VAL_ 1120 VZE_Zusatzschild_6 0 "keine_Zusatzschild_Initialwert_Fehlerwert" ;
VAL_ 1120 VZE_Zeichen_06_Entfernung 0 "Init" ;
VAL_ 1120 VZE_Zeichen_06_Entfernung_StdA 0 "Init" ;
VAL_ 1120 VZE_Umweltinfo_Naesse 0 "inaktiv" 1 "aktiv" ;
VAL_ 1120 VZE_Umweltinfo_Nebel 0 "inaktiv" 1 "aktiv" ;
VAL_ 1120 VZE_Umweltinfo_Anhaengerbetrieb 0 "inaktiv" 1 "aktiv" ;
VAL_ 1120 VZE_Erweiterte_Information 0 "keine_Information" ;
VAL_ 1120 VZE_Tempowarnung_Status 0 "inaktiv" 1 "aktiv" ;
VAL_ 1120 VZE_Tempowarnung_Einheit 0 "kmh" 1 "mph" ;
VAL_ 1120 VZE_Tempowarnung_Offset 0 "Init" ;
VAL_ 916 WBA_Fahrstufe_02 0 "Zwischenstellung_keine_Position" 1 "Position_P" 2 "Position_R" 3 "Position_N" 4 "Position_D" 5 "Position_S" 6 "Position_M_Tippfunktion" 7 "Kurzzeit_M" 8 "Position_E" 9 "Position_MS" 10 "Position_S_Plus" 11 "Position_MS_Plus" 12 "Position_Offroad" 13 "Position_B" ;
VAL_ 916 WBA_ZielFahrstufe 0 "keine_Gangempfehlung_kein_Gang_eingelegt" 1 "Pfeil_nach_S" 2 "Pfeil_nach_D" 3 "Pfeil_nach_M" 4 "Pfeil_nach_E" ;
VAL_ 916 WBA_GE_Warnung_02 0 "keine_Anzeige" 1 "Fehlereskalationsstufe_I" 2 "Fehlereskalationsstufe_II" 3 "Weiterfahrt_nur_eingeschraenkt_moeglich__Kein_R_Gang" 4 "Getriebefehler_Weiterfahrt_nur_in_D_moeglich__P_bei_Motor_aus" 5 "Wegrollgefahr__P_nicht_moeglich" 6 "Paddlenotbetrieb_Schema+Warnung" 7 "Paddlenotbetrieb_Schema" 8 "Geschwindigkeitsbegrenzung_Notlauf" 9 "Fehlereskalationsst_o_Einschr" 10 "Fehlereskalationsstufe_v_Limit" 11 "Parksperre_Infostufe" 12 "Parksperre_Warnstufe_I" 13 "Parksperre_Warnstufe_II" ;
VAL_ 916 WBA_eing_Gang_02 0 "keine_Ganganzeige" 1 "Gang_1" 2 "Gang_2" 3 "Gang_3" 4 "Gang_4" 5 "Gang_5" 6 "Gang_6" 7 "Gang_7" 8 "Gang_8" 9 "Gang_9" 10 "Funktion_Ganganzeigeunterdrueckung" 11 "Gang_10" ;
VAL_ 916 WBA_GE_Texte 0 "keine_Anzeige" 1 "zum_Einlegen_einer_Fahrstufe_Fussbremse_betaetigen__ShiftLock_Information" 2 "zum_Einlegen_von_R_N_D_Fussbremse_betaetigen_und_Motor_starten" 3 "Wegrollgefahr_bitte_P_einlegen" 4 "Achtung_Zeitueberschreitung_P_wird_eingelegt" 5 "Wiederanmeldeprozedur_Bremse_betaetigen" 6 "P_nur_im_Stillstand_moeglich" 7 "Rennstart_aktiv" ;
VAL_ 916 WBA_Segeln_aktiv 0 "inaktiv" 1 "aktiv" ;
VAL_ 916 WBA_Schaltschema 0 "kein_Schaltschema" 1 "xxxD(S)" 2 "xxxD_S" 3 "xxxS(D)" 4 "xxxS_D" 5 "xxxM(D)" 6 "xxxM_D" 7 "xxxM(S)" 8 "xxxM_S" 9 "xxxE(D)" 10 "xxxE_D" 11 "xxxE(S)" 12 "xxxE_S" 13 "xxxE(M)" 14 "xxxE_M" ;
VAL_ 916 WBA_GE_Zusatzwarnungen 0 "keine_Anzeige" 1 "Getriebeueberhitzung_Warnstufe_I" 2 "Getriebeueberhitzung_Warnstufe_II" 3 "Getriebefehler_Bitte_anhalten_und_P_einlegen" ;
VAL_ 916 GE_Sollgang 0 "keine_Empfehlung" 1 "Gang_1" 2 "Gang_2" 3 "Gang_3" 4 "Gang_4" 5 "Gang_5" 6 "Gang_6" 7 "Gang_7" 8 "Gang_8" 9 "Gang_9" 11 "Gang_10" ;
VAL_ 916 GE_Tipschaltempf_verfuegbar 0 "nicht_verfuegbar" 1 "verfuegbar" ;
VAL_ 916 WBA_GE_Texte_02 0 "Keine_Anzeige" 1 "Fahrtrichtungswechsel_nur_nach_Stillstandt" 2 "Ladestecker_gesteckt" 3 "zusaetzlicher_Service_erforderlich" 4 "eLaunch_Aktiv" 5 "eLaunch_nicht_moeglich" 6 "WH_S_nicht_moeglich_Offroad" 7 "WH_S_nicht_moeglich_RangeMode" ;
VAL_ 916 WBA_GE_Texte_03 0 "init" 1 "LC_not_available" 2 "LCperformance_not_possible" 3 "LCperformance_possible" 4 "LCperformance_armed" 5 "LCperformance_preparation" 6 "LCperformance_launch" 7 "LCperformance_aborted" 8 "LCsmoke_not_possible" 9 "LCsmoke_possible" 10 "LCsmoke_armed" 11 "LCsmoke_launch" 12 "LCsmoke_aborted" 15 "Fehler" ;
VAL_ 916 WBA_Blinken 0 "kein_WBA_Blinken" 1 "WBA_Blinken" ;
VAL_ 916 GE_Wiederstart_Anz_Std 0 "keine_Anzeige" 1 "Standard_Wiederstartgrund" ;
VAL_ 916 GE_Stoppverbot_Anz_01 0 "keine_Anzeige" 1 "Temperaturbedingung" ;
VAL_ 916 GE_Stoppverbot_Anz_02 0 "keine_Anzeige" 1 "Drucksensorausfall" ;
VAL_ 916 GE_Stoppverbot_Anz_03 0 "keine_Anzeige" 1 "Grundeinstellung" ;
VAL_ 916 GE_Stoppverbot_Anz_04 0 "keine_Anzeige" 1 "Demontagestellung" ;
VAL_ 916 GE_Stoppverbot_Anz_05 0 "keine_Anzeige" 1 "Eingeschraenkte_Fahrfunktion_Notlauf_Liegenbleiber" ;
VAL_ 916 GE_Stoppverbot_Anz_06 0 "keine_Anzeige" 1 "Stoppverbot_ueber_Applikation" ;
VAL_ 916 GE_Stoppverbot_Anz_07 0 "keine_Anzeige" 1 "Schaltung_aktiv" ;
VAL_ 916 GE_Stoppverbot_Anz_Std 0 "keine_Anzeige" 1 "Standard_Stoppvetogrund" ;
VAL_ 1361 WFS_Schluessel_Fahrberecht 0 "kein authorisierter Schluessel erkannt" 1 "aktive_Funkschluessel_Nr_01" 2 "aktive_Funkschluessel_Nr_02" 3 "aktive_Funkschluessel_Nr_03" 4 "aktive_Funkschluessel_Nr_04" 5 "aktive_Funkschluessel_Nr_05" 6 "aktive_Funkschluessel_Nr_06" 7 "aktive_Funkschluessel_Nr_07" 8 "aktive_Funkschluessel_Nr_08" 9 "ungueltig_09" 10 "ungueltig_10" 11 "ungueltig_11" 12 "ungueltig_12" 13 "ungueltig_13" 14 "ungueltig_14" 15 "digitaler_Schluessel_aktiv" ;
VAL_ 1361 WFS_ID_Geb_autorisiert 0 "Schluessel_nicht_authorisiert" 1 "Schluessel authorisiert" ;
VAL_ 1361 WFS_ID_Geb_autorisiert_in_Kl15 0 "nicht_authorisiert_in_Kl15" 1 "authorisiert_in_Kl15" ;
VAL_ 1361 WFS_ID_Geb_steckt 0 "kein_Schluessel_im_Zuendschloss" 1 " Schluessel steckt im Zuendschloss" ;
VAL_ 1361 WFS_Schluessel_Soll 0 "Init" ;
VAL_ 1361 WFS_Schluessel_Ist 0 "Init" ;
VAL_ 1361 WFS_Safe 0 "Init" 1 "WFS nicht deaktiviert" ;
VAL_ 1361 WFS_LZ 0 "nicht def." 1 "LZ 1" 2 "LZ 2" 3 "LZ 3" ;
VAL_ 1361 WFS_ELV_authorisiert 0 "ELV_nicht_authorisiert" 1 "ELV_authorisiert" ;
VAL_ 1361 WFS_LF_Aktiv 0 "Funktempfang_nicht_aktiv" 1 "LF_Funkempfang_aktiv" ;
VAL_ 1361 WFS_Betrieb_Lesespule 0 "keine_Schluesselkomm_Lesespule" 1 "Schluesselkomm_Lesespule" ;
VAL_ 1361 WFS_Klemmenfreigabe 0 "keine_Freigabe" 1 "Freigabe" ;
VAL_ 1361 WFS_Fahrerhinweise 0 "Keine_Anzeigeanforderung" 1 "Schuessel_Auth_niO" 2 "Notlauf_aktiv" 3 "Schluessel_Kessy_nicht_gefunden" ;
VAL_ 1361 WFS_Parken_Status 0 "Limitierung_inaktiv" 1 "Limitierung_aktiv" 2 "Abbruch" ;
VAL_ 1702 Wischer_vorne_aktiv 0 "Init" 1 "Wischer_vorne_laeuft" ;
VAL_ 1702 Waschen_vorne_aktiv 1 "Waschen aktiv" ;
VAL_ 1702 Wischer_vorne_Normal 1 "Wischer Front normal aktiv" ;
VAL_ 1702 Wischer_vorne_Schnell 1 "Wischer vorne schnell aktiv" ;
VAL_ 1702 Wischer_vorne_Parklage 0 "Wischer_Front_nicht_in_Parklage" 1 "Wischer_Front_in_Parklage__Initialzustand" ;
VAL_ 1702 Wischer_vorne_defekt 0 "Init" 1 "Wischer vorne defekt" ;
VAL_ 1702 Wischer_vorne_blockiert 1 "Wischer vorne blockiert" ;
VAL_ 1702 Wischer1_Wischgeschwindigkeit 0 "0 U/min" 62 "Init" 63 "Fehler" ;
VAL_ 1702 BCM1_SRA_aktiv 0 "nicht aktiv" 1 "aktiv" ;
VAL_ 1702 Heckwischer_Anforderung 0 "Aus" 1 "Ein" ;
VAL_ 1702 WWSs_01_upd 0 "nicht_aktuell" 1 "aktuell" ;
VAL_ 1702 Wischer_Anzeigetext 0 "keine_Anzeige" 1 "Hinweis_Service_Position" 2 "void" 3 "void" ;
VAL_ 2527679496 WIV_Verschleissindex_Ueberlauf 0 "kein_Ueberlauf" 1 "min_1_Zaehlerueberlauf" ;
VAL_ 2527679496 WIV_Russindex_Ueberlauf 0 "kein_Ueberlauf" 1 "min_1_Zaehlerueberlauf" ;
VAL_ 2589283611 WLC1_Fremdobjekt_erkannt 0 "no_Foreign_object" 1 "Foreign_object_detected" ;
VAL_ 2589283611 WLC1_Objekt_erkannt 0 "no_Device_in_Tray" 1 "non_WLC_Device_in_Tray" ;
VAL_ 2589283611 WLC1_Receiver_erkannt 0 "no_Device_in_tray" 1 "WLC_Device_in_tray" ;
VAL_ 2589283611 WLC1_Receiver_voll_geladen 0 "WLC_not_fully_charged" 1 "WLC_Device_fully_charged" ;
VAL_ 1140 ZR_State_DU_1 0 "Disp_Off" 1 "Disp_On" 2 "LowPow" ;
VAL_ 1140 ZR_State_DU_2 0 "Disp_Off" 1 "Disp_On" 2 "LowPow" ;
VAL_ 1140 ZR_State_DU_3 0 "Disp_Off" 1 "Disp_On" 2 "LowPow" ;
VAL_ 1140 ZR_WecktGesp 0 "entsperrt" 1 "gesperrt" ;
VAL_ 1140 MMI_State 0 "MMI_OFF" 1 "MMI_IOC" 2 "MMI_STDBY" 3 "MMI_ON" 4 "MMI_STDBY_PWR_SAVE" 5 "MMI_STDBY_RESTR" 6 "MMI_ON_DIAG" 7 "MMI_ON_TEL" 8 "MMI_ON_SWDL" 9 "MMI_ON_CUST_SWDL" 10 "MMI_STDBY_PWR_SAVE_1" 11 "MMI_STDBY_PWR_SAVE_2" 12 "MMI_STANDBY_CUST_SWDL" 13 "MMI_ONLINE_IOC" 14 "MMI_ONLINE" 15 "MMI_PHONE_IOC" 16 "MMI_PHONE" 17 "MMI_RTC" 18 "MMI_DCI" ;
VAL_ 1140 ZR_DimOffs_DU_1 14 "Init" ;
VAL_ 1140 ZR_DimOffs_DU_2 14 "Init" ;
VAL_ 1140 ZR_DimOffs_DU_3 14 "Init" ;
VAL_ 1140 SI_ICAN 0 "keine_Busruhe" 1 "Busruhe" ;
VAL_ 1140 ZR_Lenkerposition 0 "links" 1 "rechts" ;
VAL_ 1140 WLC1_Systemzustand 0 "Wireless_Charger_off" 1 "Wireless_Charger_on" ;
VAL_ 1140 WLC2_Systemzustand 0 "Wireless_Charger_off" 1 "Wireless_Charger_on" ;
VAL_ 1140 ZR_SpannungSaeule 0 "Spannung_800V" 1 "Spannung_400V" ;
VAL_ 1140 ZR_LeistungSaeule 0 "Leistung_0_bis_50kW" 1 "Leistung_50_bis_100kW" 2 "Leistung_100_bis_150kW" 3 "Leistung_groesser_150kW" ;
VAL_ 1140 ZR_State_DU_4 0 "Disp_Off" 1 "Disp_On" 2 "LowPow" ;
VAL_ 1140 ZR_DimOffs_DU_4 14 "Init" ;
VAL_ 2589283477 MMI_State 0 "MMI_OFF" 1 "MMI_IOC" 2 "MMI_STDBY" 3 "MMI_ON" 4 "MMI_STDBY_PWR_SAVE" 5 "MMI_STDBY_RESTR" 6 "MMI_ON_DIAG" 7 "MMI_ON_TEL" 8 "MMI_ON_SWDL" 9 "MMI_ON_CUST_SWDL" 10 "MMI_STDBY_PWR_SAVE_1" 11 "MMI_STDBY_PWR_SAVE_2" 12 "MMI_STANDBY_CUST_SWDL" 13 "MMI_ONLINE_IOC" 14 "MMI_ONLINE" 15 "MMI_PHONE_IOC" 16 "MMI_PHONE" 17 "MMI_RTC" 18 "MMI_DCI" ;
VAL_ 2589283477 MU_MOST_State 0 "Licht_aus" 1 "Licht_an" ;
VAL_ 2527679655 MMI_StartupAnimation 0 "Init" 1 "MIBReadyForCommunication" 2 "MIBReadyForAnimation" 3 "RequestCancelAnimation" 4 "MIBAnimationStarted" 5 "MIBAnimationStopped" 6 "ReplyMeasureDelay" ;
VAL_ 389 ZFH_FS_ManHoch 0 "Keine_Verfahranforderung" 1 "Manueller_Hochlauf" ;
VAL_ 389 ZFH_FS_AutoHoch 0 "Keine_Verfahranforderung" 1 "Automatischer_Hochlauf" ;
VAL_ 389 ZFH_FS_ManTief 0 "Keine_Verfahranforderung" 1 "Manueller_Tieflauf" ;
VAL_ 389 ZFH_FS_AutoTief 0 "Keine_Verfahranforderung" 1 "Automatischer_Tieflauf" ;
VAL_ 389 ZFH_BFS_ManHoch 0 "Keine_Verfahranforderung" 1 "Manueller_Hochlauf" ;
VAL_ 389 ZFH_BFS_AutoHoch 0 "Keine_Verfahranforderung" 1 "Automatischer_Hochlauf" ;
VAL_ 389 ZFH_BFS_ManTief 0 "Keine_Verfahranforderung" 1 "Manueller_Tieflauf" ;
VAL_ 389 ZFH_BFS_AutoTief 0 "Keine_Verfahranforderung" 1 "Automatischer_Tieflauf" ;
VAL_ 389 ZFH_HFS_ManHoch 0 "Keine_Verfahranforderung" 1 "Manueller_Hochlauf" ;
VAL_ 389 ZFH_HFS_AutoHoch 0 "Keine_Verfahranforderung" 1 "Automatischer_Hochlauf" ;
VAL_ 389 ZFH_HFS_ManTief 0 "Keine_Verfahranforderung" 1 "Manueller_Tieflauf" ;
VAL_ 389 ZFH_HFS_AutoTief 0 "Keine_Verfahranforderung" 1 "Automatischer_Tieflauf" ;
VAL_ 389 ZFH_HBFS_ManHoch 0 "Keine_Verfahranforderung" 1 "Manueller_Hochlauf" ;
VAL_ 389 ZFH_HBFS_AutoHoch 0 "Keine_Verfahranforderung" 1 "Automatischer_Hochlauf" ;
VAL_ 389 ZFH_HBFS_ManTief 0 "Keine_Verfahranforderung" 1 "Manueller_Tieflauf" ;
VAL_ 389 ZFH_HBFS_AutoTief 0 "Keine_Verfahranforderung" 1 "Automatischer_Tieflauf" ;
VAL_ 389 ZFH_zentral_zu 0 "Init" 1 "Fensterheber_zentral_zu" ;
VAL_ 389 ZFH_zentral_auf 0 "Init" 1 "Fensterheber_zentral_auf" ;
VAL_ 389 Krypt_Schluesselschalter_auf 0 "Schluesselschalter_nicht_betaetigt" 1 "Schluesselschalter_betaetigt" ;
VAL_ 389 Krypt_Schluesselschalter_zu 0 "Schluesselschalter_nicht_betaeti" 1 "Schluesselschalter_betaetigt" ;
VAL_ 392 BT_FH_BT_ManHoch 0 "Keine_Verfahranforderung" 1 "Manueller_Hochlauf" ;
VAL_ 392 BT_FH_BT_AutoHoch 0 "Keine_Verfahranforderung" 1 "Automatischer_Hochlauf" ;
VAL_ 392 BT_FH_BT_ManTief 0 "Keine_Verfahranforderung" 1 "Manueller_Tieflauf" ;
VAL_ 392 BT_FH_BT_AutoTief 0 "Kein_Verfahranforderung" 1 "Automatischer_Tieflauf" ;
VAL_ 392 BT_FH_FT_ManHoch 0 "Keine_Verfahranforderung" 1 "Manueller_Hochlauf" ;
VAL_ 392 BT_FH_FT_AutoHoch 0 "Keine_Verfahranforderung" 1 "Automatischer_Hochlauf" ;
VAL_ 392 BT_FH_FT_ManTief 0 "Keine_Verfahranforderung" 1 "Manueller_Tieflauf" ;
VAL_ 392 BT_FH_FT_AutoTief 0 "Keine_Verfahranforderung" 1 "Automatischer_Tieflauf" ;
VAL_ 392 BT_FH_HFS_ManHoch 0 "Keine_Verfahranforderung" 1 "Manueller_Hochlauf" ;
VAL_ 392 BT_FH_HFS_AutoHoch 0 "Keine_Verfahranforderung" 1 "Automatischer_Hochlauf" ;
VAL_ 392 BT_FH_HFS_ManTief 0 "Keine_Verfahranforderung" 1 "Manueller_Tieflauf" ;
VAL_ 392 BT_FH_HFS_AutoTief 0 "Keine_Verfahranforderung" 1 "Automatischer_Tieflauf" ;
VAL_ 392 BT_FH_HBFS_ManHoch 0 "Keine_Verfahranforderung" 1 "Manueller_Hochlauf" ;
VAL_ 392 BT_FH_HBFS_AutoHoch 0 "Keine_Verfahranforderung" 1 "Automatischer_Hochlauf" ;
VAL_ 392 BT_FH_HBFS_ManTief 0 "Keine_Verfahranforderung" 1 "Manueller_Tieflauf" ;
VAL_ 392 BT_FH_HBFS_AutoTief 0 "Keine_Verfahranforderung" 1 "Automatischer_Tieflauf" ;
VAL_ 392 BT_SP_hoch 0 "nicht_betaetigt" 1 "betaetigt" ;
VAL_ 392 BT_SP_tief 0 "nicht_betaetigt" 1 "betaetigt" ;
VAL_ 392 BT_SP_links 0 "nicht_betaetigt" 1 "betaetigt" ;
VAL_ 392 BT_SP_rechts 0 "nicht_betaetigt" 1 "betaetigt" ;
VAL_ 392 BT_SP_Garagenstellung 0 "Init" 1 "Spiegel_in_Garagenstellung" ;
VAL_ 392 BT_SP_Fahrstellung 0 "Init" 1 "Spiegel_ist_ausgeklappt" ;
VAL_ 392 BT_FH_zentral_zu 0 "Init" 1 "Fensterheber_zentral_zu" ;
VAL_ 392 BT_FH_zentral_auf 0 "Init" 1 "Fensterheber_zentral_auf" ;
VAL_ 388 ZV_FT_verriegeln 0 "FT_nicht_verriegeln" 1 "FT_verriegeln" ;
VAL_ 388 ZV_FT_entriegeln 0 "FT_nicht_entriegeln" 1 "FT_entriegeln" ;
VAL_ 388 ZV_BT_verriegeln 0 "BT_nicht_verriegeln" 1 "BT_verriegeln" ;
VAL_ 388 ZV_BT_entriegeln 0 "BT_nicht_entriegeln" 1 "BT_ist_zu_entriegeln" ;
VAL_ 388 ZV_HFS_verriegeln 0 "inaktiv" 1 "aktiv" ;
VAL_ 388 ZV_HFS_entriegeln 0 "inaktiv" 1 "aktiv" ;
VAL_ 388 ZV_HBFS_verriegeln 0 "inaktiv" 1 "aktiv" ;
VAL_ 388 ZV_HBFS_entriegeln 0 "inaktiv" 1 "aktiv" ;
VAL_ 388 ZV_zentral_safen 0 "nicht_safen" 1 "Befehl_zentral_safen" ;
VAL_ 388 ZV_zentral_entsafen 0 "Init" 1 "Befehl_zentral_entsafen" ;
VAL_ 388 ZV_Spg_Anklappen 0 "inaktiv" 1 "aktiv" ;
VAL_ 388 ZV_Softtouch_betaetigt 0 "Softtouch_nicht_betaetigt" 1 "Softtouch_betaetigt" ;
VAL_ 388 ZV_LED_Steuerung 0 "LED_aus" 1 "LED_ein" ;
VAL_ 388 ZV_LED_Uebernahme 0 "Init" 1 "TSG_uebernimmt_LED_Steuerung" ;
VAL_ 388 ZV_auf_FT 0 "nicht_betaetigt" 1 "betaetigt" ;
VAL_ 388 ZV_zu_FT 0 "nicht_betaetigt" 1 "betaetigt" ;
VAL_ 388 ZV_auf_BT 0 "nicht_betaetigt" 1 "betaetigt" ;
VAL_ 388 ZV_zu_BT 0 "nicht_betaetigt" 1 "betaetigt" ;
VAL_ 388 ZV_auf_Funk 0 "nicht_betaetigt" 1 "betaetigt" ;
VAL_ 388 ZV_zu_Funk 0 "nicht_betaetigt" 1 "betaetigt" ;
VAL_ 388 VIP_Sensor_betaetigt 0 "keine_Heckentriegelung_durch_VIP_Sensor_angefordert" 1 "Heckentriegelung_durch_VIP_Sensor_angefordert" ;
VAL_ 388 VIP_Freigabe 0 "keine_Freigabe" 1 "Freigabe" ;
VAL_ 388 ZV_zu_Zeitl_Nachverr 0 "Init" 1 "Nachverriegeln" ;
VAL_ 388 ZV_HSK_entriegeln 0 "Handschuhkasten nicht entriegeln" 1 "Handschuhkasten entriegeln" ;
VAL_ 388 ZV_HSK_verriegeln 0 "Handschuhkasten nicht verriegeln" 1 "Handschuhkasten_verriegelt" ;
VAL_ 388 ZV_Verdeck_zu 0 "inaktiv" 1 "aktiv" ;
VAL_ 388 ZV_Verdeck_auf 0 "inaktiv" 1 "aktiv" ;
VAL_ 388 FH_FT_hoch 0 "keine_Anforderung" 1 "FT_hoch" ;
VAL_ 388 FH_FT_tief 0 "keine_Anforderung" 1 "FT_tief" ;
VAL_ 388 FH_BT_hoch 0 "keine_Anforderung" 1 "BT_hoch" ;
VAL_ 388 FH_BT_tief 0 "keine_Anforderung" 1 "BT_tief" ;
VAL_ 388 FH_HFS_hoch 0 "inaktiv" 1 "aktiv" ;
VAL_ 388 FH_HFS_tief 0 "inaktiv" 1 "aktiv" ;
VAL_ 388 FH_HBFS_hoch 0 "inaktiv" 1 "aktiv" ;
VAL_ 388 FH_HBFS_tief 0 "inaktiv" 1 "aktiv" ;
VAL_ 388 BCM_Spg_Synchron 0 "inaktiv" 1 "aktiv" ;
VAL_ 388 BCM_BF_Spg_Absenkung 0 "inaktiv" 1 "aktiv" ;
VAL_ 388 ZV_entriegeln_Anf 0 "nicht_betaetigt" 1 "betaetigt" ;
VAL_ 388 ZV_auto_Ansteuerung 0 "Kein_Autolock_Unlock" 1 "Autolock_Unlock" ;
VAL_ 1411 BCM_FH_Freigabe 1 "Funktionsfreigabe Fensterheber" ;
VAL_ 1411 BCM_Komfortfkt_Freigabe 0 "Komfortfunktion gesperrt" 1 "globale Freigabe der Komfortfunktion erteilt" ;
VAL_ 1411 BCM_HSK_Freigabe 0 "erlauben" 1 "sperren" ;
VAL_ 1411 BCM_Verdeck_Freigabe 0 "Verdeckbetrieb nicht erlaubt" 1 "Verdeckbetrieb erlaubt" ;
VAL_ 1411 ZV_verriegelt_intern_ist 1 "Fahrzeug innen verriegelt; Istzustand" ;
VAL_ 1411 ZV_verriegelt_extern_ist 1 "Fahrzeug_aussen_verriegelt_Istzustand" ;
VAL_ 1411 ZV_verriegelt_intern_soll 1 "Fahrzeug verriegelt intern; Sollzusstand" ;
VAL_ 1411 ZV_verriegelt_extern_soll 1 "Fahrzeug verriegelt extern; Sollzusstand" ;
VAL_ 1411 ZV_gesafet_extern_ist 1 "Fahrzeug aussen gesafet; Istzustand" ;
VAL_ 1411 ZV_gesafet_extern_soll 1 "Fahrzeug_aussen_gesafet_Sollzustand" ;
VAL_ 1411 ZV_Einzeltuerentriegelung 1 "Fahrzeug an Einzeltuer entriegelt" ;
VAL_ 1411 ZV_Heckeinzelentriegelung 1 "Heckdeckeleinzelentriegelung" ;
VAL_ 1411 ZV_FT_offen 0 "FT_geschlossen" 1 "FT_geoeffnet" ;
VAL_ 1411 ZV_BT_offen 0 "BT_geschlossen" 1 "BT_geoeffnet" ;
VAL_ 1411 ZV_HFS_offen 0 "geschlossen" 1 "offen" ;
VAL_ 1411 ZV_HBFS_offen 0 "geschlossen" 1 "offen" ;
VAL_ 1411 ZV_HD_offen 1 "Heckdeckel_auf" ;
VAL_ 1411 ZV_HS_offen 0 "Heckscheibe_geschlossen" 1 "Heckscheibe auf" ;
VAL_ 1411 IRUE_aktiv 0 "unscharf" 1 "scharf" ;
VAL_ 1411 DWA_aktiv 0 "unscharf" 1 "scharf" ;
VAL_ 1411 HD_Hauptraste 0 "geschlossen" 1 "offen" ;
VAL_ 1411 HD_Vorraste 0 "geschlossen" 1 "offen" ;
VAL_ 1411 FFB_CarFinder 0 "nicht aktiv" 1 "aktiv" ;
VAL_ 1411 FFB_Komfortoeffnen 0 "kein_Komfortoeffnen_empfangen" 1 "Komfortoeffnen ueber Funk empfangen" ;
VAL_ 1411 FFB_Komfortschliessen 0 "kein_Komfortschliessen_empfangen" 1 "Komfortschliessen ueber Funk empfangen" ;
VAL_ 1411 ZV_Schluessel_Zugang 0 "kein_auth_Schluessel_erkannt" 1 "aktive_Funkschluessel_Nr_01" 2 "aktive_Funkschluessel_Nr_02" 3 "aktive_Funkschluessel_Nr_03" 4 "aktive_Funkschluessel_Nr_04" 5 "aktive_Funkschluessel_Nr_05" 6 "aktive_Funkschluessel_Nr_06" 7 "aktive_Funkschluessel_Nr_07" 8 "aktive_Funkschluessel_Nr_08" 9 "ungueltig_09" 10 "ungueltig_10" 11 "ungueltig_11" 12 "ungueltig_12" 13 "ungueltig_13" 14 "ungueltig_14" 15 "ungueltig_15" ;
VAL_ 1411 ZV_SafeFunktion_aktiv 0 "inaktiv" 1 "aktiv" ;
VAL_ 1411 FBS_Warn_Schluessel_Batt 0 "i.O." 1 "defekt" ;
VAL_ 1411 ZV_Oeffnungsmodus 0 "globale_Oeffnung" 1 "ZV_mit_Einzeltuerentr" 2 "ZV_individuell_selektiv" 3 "ZV_seitenselektiv" ;
VAL_ 1411 HFS_verriegelt 0 "nicht_verriegelt" 1 "verriegelt" ;
VAL_ 1411 HFS_gesafet 0 "nicht_gesafet" 1 "gesafet" ;
VAL_ 1411 HBFS_verriegelt 0 "nicht_verriegelt" 1 "verriegelt" ;
VAL_ 1411 HBFS_gesafet 0 "nicht_gesafet" 1 "gesafet" ;
VAL_ 1411 ZV_ist_Zustand_verfuegbar 0 "nicht_verfuegbar" 1 "verfuegbar_alle_TSGs_am_Bus" ;
VAL_ 1411 IRUE_Taster_Fkts_LED 0 "LED_aus" 1 "LED_ein" ;
VAL_ 1411 ZV_Tankklappe_offen 0 "Tankklappe_geschlossen" 1 "Tankklappe_offen" ;
VAL_ 1411 ZV_Rollo_auf 0 "inaktiv" 1 "aktiv" ;
VAL_ 1411 ZV_Rollo_zu 0 "inaktiv" 1 "aktiv" ;
VAL_ 1411 ZV_SAD_auf 0 "inaktiv" 1 "aktiv" ;
VAL_ 1411 ZV_SAD_zu 0 "inaktiv" 1 "aktiv" ;
VAL_ 1411 BCM_Tankklappensteller_Fehler 0 "kein_Fehler" 1 "Fehler" ;
VAL_ 1411 ZV_verriegelt_soll 0 "Init" 1 "nicht_verriegelt" 2 "verriegelt" ;
VAL_ 711 ZV_TAG_verfahren 0 "Init" 1 "Befehl_TAG_ausfahren" 2 "Befehl_TAG_einfahren" ;
VAL_ 711 BCM_Spg_Heizen_Trigger 0 "inaktiv" 1 "aktiv" ;
VAL_ 711 BCM2_ZV_Tasten_HMI_Anf 0 "ZV_Tasten_im_HMI_nicht_anzeigen" 1 "ZV_Tasten_im_HMI_anzeigen" ;
VAL_ 711 ZV_HD_Taste_zu 0 "Taste_HD_zu_nicht_gedrueckt" 1 "Taste_HD_zu_gedrueckt" ;
VAL_ 711 ZV_HD_Taste_auf 0 "Taste_HD_auf_nicht_gedrueckt" 1 "Taste_HD_auf_gedrueckt" ;
VAL_ 711 ZV_FD_Taste_auf 0 "Taste_FD_auf_nicht_gedrueckt" 1 "Taste_FD_auf_gedrueckt" ;
